VERSION ""

NS_ :

BS_:

BU_:

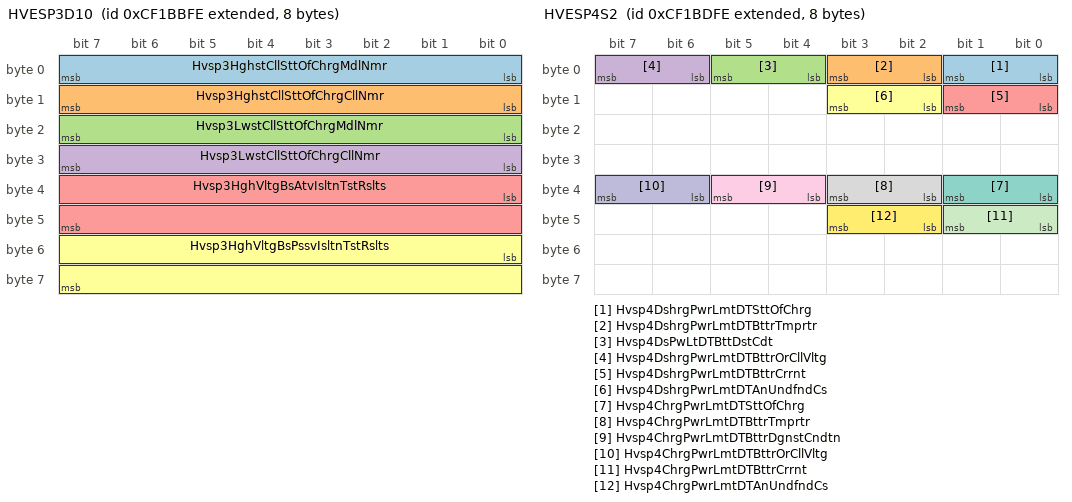
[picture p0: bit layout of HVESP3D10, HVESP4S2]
BO_ 2364652542 HVESP3D10: 8 Vector__XXX
 SG_ Hvsp3HghstCllSttOfChrgMdlNmr : 0|8@1+ (1,0) [0|250] "count" Vector__XXX
 SG_ Hvsp3HghstCllSttOfChrgCllNmr : 8|8@1+ (1,0) [0|250] "count" Vector__XXX
 SG_ Hvsp3LwstCllSttOfChrgMdlNmr : 16|8@1+ (1,0) [0|250] "count" Vector__XXX
 SG_ Hvsp3LwstCllSttOfChrgCllNmr : 24|8@1+ (1,0) [0|250] "count" Vector__XXX
 SG_ Hvsp3HghVltgBsAtvIsltnTstRslts : 32|16@1+ (0.1,0) [0|6425.5] "OhmPerV" Vector__XXX
 SG_ Hvsp3HghVltgBsPssvIsltnTstRslts : 48|16@1+ (0.1,0) [0|6425.5] "OhmPerV" Vector__XXX

BO_ 2364652798 HVESP3D11: 8 Vector__XXX
 SG_ Hvesp3ActualChargeRate : 32|16@1+ (0.05,0) [0|3212.75] "kW" Vector__XXX
 SG_ Hvsp3BsVltgNgtvTChsssGrndVltg : 0|16@1+ (0.05,0) [0|3212.75] "V" Vector__XXX
 SG_ Hvsp3VltgLvlNgtvTChsssGrndVltg : 16|16@1+ (0.05,0) [0|3212.75] "V" Vector__XXX

BO_ 2364653054 HVESP4S2: 8 Vector__XXX
 SG_ Hvsp4DshrgPwrLmtDTSttOfChrg : 0|2@1+ (1,0) [0|3] "" Vector__XXX
 SG_ Hvsp4DshrgPwrLmtDTBttrTmprtr : 2|2@1+ (1,0) [0|3] "" Vector__XXX
 SG_ Hvsp4DsPwLtDTBttDstCdt : 4|2@1+ (1,0) [0|3] "" Vector__XXX
 SG_ Hvsp4DshrgPwrLmtDTBttrOrCllVltg : 6|2@1+ (1,0) [0|3] "" Vector__XXX
 SG_ Hvsp4DshrgPwrLmtDTBttrCrrnt : 8|2@1+ (1,0) [0|3] "" Vector__XXX
 SG_ Hvsp4DshrgPwrLmtDTAnUndfndCs : 10|2@1+ (1,0) [0|3] "" Vector__XXX
 SG_ Hvsp4ChrgPwrLmtDTSttOfChrg : 32|2@1+ (1,0) [0|3] "" Vector__XXX
 SG_ Hvsp4ChrgPwrLmtDTBttrTmprtr : 34|2@1+ (1,0) [0|3] "" Vector__XXX
 SG_ Hvsp4ChrgPwrLmtDTBttrDgnstCndtn : 36|2@1+ (1,0) [0|3] "" Vector__XXX
 SG_ Hvsp4ChrgPwrLmtDTBttrOrCllVltg : 38|2@1+ (1,0) [0|3] "" Vector__XXX
 SG_ Hvsp4ChrgPwrLmtDTBttrCrrnt : 40|2@1+ (1,0) [0|3] "" Vector__XXX
 SG_ Hvsp4ChrgPwrLmtDTAnUndfndCs : 42|2@1+ (1,0) [0|3] "" Vector__XXX

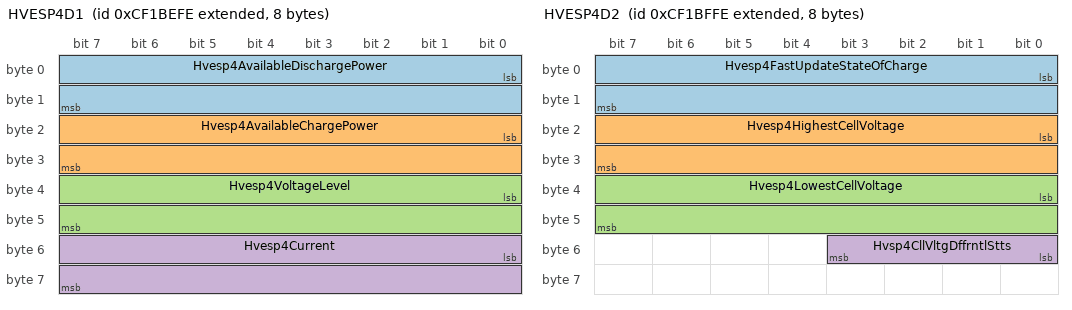
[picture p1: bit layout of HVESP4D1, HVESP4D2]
BO_ 2364653310 HVESP4D1: 8 Vector__XXX
 SG_ Hvesp4AvailableDischargePower : 0|16@1+ (0.05,0) [0|3212.75] "kW" Vector__XXX
 SG_ Hvesp4AvailableChargePower : 16|16@1+ (0.05,0) [0|3212.75] "kW" Vector__XXX
 SG_ Hvesp4VoltageLevel : 32|16@1+ (0.05,0) [0|3212.75] "V" Vector__XXX
 SG_ Hvesp4Current : 48|16@1+ (0.05,-1600) [-1600|1612.75] "A" Vector__XXX

BO_ 2364653566 HVESP4D2: 8 Vector__XXX
 SG_ Hvesp4FastUpdateStateOfCharge : 0|16@1+ (0.0015625,0) [0|100.3984375] "%" Vector__XXX
 SG_ Hvesp4HighestCellVoltage : 16|16@1+ (0.001,0) [0|64.255] "V" Vector__XXX
 SG_ Hvesp4LowestCellVoltage : 32|16@1+ (0.001,0) [0|64.255] "V" Vector__XXX
 SG_ Hvsp4CllVltgDffrntlStts : 48|4@1+ (1,0) [0|15] "" Vector__XXX

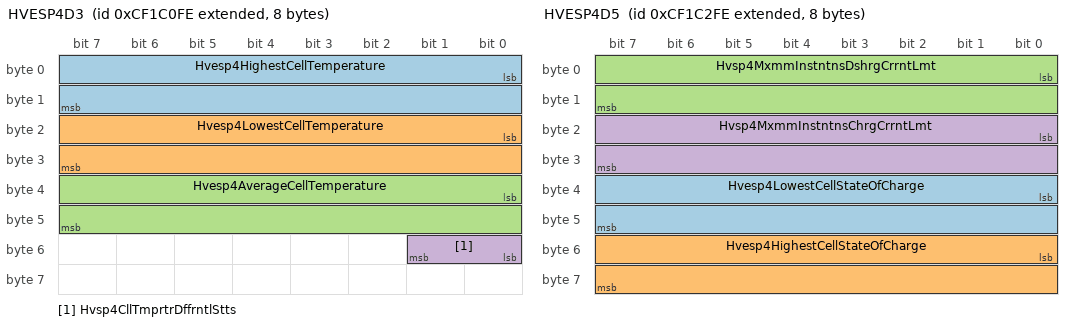
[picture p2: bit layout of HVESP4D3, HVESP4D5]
BO_ 2364653822 HVESP4D3: 8 Vector__XXX
 SG_ Hvesp4HighestCellTemperature : 0|16@1+ (0.03125,-273) [-273|1734.96875] "degC" Vector__XXX
 SG_ Hvesp4LowestCellTemperature : 16|16@1+ (0.03125,-273) [-273|1734.96875] "degC" Vector__XXX
 SG_ Hvesp4AverageCellTemperature : 32|16@1+ (0.03125,-273) [-273|1734.96875] "degC" Vector__XXX
 SG_ Hvsp4CllTmprtrDffrntlStts : 48|2@1+ (1,0) [0|3] "" Vector__XXX

BO_ 2364654078 HVESP4D4: 8 Vector__XXX
 SG_ Hvesp4DischargeCapacity : 0|16@1+ (0.01,0) [0|642.55] "Ah" Vector__XXX
 SG_ Hvesp4ChargeCapacity : 16|16@1+ (0.01,0) [0|642.55] "Ah" Vector__XXX
 SG_ Hvesp4CellBalancingCount : 32|16@1+ (1,0) [0|64255] "count" Vector__XXX

BO_ 2364654334 HVESP4D5: 8 Vector__XXX
 SG_ Hvesp4LowestCellStateOfCharge : 32|16@1+ (0.0015625,0) [0|100.3984375] "%" Vector__XXX
 SG_ Hvesp4HighestCellStateOfCharge : 48|16@1+ (0.0015625,0) [0|100.3984375] "%" Vector__XXX
 SG_ Hvsp4MxmmInstntnsDshrgCrrntLmt : 0|16@1+ (0.05,-1600) [-1600|0] "A" Vector__XXX
 SG_ Hvsp4MxmmInstntnsChrgCrrntLmt : 16|16@1+ (0.05,-1600) [0|1612.75] "A" Vector__XXX

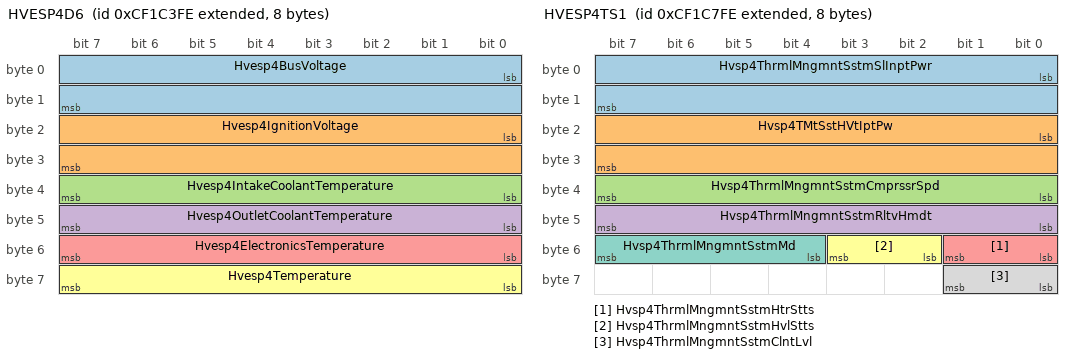
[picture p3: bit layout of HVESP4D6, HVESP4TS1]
BO_ 2364654590 HVESP4D6: 8 Vector__XXX
 SG_ Hvesp4BusVoltage : 0|16@1+ (0.05,0) [0|3212.75] "V" Vector__XXX
 SG_ Hvesp4IgnitionVoltage : 16|16@1+ (0.01,0) [0|642.55] "V" Vector__XXX
 SG_ Hvesp4IntakeCoolantTemperature : 32|8@1+ (1,-40) [-40|210] "degC" Vector__XXX
 SG_ Hvesp4OutletCoolantTemperature : 40|8@1+ (1,-40) [-40|210] "degC" Vector__XXX
 SG_ Hvesp4ElectronicsTemperature : 48|8@1+ (1,-40) [-40|210] "degC" Vector__XXX
 SG_ Hvesp4Temperature : 56|8@1+ (1,-40) [-40|210] "degC" Vector__XXX

BO_ 2364654846 HVESP4S1: 8 Vector__XXX
 SG_ Hvesp4HvilStatus : 20|2@1+ (1,0) [0|3] "" Vector__XXX
 SG_ Hvesp4InertiaSwitchStatus : 22|2@1+ (1,0) [0|3] "" Vector__XXX
 SG_ Hvesp4StateOfChargeStatus : 24|4@1+ (1,0) [0|15] "" Vector__XXX
 SG_ Hvesp4CellBalanceStatus : 28|2@1+ (1,0) [0|3] "" Vector__XXX
 SG_ Hvesp4CellBalancingActive : 30|2@1+ (1,0) [0|3] "" Vector__XXX
 SG_ Hvesp4InternalChargerStatus : 32|2@1+ (1,0) [0|3] "" Vector__XXX
 SG_ Hvesp4OperationalStatus : 44|4@1+ (1,0) [0|15] "" Vector__XXX
 SG_ Hvesp4Status1Counter : 52|4@1+ (1,0) [0|15] "" Vector__XXX
 SG_ Hvesp4Status1Crc : 56|8@1+ (1,0) [0|250] "count" Vector__XXX
 SG_ Hvsp4HghVltgBsPstvCnttrStt : 0|2@1+ (1,0) [0|3] "" Vector__XXX
 SG_ Hvsp4HghVltgBsNgtvCnttrStt : 2|2@1+ (1,0) [0|3] "" Vector__XXX
 SG_ Hvsp4HghVltgBsDsnntFrwrnng : 4|4@1+ (1,0) [0|15] "" Vector__XXX
 SG_ Hvsp4HghVltgBsPrChrgRlStt : 8|2@1+ (1,0) [0|3] "" Vector__XXX
 SG_ Hvsp4CntrOfPkCnttrStt : 10|2@1+ (1,0) [0|3] "" Vector__XXX
 SG_ Hvsp4HghVltgBsAtvIsltnTstStts : 12|4@1+ (1,0) [0|15] "" Vector__XXX
 SG_ Hvsp4HghVltgBsPssvIsltnTstStts : 16|4@1+ (1,0) [0|15] "" Vector__XXX
 SG_ Hvsp4HghVltgBsCnntnStts : 40|4@1+ (1,0) [0|15] "" Vector__XXX

BO_ 2364655102 HVESP4D7: 8 Vector__XXX
 SG_ Hvesp4DischargeEnergyCapacity : 0|24@1+ (0.001,0) [0|16449.535] "kWh" Vector__XXX
 SG_ Hvesp4ChargeEnergyCapacity : 24|24@1+ (0.001,0) [0|16449.535] "kWh" Vector__XXX
 SG_ Hvesp4MaximumChargeVoltageLimit : 48|16@1+ (0.05,0) [0|3212.75] "V" Vector__XXX

BO_ 2364655358 HVESP4MS1: 8 Vector__XXX
 SG_ Hvesp4Module1OperationalStatus : 0|2@1+ (1,0) [0|3] "" Vector__XXX
 SG_ Hvesp4Module2OperationalStatus : 2|2@1+ (1,0) [0|3] "" Vector__XXX
 SG_ Hvesp4Module3OperationalStatus : 4|2@1+ (1,0) [0|3] "" Vector__XXX
 SG_ Hvesp4Module4OperationalStatus : 6|2@1+ (1,0) [0|3] "" Vector__XXX
 SG_ Hvesp4Module5OperationalStatus : 8|2@1+ (1,0) [0|3] "" Vector__XXX
 SG_ Hvesp4Module6OperationalStatus : 10|2@1+ (1,0) [0|3] "" Vector__XXX
 SG_ Hvesp4Module7OperationalStatus : 12|2@1+ (1,0) [0|3] "" Vector__XXX
 SG_ Hvesp4Module8OperationalStatus : 14|2@1+ (1,0) [0|3] "" Vector__XXX
 SG_ Hvesp4Module9OperationalStatus : 16|2@1+ (1,0) [0|3] "" Vector__XXX
 SG_ Hvesp4Module10OperationalStatus : 18|2@1+ (1,0) [0|3] "" Vector__XXX
 SG_ Hvesp4Module11OperationalStatus : 20|2@1+ (1,0) [0|3] "" Vector__XXX
 SG_ Hvesp4Module12OperationalStatus : 22|2@1+ (1,0) [0|3] "" Vector__XXX
 SG_ Hvesp4Module13OperationalStatus : 24|2@1+ (1,0) [0|3] "" Vector__XXX
 SG_ Hvesp4Module14OperationalStatus : 26|2@1+ (1,0) [0|3] "" Vector__XXX
 SG_ Hvesp4Module15OperationalStatus : 28|2@1+ (1,0) [0|3] "" Vector__XXX
 SG_ Hvesp4Module16OperationalStatus : 30|2@1+ (1,0) [0|3] "" Vector__XXX
 SG_ Hvesp4Module17OperationalStatus : 32|2@1+ (1,0) [0|3] "" Vector__XXX
 SG_ Hvesp4Module18OperationalStatus : 34|2@1+ (1,0) [0|3] "" Vector__XXX
 SG_ Hvesp4Module19OperationalStatus : 36|2@1+ (1,0) [0|3] "" Vector__XXX
 SG_ Hvesp4Module20OperationalStatus : 38|2@1+ (1,0) [0|3] "" Vector__XXX
 SG_ Hvesp4Module21OperationalStatus : 40|2@1+ (1,0) [0|3] "" Vector__XXX
 SG_ Hvesp4Module22OperationalStatus : 42|2@1+ (1,0) [0|3] "" Vector__XXX
 SG_ Hvesp4Module23OperationalStatus : 44|2@1+ (1,0) [0|3] "" Vector__XXX
 SG_ Hvesp4Module24OperationalStatus : 46|2@1+ (1,0) [0|3] "" Vector__XXX
 SG_ Hvesp4Module25OperationalStatus : 48|2@1+ (1,0) [0|3] "" Vector__XXX
 SG_ Hvesp4Module26OperationalStatus : 50|2@1+ (1,0) [0|3] "" Vector__XXX
 SG_ Hvesp4Module27OperationalStatus : 52|2@1+ (1,0) [0|3] "" Vector__XXX
 SG_ Hvesp4Module28OperationalStatus : 54|2@1+ (1,0) [0|3] "" Vector__XXX
 SG_ Hvesp4Module29OperationalStatus : 56|2@1+ (1,0) [0|3] "" Vector__XXX
 SG_ Hvesp4Module30OperationalStatus : 58|2@1+ (1,0) [0|3] "" Vector__XXX
 SG_ Hvesp4Module31OperationalStatus : 60|2@1+ (1,0) [0|3] "" Vector__XXX
 SG_ Hvesp4Module32OperationalStatus : 62|2@1+ (1,0) [0|3] "" Vector__XXX

BO_ 2364655614 HVESP4TS1: 8 Vector__XXX
 SG_ Hvsp4ThrmlMngmntSstmSlInptPwr : 0|16@1+ (0.5,0) [0|32127.5] "W" Vector__XXX
 SG_ Hvsp4TMtSstHVtIptPw : 16|16@1+ (0.5,0) [0|32127.5] "W" Vector__XXX
 SG_ Hvsp4ThrmlMngmntSstmCmprssrSpd : 32|8@1+ (32,0) [0|8000] "rpm" Vector__XXX
 SG_ Hvsp4ThrmlMngmntSstmRltvHmdt : 40|8@1+ (0.4,0) [0|100] "%" Vector__XXX
 SG_ Hvsp4ThrmlMngmntSstmHtrStts : 48|2@1+ (1,0) [0|3] "" Vector__XXX
 SG_ Hvsp4ThrmlMngmntSstmHvlStts : 50|2@1+ (1,0) [0|3] "" Vector__XXX
 SG_ Hvsp4ThrmlMngmntSstmMd : 52|4@1+ (1,0) [0|15] "" Vector__XXX
 SG_ Hvsp4ThrmlMngmntSstmClntLvl : 56|2@1+ (1,0) [0|3] "" Vector__XXX

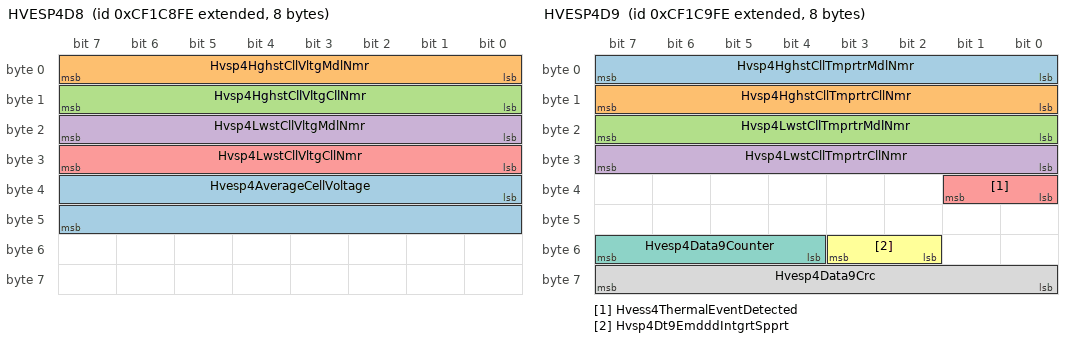
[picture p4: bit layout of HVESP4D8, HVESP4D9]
BO_ 2364655870 HVESP4D8: 8 Vector__XXX
 SG_ Hvesp4AverageCellVoltage : 32|16@1+ (0.001,0) [0|64.255] "V" Vector__XXX
 SG_ Hvsp4HghstCllVltgMdlNmr : 0|8@1+ (1,0) [0|250] "count" Vector__XXX
 SG_ Hvsp4HghstCllVltgCllNmr : 8|8@1+ (1,0) [0|250] "count" Vector__XXX
 SG_ Hvsp4LwstCllVltgMdlNmr : 16|8@1+ (1,0) [0|250] "count" Vector__XXX
 SG_ Hvsp4LwstCllVltgCllNmr : 24|8@1+ (1,0) [0|250] "count" Vector__XXX

BO_ 2364656126 HVESP4D9: 8 Vector__XXX
 SG_ Hvsp4HghstCllTmprtrMdlNmr : 0|8@1+ (1,0) [0|250] "count" Vector__XXX
 SG_ Hvsp4HghstCllTmprtrCllNmr : 8|8@1+ (1,0) [0|250] "count" Vector__XXX
 SG_ Hvsp4LwstCllTmprtrMdlNmr : 16|8@1+ (1,0) [0|250] "count" Vector__XXX
 SG_ Hvsp4LwstCllTmprtrCllNmr : 24|8@1+ (1,0) [0|250] "count" Vector__XXX
 SG_ Hvess4ThermalEventDetected : 32|2@1+ (1,0) [0|3] "" Vector__XXX
 SG_ Hvsp4Dt9EmdddIntgrtSpprt : 50|2@1+ (1,0) [0|3] "" Vector__XXX
 SG_ Hvesp4Data9Counter : 52|4@1+ (1,0) [0|15] "" Vector__XXX
 SG_ Hvesp4Data9Crc : 56|8@1+ (1,0) [0|250] "count" Vector__XXX

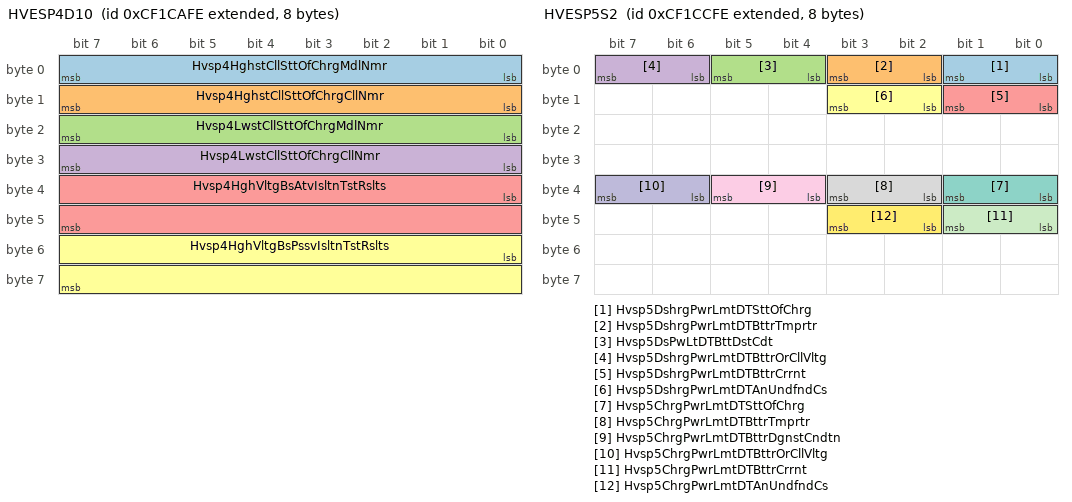
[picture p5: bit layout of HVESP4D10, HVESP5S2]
BO_ 2364656382 HVESP4D10: 8 Vector__XXX
 SG_ Hvsp4HghstCllSttOfChrgMdlNmr : 0|8@1+ (1,0) [0|250] "count" Vector__XXX
 SG_ Hvsp4HghstCllSttOfChrgCllNmr : 8|8@1+ (1,0) [0|250] "count" Vector__XXX
 SG_ Hvsp4LwstCllSttOfChrgMdlNmr : 16|8@1+ (1,0) [0|250] "count" Vector__XXX
 SG_ Hvsp4LwstCllSttOfChrgCllNmr : 24|8@1+ (1,0) [0|250] "count" Vector__XXX
 SG_ Hvsp4HghVltgBsAtvIsltnTstRslts : 32|16@1+ (0.1,0) [0|6425.5] "OhmPerV" Vector__XXX
 SG_ Hvsp4HghVltgBsPssvIsltnTstRslts : 48|16@1+ (0.1,0) [0|6425.5] "OhmPerV" Vector__XXX

BO_ 2364656638 HVESP4D11: 8 Vector__XXX
 SG_ Hvesp4ActualChargeRate : 32|16@1+ (0.05,0) [0|3212.75] "kW" Vector__XXX
 SG_ Hvsp4BsVltgNgtvTChsssGrndVltg : 0|16@1+ (0.05,0) [0|3212.75] "V" Vector__XXX
 SG_ Hvsp4VltgLvlNgtvTChsssGrndVltg : 16|16@1+ (0.05,0) [0|3212.75] "V" Vector__XXX

BO_ 2364656894 HVESP5S2: 8 Vector__XXX
 SG_ Hvsp5DshrgPwrLmtDTSttOfChrg : 0|2@1+ (1,0) [0|3] "" Vector__XXX
 SG_ Hvsp5DshrgPwrLmtDTBttrTmprtr : 2|2@1+ (1,0) [0|3] "" Vector__XXX
 SG_ Hvsp5DsPwLtDTBttDstCdt : 4|2@1+ (1,0) [0|3] "" Vector__XXX
 SG_ Hvsp5DshrgPwrLmtDTBttrOrCllVltg : 6|2@1+ (1,0) [0|3] "" Vector__XXX
 SG_ Hvsp5DshrgPwrLmtDTBttrCrrnt : 8|2@1+ (1,0) [0|3] "" Vector__XXX
 SG_ Hvsp5DshrgPwrLmtDTAnUndfndCs : 10|2@1+ (1,0) [0|3] "" Vector__XXX
 SG_ Hvsp5ChrgPwrLmtDTSttOfChrg : 32|2@1+ (1,0) [0|3] "" Vector__XXX
 SG_ Hvsp5ChrgPwrLmtDTBttrTmprtr : 34|2@1+ (1,0) [0|3] "" Vector__XXX
 SG_ Hvsp5ChrgPwrLmtDTBttrDgnstCndtn : 36|2@1+ (1,0) [0|3] "" Vector__XXX
 SG_ Hvsp5ChrgPwrLmtDTBttrOrCllVltg : 38|2@1+ (1,0) [0|3] "" Vector__XXX
 SG_ Hvsp5ChrgPwrLmtDTBttrCrrnt : 40|2@1+ (1,0) [0|3] "" Vector__XXX
 SG_ Hvsp5ChrgPwrLmtDTAnUndfndCs : 42|2@1+ (1,0) [0|3] "" Vector__XXX

BO_ 2364657150 HVESP5D1: 8 Vector__XXX
 SG_ Hvesp5AvailableDischargePower : 0|16@1+ (0.05,0) [0|3212.75] "kW" Vector__XXX
 SG_ Hvesp5AvailableChargePower : 16|16@1+ (0.05,0) [0|3212.75] "kW" Vector__XXX
 SG_ Hvesp5VoltageLevel : 32|16@1+ (0.05,0) [0|3212.75] "V" Vector__XXX
 SG_ Hvesp5Current : 48|16@1+ (0.05,-1600) [-1600|1612.75] "A" Vector__XXX

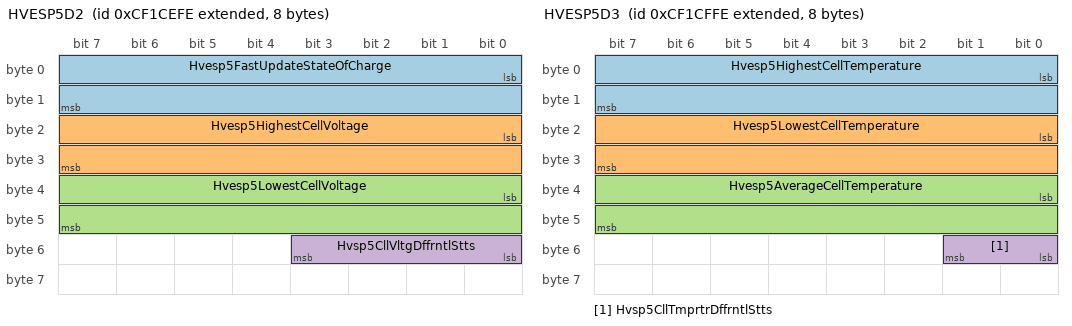
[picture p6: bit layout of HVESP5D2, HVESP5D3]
BO_ 2364657406 HVESP5D2: 8 Vector__XXX
 SG_ Hvesp5FastUpdateStateOfCharge : 0|16@1+ (0.0015625,0) [0|100.3984375] "%" Vector__XXX
 SG_ Hvesp5HighestCellVoltage : 16|16@1+ (0.001,0) [0|64.255] "V" Vector__XXX
 SG_ Hvesp5LowestCellVoltage : 32|16@1+ (0.001,0) [0|64.255] "V" Vector__XXX
 SG_ Hvsp5CllVltgDffrntlStts : 48|4@1+ (1,0) [0|15] "" Vector__XXX

BO_ 2364657662 HVESP5D3: 8 Vector__XXX
 SG_ Hvesp5HighestCellTemperature : 0|16@1+ (0.03125,-273) [-273|1734.96875] "degC" Vector__XXX
 SG_ Hvesp5LowestCellTemperature : 16|16@1+ (0.03125,-273) [-273|1734.96875] "degC" Vector__XXX
 SG_ Hvesp5AverageCellTemperature : 32|16@1+ (0.03125,-273) [-273|1734.96875] "degC" Vector__XXX
 SG_ Hvsp5CllTmprtrDffrntlStts : 48|2@1+ (1,0) [0|3] "" Vector__XXX

BO_ 2364657918 HVESP5D4: 8 Vector__XXX
 SG_ Hvesp5DischargeCapacity : 0|16@1+ (0.01,0) [0|642.55] "Ah" Vector__XXX
 SG_ Hvesp5ChargeCapacity : 16|16@1+ (0.01,0) [0|642.55] "Ah" Vector__XXX
 SG_ Hvesp5CellBalancingCount : 32|16@1+ (1,0) [0|64255] "count" Vector__XXX

BO_ 2364658174 HVESP5D5: 8 Vector__XXX
 SG_ Hvesp5LowestCellStateOfCharge : 32|16@1+ (0.0015625,0) [0|100.3984375] "%" Vector__XXX
 SG_ Hvesp5HighestCellStateOfCharge : 48|16@1+ (0.0015625,0) [0|100.3984375] "%" Vector__XXX
 SG_ Hvsp5MxmmInstntnsDshrgCrrntLmt : 0|16@1+ (0.05,-1600) [-1600|0] "A" Vector__XXX
 SG_ Hvsp5MxmmInstntnsChrgCrrntLmt : 16|16@1+ (0.05,-1600) [0|1612.75] "A" Vector__XXX

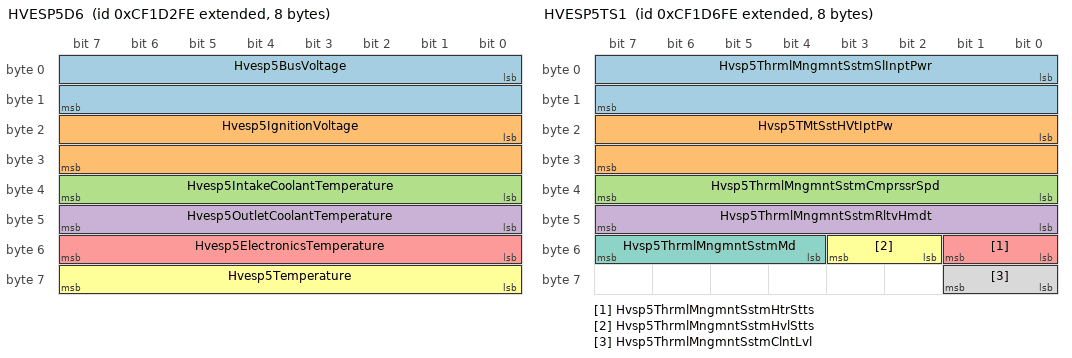
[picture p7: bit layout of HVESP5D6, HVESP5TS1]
BO_ 2364658430 HVESP5D6: 8 Vector__XXX
 SG_ Hvesp5BusVoltage : 0|16@1+ (0.05,0) [0|3212.75] "V" Vector__XXX
 SG_ Hvesp5IgnitionVoltage : 16|16@1+ (0.01,0) [0|642.55] "V" Vector__XXX
 SG_ Hvesp5IntakeCoolantTemperature : 32|8@1+ (1,-40) [-40|210] "degC" Vector__XXX
 SG_ Hvesp5OutletCoolantTemperature : 40|8@1+ (1,-40) [-40|210] "degC" Vector__XXX
 SG_ Hvesp5ElectronicsTemperature : 48|8@1+ (1,-40) [-40|210] "degC" Vector__XXX
 SG_ Hvesp5Temperature : 56|8@1+ (1,-40) [-40|210] "degC" Vector__XXX

BO_ 2364658686 HVESP5S1: 8 Vector__XXX
 SG_ Hvesp5HvilStatus : 20|2@1+ (1,0) [0|3] "" Vector__XXX
 SG_ Hvesp5InertiaSwitchStatus : 22|2@1+ (1,0) [0|3] "" Vector__XXX
 SG_ Hvesp5StateOfChargeStatus : 24|4@1+ (1,0) [0|15] "" Vector__XXX
 SG_ Hvesp5CellBalanceStatus : 28|2@1+ (1,0) [0|3] "" Vector__XXX
 SG_ Hvesp5CellBalancingActive : 30|2@1+ (1,0) [0|3] "" Vector__XXX
 SG_ Hvesp5InternalChargerStatus : 32|2@1+ (1,0) [0|3] "" Vector__XXX
 SG_ Hvesp5OperationalStatus : 44|4@1+ (1,0) [0|15] "" Vector__XXX
 SG_ Hvesp5Status1Counter : 52|4@1+ (1,0) [0|15] "" Vector__XXX
 SG_ Hvesp5Status1Crc : 56|8@1+ (1,0) [0|250] "count" Vector__XXX
 SG_ Hvsp5HghVltgBsPstvCnttrStt : 0|2@1+ (1,0) [0|3] "" Vector__XXX
 SG_ Hvsp5HghVltgBsNgtvCnttrStt : 2|2@1+ (1,0) [0|3] "" Vector__XXX
 SG_ Hvsp5HghVltgBsDsnntFrwrnng : 4|4@1+ (1,0) [0|15] "" Vector__XXX
 SG_ Hvsp5HghVltgBsPrChrgRlStt : 8|2@1+ (1,0) [0|3] "" Vector__XXX
 SG_ Hvsp5CntrOfPkCnttrStt : 10|2@1+ (1,0) [0|3] "" Vector__XXX
 SG_ Hvsp5HghVltgBsAtvIsltnTstStts : 12|4@1+ (1,0) [0|15] "" Vector__XXX
 SG_ Hvsp5HghVltgBsPssvIsltnTstStts : 16|4@1+ (1,0) [0|15] "" Vector__XXX
 SG_ Hvsp5HghVltgBsCnntnStts : 40|4@1+ (1,0) [0|15] "" Vector__XXX

BO_ 2364658942 HVESP5D7: 8 Vector__XXX
 SG_ Hvesp5DischargeEnergyCapacity : 0|24@1+ (0.001,0) [0|16449.535] "kWh" Vector__XXX
 SG_ Hvesp5ChargeEnergyCapacity : 24|24@1+ (0.001,0) [0|16449.535] "kWh" Vector__XXX
 SG_ Hvesp5MaximumChargeVoltageLimit : 48|16@1+ (0.05,0) [0|3212.75] "V" Vector__XXX

BO_ 2364659198 HVESP5MS1: 8 Vector__XXX
 SG_ Hvesp5Module1OperationalStatus : 0|2@1+ (1,0) [0|3] "" Vector__XXX
 SG_ Hvesp5Module2OperationalStatus : 2|2@1+ (1,0) [0|3] "" Vector__XXX
 SG_ Hvesp5Module3OperationalStatus : 4|2@1+ (1,0) [0|3] "" Vector__XXX
 SG_ Hvesp5Module4OperationalStatus : 6|2@1+ (1,0) [0|3] "" Vector__XXX
 SG_ Hvesp5Module5OperationalStatus : 8|2@1+ (1,0) [0|3] "" Vector__XXX
 SG_ Hvesp5Module6OperationalStatus : 10|2@1+ (1,0) [0|3] "" Vector__XXX
 SG_ Hvesp5Module7OperationalStatus : 12|2@1+ (1,0) [0|3] "" Vector__XXX
 SG_ Hvesp5Module8OperationalStatus : 14|2@1+ (1,0) [0|3] "" Vector__XXX
 SG_ Hvesp5Module9OperationalStatus : 16|2@1+ (1,0) [0|3] "" Vector__XXX
 SG_ Hvesp5Module10OperationalStatus : 18|2@1+ (1,0) [0|3] "" Vector__XXX
 SG_ Hvesp5Module11OperationalStatus : 20|2@1+ (1,0) [0|3] "" Vector__XXX
 SG_ Hvesp5Module12OperationalStatus : 22|2@1+ (1,0) [0|3] "" Vector__XXX
 SG_ Hvesp5Module13OperationalStatus : 24|2@1+ (1,0) [0|3] "" Vector__XXX
 SG_ Hvesp5Module14OperationalStatus : 26|2@1+ (1,0) [0|3] "" Vector__XXX
 SG_ Hvesp5Module15OperationalStatus : 28|2@1+ (1,0) [0|3] "" Vector__XXX
 SG_ Hvesp5Module16OperationalStatus : 30|2@1+ (1,0) [0|3] "" Vector__XXX
 SG_ Hvesp5Module17OperationalStatus : 32|2@1+ (1,0) [0|3] "" Vector__XXX
 SG_ Hvesp5Module18OperationalStatus : 34|2@1+ (1,0) [0|3] "" Vector__XXX
 SG_ Hvesp5Module19OperationalStatus : 36|2@1+ (1,0) [0|3] "" Vector__XXX
 SG_ Hvesp5Module20OperationalStatus : 38|2@1+ (1,0) [0|3] "" Vector__XXX
 SG_ Hvesp5Module21OperationalStatus : 40|2@1+ (1,0) [0|3] "" Vector__XXX
 SG_ Hvesp5Module22OperationalStatus : 42|2@1+ (1,0) [0|3] "" Vector__XXX
 SG_ Hvesp5Module23OperationalStatus : 44|2@1+ (1,0) [0|3] "" Vector__XXX
 SG_ Hvesp5Module24OperationalStatus : 46|2@1+ (1,0) [0|3] "" Vector__XXX
 SG_ Hvesp5Module25OperationalStatus : 48|2@1+ (1,0) [0|3] "" Vector__XXX
 SG_ Hvesp5Module26OperationalStatus : 50|2@1+ (1,0) [0|3] "" Vector__XXX
 SG_ Hvesp5Module27OperationalStatus : 52|2@1+ (1,0) [0|3] "" Vector__XXX
 SG_ Hvesp5Module28OperationalStatus : 54|2@1+ (1,0) [0|3] "" Vector__XXX
 SG_ Hvesp5Module29OperationalStatus : 56|2@1+ (1,0) [0|3] "" Vector__XXX
 SG_ Hvesp5Module30OperationalStatus : 58|2@1+ (1,0) [0|3] "" Vector__XXX
 SG_ Hvesp5Module31OperationalStatus : 60|2@1+ (1,0) [0|3] "" Vector__XXX
 SG_ Hvesp5Module32OperationalStatus : 62|2@1+ (1,0) [0|3] "" Vector__XXX

BO_ 2364659454 HVESP5TS1: 8 Vector__XXX
 SG_ Hvsp5ThrmlMngmntSstmSlInptPwr : 0|16@1+ (0.5,0) [0|32127.5] "W" Vector__XXX
 SG_ Hvsp5TMtSstHVtIptPw : 16|16@1+ (0.5,0) [0|32127.5] "W" Vector__XXX
 SG_ Hvsp5ThrmlMngmntSstmCmprssrSpd : 32|8@1+ (32,0) [0|8000] "rpm" Vector__XXX
 SG_ Hvsp5ThrmlMngmntSstmRltvHmdt : 40|8@1+ (0.4,0) [0|100] "%" Vector__XXX
 SG_ Hvsp5ThrmlMngmntSstmHtrStts : 48|2@1+ (1,0) [0|3] "" Vector__XXX
 SG_ Hvsp5ThrmlMngmntSstmHvlStts : 50|2@1+ (1,0) [0|3] "" Vector__XXX
 SG_ Hvsp5ThrmlMngmntSstmMd : 52|4@1+ (1,0) [0|15] "" Vector__XXX
 SG_ Hvsp5ThrmlMngmntSstmClntLvl : 56|2@1+ (1,0) [0|3] "" Vector__XXX

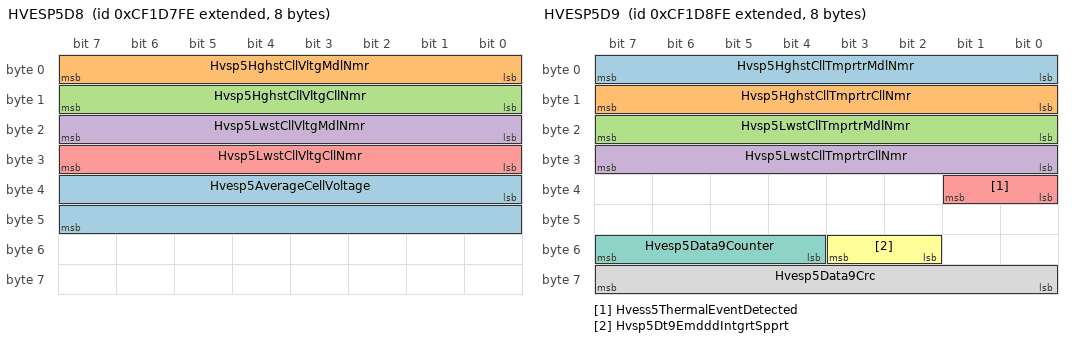
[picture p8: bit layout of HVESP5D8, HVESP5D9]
BO_ 2364659710 HVESP5D8: 8 Vector__XXX
 SG_ Hvesp5AverageCellVoltage : 32|16@1+ (0.001,0) [0|64.255] "V" Vector__XXX
 SG_ Hvsp5HghstCllVltgMdlNmr : 0|8@1+ (1,0) [0|250] "count" Vector__XXX
 SG_ Hvsp5HghstCllVltgCllNmr : 8|8@1+ (1,0) [0|250] "count" Vector__XXX
 SG_ Hvsp5LwstCllVltgMdlNmr : 16|8@1+ (1,0) [0|250] "count" Vector__XXX
 SG_ Hvsp5LwstCllVltgCllNmr : 24|8@1+ (1,0) [0|250] "count" Vector__XXX

BO_ 2364659966 HVESP5D9: 8 Vector__XXX
 SG_ Hvsp5HghstCllTmprtrMdlNmr : 0|8@1+ (1,0) [0|250] "count" Vector__XXX
 SG_ Hvsp5HghstCllTmprtrCllNmr : 8|8@1+ (1,0) [0|250] "count" Vector__XXX
 SG_ Hvsp5LwstCllTmprtrMdlNmr : 16|8@1+ (1,0) [0|250] "count" Vector__XXX
 SG_ Hvsp5LwstCllTmprtrCllNmr : 24|8@1+ (1,0) [0|250] "count" Vector__XXX
 SG_ Hvess5ThermalEventDetected : 32|2@1+ (1,0) [0|3] "" Vector__XXX
 SG_ Hvsp5Dt9EmdddIntgrtSpprt : 50|2@1+ (1,0) [0|3] "" Vector__XXX
 SG_ Hvesp5Data9Counter : 52|4@1+ (1,0) [0|15] "" Vector__XXX
 SG_ Hvesp5Data9Crc : 56|8@1+ (1,0) [0|250] "count" Vector__XXX

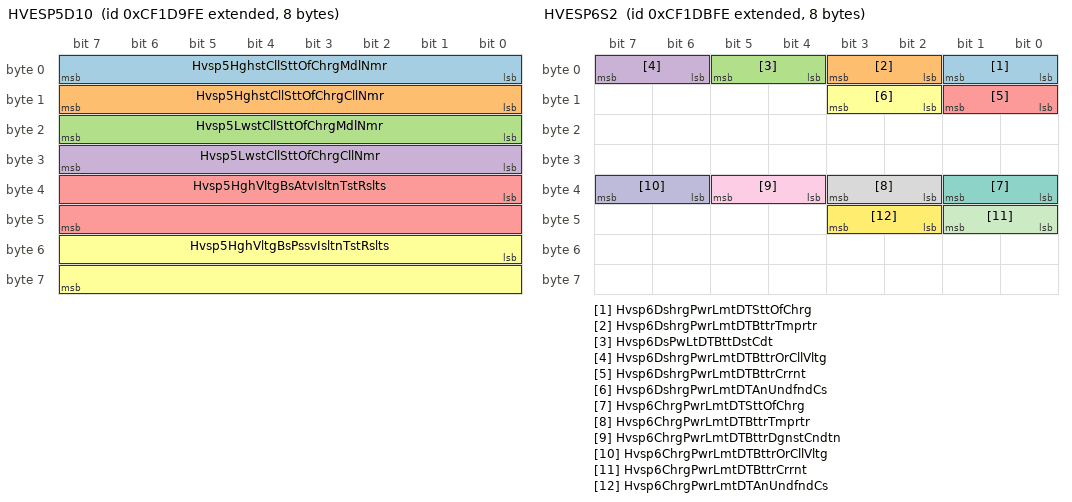
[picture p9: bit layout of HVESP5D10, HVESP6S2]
BO_ 2364660222 HVESP5D10: 8 Vector__XXX
 SG_ Hvsp5HghstCllSttOfChrgMdlNmr : 0|8@1+ (1,0) [0|250] "count" Vector__XXX
 SG_ Hvsp5HghstCllSttOfChrgCllNmr : 8|8@1+ (1,0) [0|250] "count" Vector__XXX
 SG_ Hvsp5LwstCllSttOfChrgMdlNmr : 16|8@1+ (1,0) [0|250] "count" Vector__XXX
 SG_ Hvsp5LwstCllSttOfChrgCllNmr : 24|8@1+ (1,0) [0|250] "count" Vector__XXX
 SG_ Hvsp5HghVltgBsAtvIsltnTstRslts : 32|16@1+ (0.1,0) [0|6425.5] "OhmPerV" Vector__XXX
 SG_ Hvsp5HghVltgBsPssvIsltnTstRslts : 48|16@1+ (0.1,0) [0|6425.5] "OhmPerV" Vector__XXX

BO_ 2364660478 HVESP5D11: 8 Vector__XXX
 SG_ Hvesp5ActualChargeRate : 32|16@1+ (0.05,0) [0|3212.75] "kW" Vector__XXX
 SG_ Hvsp5BsVltgNgtvTChsssGrndVltg : 0|16@1+ (0.05,0) [0|3212.75] "V" Vector__XXX
 SG_ Hvsp5VltgLvlNgtvTChsssGrndVltg : 16|16@1+ (0.05,0) [0|3212.75] "V" Vector__XXX

BO_ 2364660734 HVESP6S2: 8 Vector__XXX
 SG_ Hvsp6DshrgPwrLmtDTSttOfChrg : 0|2@1+ (1,0) [0|3] "" Vector__XXX
 SG_ Hvsp6DshrgPwrLmtDTBttrTmprtr : 2|2@1+ (1,0) [0|3] "" Vector__XXX
 SG_ Hvsp6DsPwLtDTBttDstCdt : 4|2@1+ (1,0) [0|3] "" Vector__XXX
 SG_ Hvsp6DshrgPwrLmtDTBttrOrCllVltg : 6|2@1+ (1,0) [0|3] "" Vector__XXX
 SG_ Hvsp6DshrgPwrLmtDTBttrCrrnt : 8|2@1+ (1,0) [0|3] "" Vector__XXX
 SG_ Hvsp6DshrgPwrLmtDTAnUndfndCs : 10|2@1+ (1,0) [0|3] "" Vector__XXX
 SG_ Hvsp6ChrgPwrLmtDTSttOfChrg : 32|2@1+ (1,0) [0|3] "" Vector__XXX
 SG_ Hvsp6ChrgPwrLmtDTBttrTmprtr : 34|2@1+ (1,0) [0|3] "" Vector__XXX
 SG_ Hvsp6ChrgPwrLmtDTBttrDgnstCndtn : 36|2@1+ (1,0) [0|3] "" Vector__XXX
 SG_ Hvsp6ChrgPwrLmtDTBttrOrCllVltg : 38|2@1+ (1,0) [0|3] "" Vector__XXX
 SG_ Hvsp6ChrgPwrLmtDTBttrCrrnt : 40|2@1+ (1,0) [0|3] "" Vector__XXX
 SG_ Hvsp6ChrgPwrLmtDTAnUndfndCs : 42|2@1+ (1,0) [0|3] "" Vector__XXX

BO_ 2364660990 HVESP6D1: 8 Vector__XXX
 SG_ Hvesp6AvailableDischargePower : 0|16@1+ (0.05,0) [0|3212.75] "kW" Vector__XXX
 SG_ Hvesp6AvailableChargePower : 16|16@1+ (0.05,0) [0|3212.75] "kW" Vector__XXX
 SG_ Hvesp6VoltageLevel : 32|16@1+ (0.05,0) [0|3212.75] "V" Vector__XXX
 SG_ Hvesp6Current : 48|16@1+ (0.05,-1600) [-1600|1612.75] "A" Vector__XXX

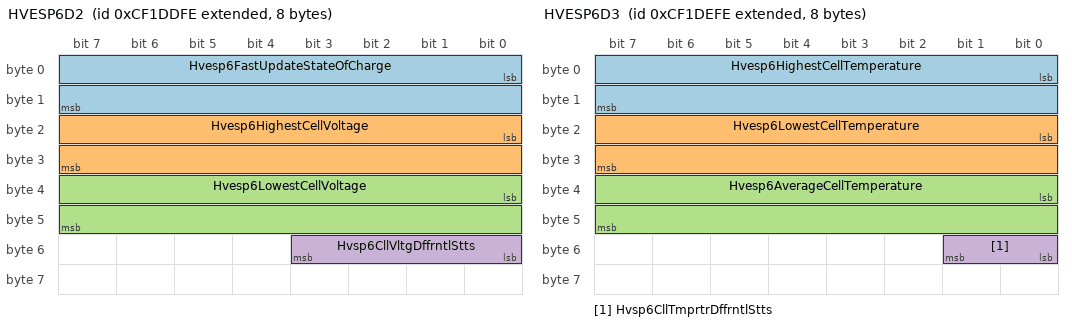
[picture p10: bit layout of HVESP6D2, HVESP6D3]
BO_ 2364661246 HVESP6D2: 8 Vector__XXX
 SG_ Hvesp6FastUpdateStateOfCharge : 0|16@1+ (0.0015625,0) [0|100.3984375] "%" Vector__XXX
 SG_ Hvesp6HighestCellVoltage : 16|16@1+ (0.001,0) [0|64.255] "V" Vector__XXX
 SG_ Hvesp6LowestCellVoltage : 32|16@1+ (0.001,0) [0|64.255] "V" Vector__XXX
 SG_ Hvsp6CllVltgDffrntlStts : 48|4@1+ (1,0) [0|15] "" Vector__XXX

BO_ 2364661502 HVESP6D3: 8 Vector__XXX
 SG_ Hvesp6HighestCellTemperature : 0|16@1+ (0.03125,-273) [-273|1734.96875] "degC" Vector__XXX
 SG_ Hvesp6LowestCellTemperature : 16|16@1+ (0.03125,-273) [-273|1734.96875] "degC" Vector__XXX
 SG_ Hvesp6AverageCellTemperature : 32|16@1+ (0.03125,-273) [-273|1734.96875] "degC" Vector__XXX
 SG_ Hvsp6CllTmprtrDffrntlStts : 48|2@1+ (1,0) [0|3] "" Vector__XXX

BO_ 2364661758 HVESP6D4: 8 Vector__XXX
 SG_ Hvesp6DischargeCapacity : 0|16@1+ (0.01,0) [0|642.55] "Ah" Vector__XXX
 SG_ Hvesp6ChargeCapacity : 16|16@1+ (0.01,0) [0|642.55] "Ah" Vector__XXX
 SG_ Hvesp6CellBalancingCount : 32|16@1+ (1,0) [0|64255] "count" Vector__XXX

BO_ 2364662014 HVESP6D5: 8 Vector__XXX
 SG_ Hvesp6LowestCellStateOfCharge : 32|16@1+ (0.0015625,0) [0|100.3984375] "%" Vector__XXX
 SG_ Hvesp6HighestCellStateOfCharge : 48|16@1+ (0.0015625,0) [0|100.3984375] "%" Vector__XXX
 SG_ Hvsp6MxmmInstntnsDshrgCrrntLmt : 0|16@1+ (0.05,-1600) [-1600|0] "A" Vector__XXX
 SG_ Hvsp6MxmmInstntnsChrgCrrntLmt : 16|16@1+ (0.05,-1600) [0|1612.75] "A" Vector__XXX

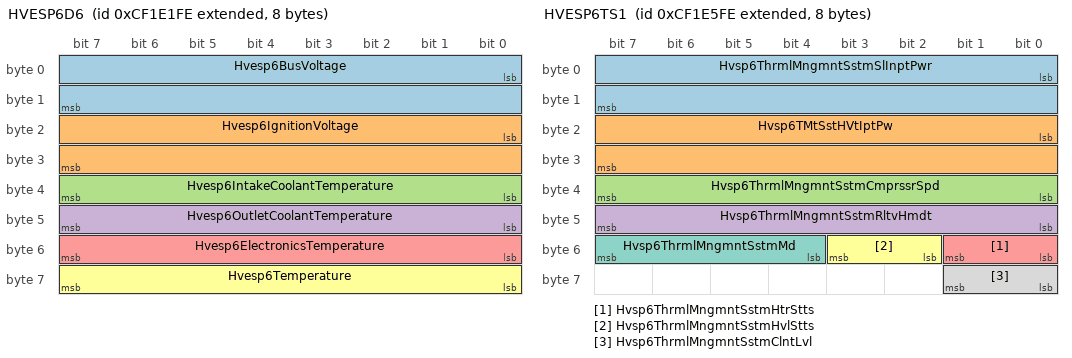
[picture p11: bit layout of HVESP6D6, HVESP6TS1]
BO_ 2364662270 HVESP6D6: 8 Vector__XXX
 SG_ Hvesp6BusVoltage : 0|16@1+ (0.05,0) [0|3212.75] "V" Vector__XXX
 SG_ Hvesp6IgnitionVoltage : 16|16@1+ (0.01,0) [0|642.55] "V" Vector__XXX
 SG_ Hvesp6IntakeCoolantTemperature : 32|8@1+ (1,-40) [-40|210] "degC" Vector__XXX
 SG_ Hvesp6OutletCoolantTemperature : 40|8@1+ (1,-40) [-40|210] "degC" Vector__XXX
 SG_ Hvesp6ElectronicsTemperature : 48|8@1+ (1,-40) [-40|210] "degC" Vector__XXX
 SG_ Hvesp6Temperature : 56|8@1+ (1,-40) [-40|210] "degC" Vector__XXX

BO_ 2364662526 HVESP6S1: 8 Vector__XXX
 SG_ Hvesp6HvilStatus : 20|2@1+ (1,0) [0|3] "" Vector__XXX
 SG_ Hvesp6InertiaSwitchStatus : 22|2@1+ (1,0) [0|3] "" Vector__XXX
 SG_ Hvesp6StateOfChargeStatus : 24|4@1+ (1,0) [0|15] "" Vector__XXX
 SG_ Hvesp6CellBalanceStatus : 28|2@1+ (1,0) [0|3] "" Vector__XXX
 SG_ Hvesp6CellBalancingActive : 30|2@1+ (1,0) [0|3] "" Vector__XXX
 SG_ Hvesp6InternalChargerStatus : 32|2@1+ (1,0) [0|3] "" Vector__XXX
 SG_ Hvesp6OperationalStatus : 44|4@1+ (1,0) [0|15] "" Vector__XXX
 SG_ Hvesp6Status1Counter : 52|4@1+ (1,0) [0|15] "" Vector__XXX
 SG_ Hvesp6Status1Crc : 56|8@1+ (1,0) [0|250] "count" Vector__XXX
 SG_ Hvsp6HghVltgBsPstvCnttrStt : 0|2@1+ (1,0) [0|3] "" Vector__XXX
 SG_ Hvsp6HghVltgBsNgtvCnttrStt : 2|2@1+ (1,0) [0|3] "" Vector__XXX
 SG_ Hvsp6HghVltgBsDsnntFrwrnng : 4|4@1+ (1,0) [0|15] "" Vector__XXX
 SG_ Hvsp6HghVltgBsPrChrgRlStt : 8|2@1+ (1,0) [0|3] "" Vector__XXX
 SG_ Hvsp6CntrOfPkCnttrStt : 10|2@1+ (1,0) [0|3] "" Vector__XXX
 SG_ Hvsp6HghVltgBsAtvIsltnTstStts : 12|4@1+ (1,0) [0|15] "" Vector__XXX
 SG_ Hvsp6HghVltgBsPssvIsltnTstStts : 16|4@1+ (1,0) [0|15] "" Vector__XXX
 SG_ Hvsp6HghVltgBsCnntnStts : 40|4@1+ (1,0) [0|15] "" Vector__XXX

BO_ 2364662782 HVESP6D7: 8 Vector__XXX
 SG_ Hvesp6DischargeEnergyCapacity : 0|24@1+ (0.001,0) [0|16449.535] "kWh" Vector__XXX
 SG_ Hvesp6ChargeEnergyCapacity : 24|24@1+ (0.001,0) [0|16449.535] "kWh" Vector__XXX
 SG_ Hvesp6MaximumChargeVoltageLimit : 48|16@1+ (0.05,0) [0|3212.75] "V" Vector__XXX

BO_ 2364663038 HVESP6MS1: 8 Vector__XXX
 SG_ Hvesp6Module1OperationalStatus : 0|2@1+ (1,0) [0|3] "" Vector__XXX
 SG_ Hvesp6Module2OperationalStatus : 2|2@1+ (1,0) [0|3] "" Vector__XXX
 SG_ Hvesp6Module3OperationalStatus : 4|2@1+ (1,0) [0|3] "" Vector__XXX
 SG_ Hvesp6Module4OperationalStatus : 6|2@1+ (1,0) [0|3] "" Vector__XXX
 SG_ Hvesp6Module5OperationalStatus : 8|2@1+ (1,0) [0|3] "" Vector__XXX
 SG_ Hvesp6Module6OperationalStatus : 10|2@1+ (1,0) [0|3] "" Vector__XXX
 SG_ Hvesp6Module7OperationalStatus : 12|2@1+ (1,0) [0|3] "" Vector__XXX
 SG_ Hvesp6Module8OperationalStatus : 14|2@1+ (1,0) [0|3] "" Vector__XXX
 SG_ Hvesp6Module9OperationalStatus : 16|2@1+ (1,0) [0|3] "" Vector__XXX
 SG_ Hvesp6Module10OperationalStatus : 18|2@1+ (1,0) [0|3] "" Vector__XXX
 SG_ Hvesp6Module11OperationalStatus : 20|2@1+ (1,0) [0|3] "" Vector__XXX
 SG_ Hvesp6Module12OperationalStatus : 22|2@1+ (1,0) [0|3] "" Vector__XXX
 SG_ Hvesp6Module13OperationalStatus : 24|2@1+ (1,0) [0|3] "" Vector__XXX
 SG_ Hvesp6Module14OperationalStatus : 26|2@1+ (1,0) [0|3] "" Vector__XXX
 SG_ Hvesp6Module15OperationalStatus : 28|2@1+ (1,0) [0|3] "" Vector__XXX
 SG_ Hvesp6Module16OperationalStatus : 30|2@1+ (1,0) [0|3] "" Vector__XXX
 SG_ Hvesp6Module17OperationalStatus : 32|2@1+ (1,0) [0|3] "" Vector__XXX
 SG_ Hvesp6Module18OperationalStatus : 34|2@1+ (1,0) [0|3] "" Vector__XXX
 SG_ Hvesp6Module19OperationalStatus : 36|2@1+ (1,0) [0|3] "" Vector__XXX
 SG_ Hvesp6Module20OperationalStatus : 38|2@1+ (1,0) [0|3] "" Vector__XXX
 SG_ Hvesp6Module21OperationalStatus : 40|2@1+ (1,0) [0|3] "" Vector__XXX
 SG_ Hvesp6Module22OperationalStatus : 42|2@1+ (1,0) [0|3] "" Vector__XXX
 SG_ Hvesp6Module23OperationalStatus : 44|2@1+ (1,0) [0|3] "" Vector__XXX
 SG_ Hvesp6Module24OperationalStatus : 46|2@1+ (1,0) [0|3] "" Vector__XXX
 SG_ Hvesp6Module25OperationalStatus : 48|2@1+ (1,0) [0|3] "" Vector__XXX
 SG_ Hvesp6Module26OperationalStatus : 50|2@1+ (1,0) [0|3] "" Vector__XXX
 SG_ Hvesp6Module27OperationalStatus : 52|2@1+ (1,0) [0|3] "" Vector__XXX
 SG_ Hvesp6Module28OperationalStatus : 54|2@1+ (1,0) [0|3] "" Vector__XXX
 SG_ Hvesp6Module29OperationalStatus : 56|2@1+ (1,0) [0|3] "" Vector__XXX
 SG_ Hvesp6Module30OperationalStatus : 58|2@1+ (1,0) [0|3] "" Vector__XXX
 SG_ Hvesp6Module31OperationalStatus : 60|2@1+ (1,0) [0|3] "" Vector__XXX
 SG_ Hvesp6Module32OperationalStatus : 62|2@1+ (1,0) [0|3] "" Vector__XXX

BO_ 2364663294 HVESP6TS1: 8 Vector__XXX
 SG_ Hvsp6ThrmlMngmntSstmSlInptPwr : 0|16@1+ (0.5,0) [0|32127.5] "W" Vector__XXX
 SG_ Hvsp6TMtSstHVtIptPw : 16|16@1+ (0.5,0) [0|32127.5] "W" Vector__XXX
 SG_ Hvsp6ThrmlMngmntSstmCmprssrSpd : 32|8@1+ (32,0) [0|8000] "rpm" Vector__XXX
 SG_ Hvsp6ThrmlMngmntSstmRltvHmdt : 40|8@1+ (0.4,0) [0|100] "%" Vector__XXX
 SG_ Hvsp6ThrmlMngmntSstmHtrStts : 48|2@1+ (1,0) [0|3] "" Vector__XXX
 SG_ Hvsp6ThrmlMngmntSstmHvlStts : 50|2@1+ (1,0) [0|3] "" Vector__XXX
 SG_ Hvsp6ThrmlMngmntSstmMd : 52|4@1+ (1,0) [0|15] "" Vector__XXX
 SG_ Hvsp6ThrmlMngmntSstmClntLvl : 56|2@1+ (1,0) [0|3] "" Vector__XXX

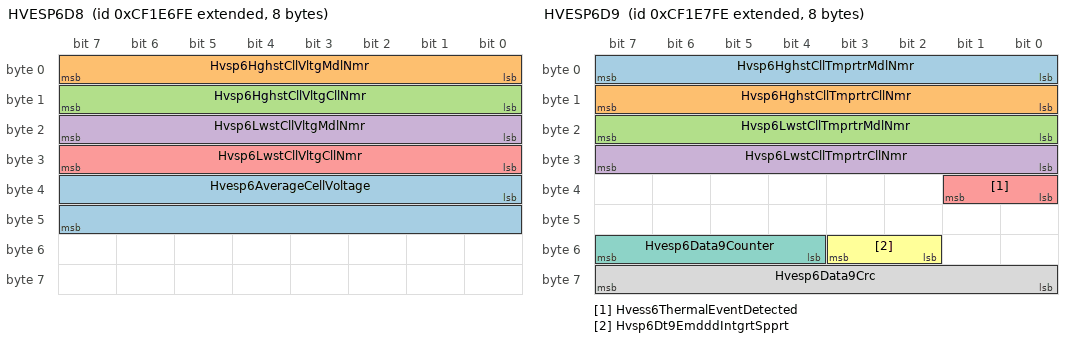
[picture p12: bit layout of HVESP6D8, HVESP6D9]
BO_ 2364663550 HVESP6D8: 8 Vector__XXX
 SG_ Hvesp6AverageCellVoltage : 32|16@1+ (0.001,0) [0|64.255] "V" Vector__XXX
 SG_ Hvsp6HghstCllVltgMdlNmr : 0|8@1+ (1,0) [0|250] "count" Vector__XXX
 SG_ Hvsp6HghstCllVltgCllNmr : 8|8@1+ (1,0) [0|250] "count" Vector__XXX
 SG_ Hvsp6LwstCllVltgMdlNmr : 16|8@1+ (1,0) [0|250] "count" Vector__XXX
 SG_ Hvsp6LwstCllVltgCllNmr : 24|8@1+ (1,0) [0|250] "count" Vector__XXX

BO_ 2364663806 HVESP6D9: 8 Vector__XXX
 SG_ Hvsp6HghstCllTmprtrMdlNmr : 0|8@1+ (1,0) [0|250] "count" Vector__XXX
 SG_ Hvsp6HghstCllTmprtrCllNmr : 8|8@1+ (1,0) [0|250] "count" Vector__XXX
 SG_ Hvsp6LwstCllTmprtrMdlNmr : 16|8@1+ (1,0) [0|250] "count" Vector__XXX
 SG_ Hvsp6LwstCllTmprtrCllNmr : 24|8@1+ (1,0) [0|250] "count" Vector__XXX
 SG_ Hvess6ThermalEventDetected : 32|2@1+ (1,0) [0|3] "" Vector__XXX
 SG_ Hvsp6Dt9EmdddIntgrtSpprt : 50|2@1+ (1,0) [0|3] "" Vector__XXX
 SG_ Hvesp6Data9Counter : 52|4@1+ (1,0) [0|15] "" Vector__XXX
 SG_ Hvesp6Data9Crc : 56|8@1+ (1,0) [0|250] "count" Vector__XXX

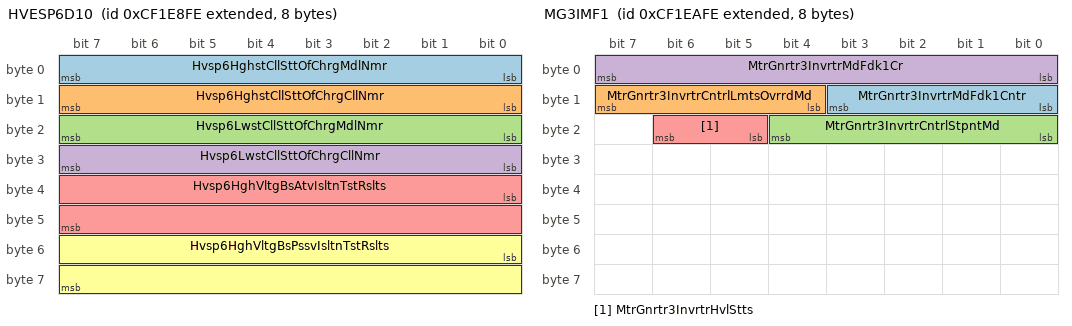
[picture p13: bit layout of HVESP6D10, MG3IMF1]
BO_ 2364664062 HVESP6D10: 8 Vector__XXX
 SG_ Hvsp6HghstCllSttOfChrgMdlNmr : 0|8@1+ (1,0) [0|250] "count" Vector__XXX
 SG_ Hvsp6HghstCllSttOfChrgCllNmr : 8|8@1+ (1,0) [0|250] "count" Vector__XXX
 SG_ Hvsp6LwstCllSttOfChrgMdlNmr : 16|8@1+ (1,0) [0|250] "count" Vector__XXX
 SG_ Hvsp6LwstCllSttOfChrgCllNmr : 24|8@1+ (1,0) [0|250] "count" Vector__XXX
 SG_ Hvsp6HghVltgBsAtvIsltnTstRslts : 32|16@1+ (0.1,0) [0|6425.5] "OhmPerV" Vector__XXX
 SG_ Hvsp6HghVltgBsPssvIsltnTstRslts : 48|16@1+ (0.1,0) [0|6425.5] "OhmPerV" Vector__XXX

BO_ 2364664318 HVESP6D11: 8 Vector__XXX
 SG_ Hvesp6ActualChargeRate : 32|16@1+ (0.05,0) [0|3212.75] "kW" Vector__XXX
 SG_ Hvsp6BsVltgNgtvTChsssGrndVltg : 0|16@1+ (0.05,0) [0|3212.75] "V" Vector__XXX
 SG_ Hvsp6VltgLvlNgtvTChsssGrndVltg : 16|16@1+ (0.05,0) [0|3212.75] "V" Vector__XXX

BO_ 2364664574 MG3IMF1: 8 Vector__XXX
 SG_ MtrGnrtr3InvrtrMdFdk1Cntr : 8|4@1+ (1,0) [0|15] "" Vector__XXX
 SG_ MtrGnrtr3InvrtrCntrlLmtsOvrrdMd : 12|4@1+ (1,0) [0|15] "" Vector__XXX
 SG_ MtrGnrtr3InvrtrCntrlStpntMd : 16|5@1+ (1,0) [0|31] "" Vector__XXX
 SG_ MtrGnrtr3InvrtrMdFdk1Cr : 0|8@1+ (1,0) [0|250] "count" Vector__XXX
 SG_ MtrGnrtr3InvrtrHvlStts : 21|2@1+ (1,0) [0|3] "" Vector__XXX

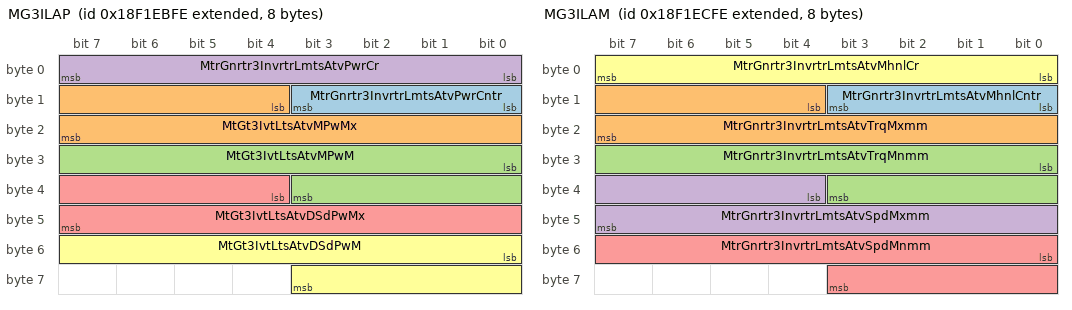
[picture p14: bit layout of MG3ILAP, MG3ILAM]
BO_ 2565991422 MG3ILAP: 8 Vector__XXX
 SG_ MtrGnrtr3InvrtrLmtsAtvPwrCntr : 8|4@1+ (1,0) [0|15] "" Vector__XXX
 SG_ MtGt3IvtLtsAtvMPwMx : 12|12@1+ (0.0625,-125) [-125|125.9375] "%" Vector__XXX
 SG_ MtGt3IvtLtsAtvMPwM : 24|12@1+ (0.0625,-125) [-125|125.9375] "%" Vector__XXX
 SG_ MtrGnrtr3InvrtrLmtsAtvPwrCr : 0|8@1+ (1,0) [0|250] "count" Vector__XXX
 SG_ MtGt3IvtLtsAtvDSdPwMx : 36|12@1+ (0.0625,-125) [-125|125.9375] "%" Vector__XXX
 SG_ MtGt3IvtLtsAtvDSdPwM : 48|12@1+ (0.0625,-125) [-125|125.9375] "%" Vector__XXX

BO_ 2565991678 MG3ILAM: 8 Vector__XXX
 SG_ MtrGnrtr3InvrtrLmtsAtvMhnlCntr : 8|4@1+ (1,0) [0|15] "" Vector__XXX
 SG_ MtrGnrtr3InvrtrLmtsAtvTrqMxmm : 12|12@1+ (0.0625,-125) [-125|125.9375] "%" Vector__XXX
 SG_ MtrGnrtr3InvrtrLmtsAtvTrqMnmm : 24|12@1+ (0.0625,-125) [-125|125.9375] "%" Vector__XXX
 SG_ MtrGnrtr3InvrtrLmtsAtvSpdMxmm : 36|12@1+ (0.0625,-125) [-125|125.9375] "%" Vector__XXX
 SG_ MtrGnrtr3InvrtrLmtsAtvSpdMnmm : 48|12@1+ (0.0625,-125) [-125|125.9375] "%" Vector__XXX
 SG_ MtrGnrtr3InvrtrLmtsAtvMhnlCr : 0|8@1+ (1,0) [0|250] "count" Vector__XXX

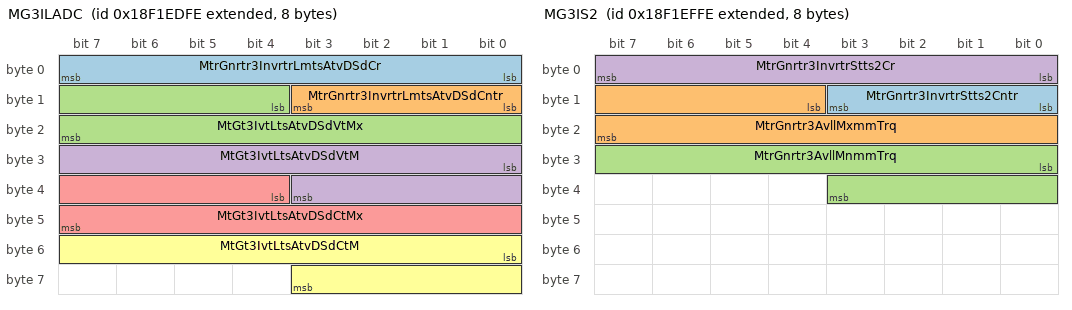
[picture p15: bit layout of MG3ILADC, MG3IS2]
BO_ 2565991934 MG3ILADC: 8 Vector__XXX
 SG_ MtrGnrtr3InvrtrLmtsAtvDSdCr : 0|8@1+ (1,0) [0|250] "count" Vector__XXX
 SG_ MtrGnrtr3InvrtrLmtsAtvDSdCntr : 8|4@1+ (1,0) [0|15] "" Vector__XXX
 SG_ MtGt3IvtLtsAtvDSdVtMx : 12|12@1+ (0.0625,-125) [-125|125.9375] "%" Vector__XXX
 SG_ MtGt3IvtLtsAtvDSdVtM : 24|12@1+ (0.0625,-125) [-125|125.9375] "%" Vector__XXX
 SG_ MtGt3IvtLtsAtvDSdCtMx : 36|12@1+ (0.0625,-125) [-125|125.9375] "%" Vector__XXX
 SG_ MtGt3IvtLtsAtvDSdCtM : 48|12@1+ (0.0625,-125) [-125|125.9375] "%" Vector__XXX

BO_ 2565992190 MG3ILV: 8 Vector__XXX
 SG_ MtrGnrtr3InvrtrSwthdIgntnVltg : 0|16@1+ (0.05,0) [0|3212.75] "V" Vector__XXX
 SG_ MtrGnrtr3InvrtrUnswthdSlVltg : 16|16@1+ (0.05,0) [0|3212.75] "V" Vector__XXX

BO_ 2565992446 MG3IS2: 8 Vector__XXX
 SG_ MtrGnrtr3InvrtrStts2Cntr : 8|4@1+ (1,0) [0|15] "" Vector__XXX
 SG_ MtrGnrtr3AvllMxmmTrq : 12|12@1+ (0.0625,-125) [-125|125.9375] "%" Vector__XXX
 SG_ MtrGnrtr3AvllMnmmTrq : 24|12@1+ (0.0625,-125) [-125|125.9375] "%" Vector__XXX
 SG_ MtrGnrtr3InvrtrStts2Cr : 0|8@1+ (1,0) [0|250] "count" Vector__XXX

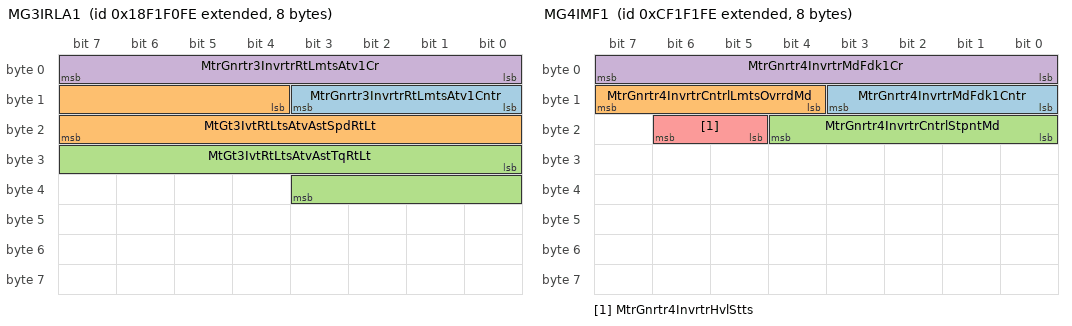
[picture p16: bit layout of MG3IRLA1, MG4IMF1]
BO_ 2565992702 MG3IRLA1: 8 Vector__XXX
 SG_ MtrGnrtr3InvrtrRtLmtsAtv1Cntr : 8|4@1+ (1,0) [0|15] "" Vector__XXX
 SG_ MtGt3IvtRtLtsAtvAstSpdRtLt : 12|12@1+ (0.25,0) [0|1003.75] "%/s" Vector__XXX
 SG_ MtGt3IvtRtLtsAtvAstTqRtLt : 24|12@1+ (2,0) [0|8030] "%/s" Vector__XXX
 SG_ MtrGnrtr3InvrtrRtLmtsAtv1Cr : 0|8@1+ (1,0) [0|250] "count" Vector__XXX

BO_ 2364666366 MG4IMF1: 8 Vector__XXX
 SG_ MtrGnrtr4InvrtrMdFdk1Cntr : 8|4@1+ (1,0) [0|15] "" Vector__XXX
 SG_ MtrGnrtr4InvrtrCntrlLmtsOvrrdMd : 12|4@1+ (1,0) [0|15] "" Vector__XXX
 SG_ MtrGnrtr4InvrtrCntrlStpntMd : 16|5@1+ (1,0) [0|31] "" Vector__XXX
 SG_ MtrGnrtr4InvrtrMdFdk1Cr : 0|8@1+ (1,0) [0|250] "count" Vector__XXX
 SG_ MtrGnrtr4InvrtrHvlStts : 21|2@1+ (1,0) [0|3] "" Vector__XXX

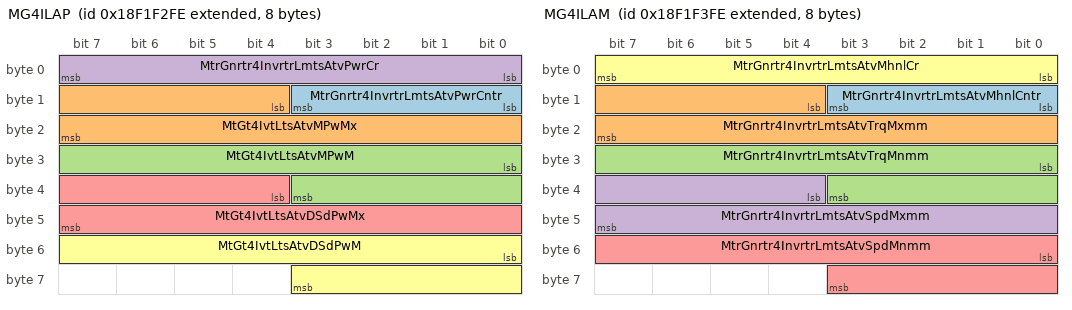
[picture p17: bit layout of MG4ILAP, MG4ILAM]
BO_ 2565993214 MG4ILAP: 8 Vector__XXX
 SG_ MtrGnrtr4InvrtrLmtsAtvPwrCntr : 8|4@1+ (1,0) [0|15] "" Vector__XXX
 SG_ MtGt4IvtLtsAtvMPwMx : 12|12@1+ (0.0625,-125) [-125|125.9375] "%" Vector__XXX
 SG_ MtGt4IvtLtsAtvMPwM : 24|12@1+ (0.0625,-125) [-125|125.9375] "%" Vector__XXX
 SG_ MtrGnrtr4InvrtrLmtsAtvPwrCr : 0|8@1+ (1,0) [0|250] "count" Vector__XXX
 SG_ MtGt4IvtLtsAtvDSdPwMx : 36|12@1+ (0.0625,-125) [-125|125.9375] "%" Vector__XXX
 SG_ MtGt4IvtLtsAtvDSdPwM : 48|12@1+ (0.0625,-125) [-125|125.9375] "%" Vector__XXX

BO_ 2565993470 MG4ILAM: 8 Vector__XXX
 SG_ MtrGnrtr4InvrtrLmtsAtvMhnlCntr : 8|4@1+ (1,0) [0|15] "" Vector__XXX
 SG_ MtrGnrtr4InvrtrLmtsAtvTrqMxmm : 12|12@1+ (0.0625,-125) [-125|125.9375] "%" Vector__XXX
 SG_ MtrGnrtr4InvrtrLmtsAtvTrqMnmm : 24|12@1+ (0.0625,-125) [-125|125.9375] "%" Vector__XXX
 SG_ MtrGnrtr4InvrtrLmtsAtvSpdMxmm : 36|12@1+ (0.0625,-125) [-125|125.9375] "%" Vector__XXX
 SG_ MtrGnrtr4InvrtrLmtsAtvSpdMnmm : 48|12@1+ (0.0625,-125) [-125|125.9375] "%" Vector__XXX
 SG_ MtrGnrtr4InvrtrLmtsAtvMhnlCr : 0|8@1+ (1,0) [0|250] "count" Vector__XXX

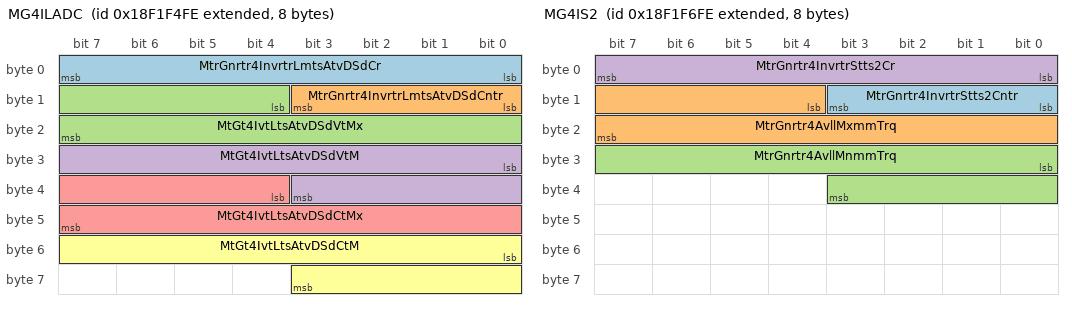
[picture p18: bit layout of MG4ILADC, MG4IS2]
BO_ 2565993726 MG4ILADC: 8 Vector__XXX
 SG_ MtrGnrtr4InvrtrLmtsAtvDSdCr : 0|8@1+ (1,0) [0|250] "count" Vector__XXX
 SG_ MtrGnrtr4InvrtrLmtsAtvDSdCntr : 8|4@1+ (1,0) [0|15] "" Vector__XXX
 SG_ MtGt4IvtLtsAtvDSdVtMx : 12|12@1+ (0.0625,-125) [-125|125.9375] "%" Vector__XXX
 SG_ MtGt4IvtLtsAtvDSdVtM : 24|12@1+ (0.0625,-125) [-125|125.9375] "%" Vector__XXX
 SG_ MtGt4IvtLtsAtvDSdCtMx : 36|12@1+ (0.0625,-125) [-125|125.9375] "%" Vector__XXX
 SG_ MtGt4IvtLtsAtvDSdCtM : 48|12@1+ (0.0625,-125) [-125|125.9375] "%" Vector__XXX

BO_ 2565993982 MG4ILV: 8 Vector__XXX
 SG_ MtrGnrtr4InvrtrSwthdIgntnVltg : 0|16@1+ (0.05,0) [0|3212.75] "V" Vector__XXX
 SG_ MtrGnrtr4InvrtrUnswthdSlVltg : 16|16@1+ (0.05,0) [0|3212.75] "V" Vector__XXX

BO_ 2565994238 MG4IS2: 8 Vector__XXX
 SG_ MtrGnrtr4InvrtrStts2Cntr : 8|4@1+ (1,0) [0|15] "" Vector__XXX
 SG_ MtrGnrtr4AvllMxmmTrq : 12|12@1+ (0.0625,-125) [-125|125.9375] "%" Vector__XXX
 SG_ MtrGnrtr4AvllMnmmTrq : 24|12@1+ (0.0625,-125) [-125|125.9375] "%" Vector__XXX
 SG_ MtrGnrtr4InvrtrStts2Cr : 0|8@1+ (1,0) [0|250] "count" Vector__XXX

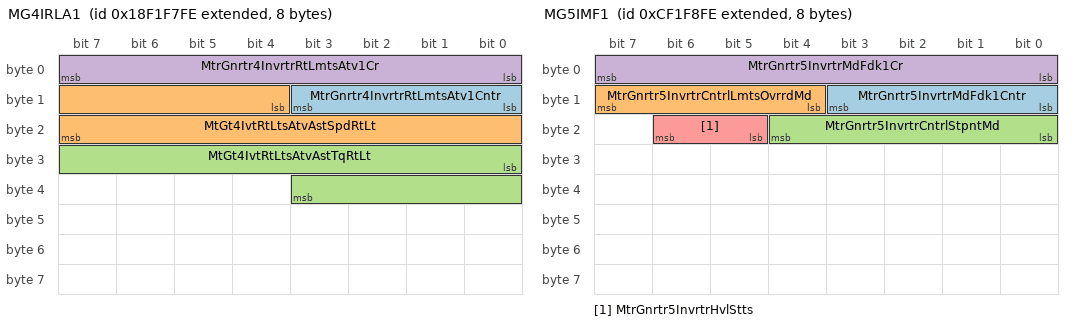
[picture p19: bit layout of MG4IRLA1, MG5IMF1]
BO_ 2565994494 MG4IRLA1: 8 Vector__XXX
 SG_ MtrGnrtr4InvrtrRtLmtsAtv1Cntr : 8|4@1+ (1,0) [0|15] "" Vector__XXX
 SG_ MtGt4IvtRtLtsAtvAstSpdRtLt : 12|12@1+ (0.25,0) [0|1003.75] "%/s" Vector__XXX
 SG_ MtGt4IvtRtLtsAtvAstTqRtLt : 24|12@1+ (2,0) [0|8030] "%/s" Vector__XXX
 SG_ MtrGnrtr4InvrtrRtLmtsAtv1Cr : 0|8@1+ (1,0) [0|250] "count" Vector__XXX

BO_ 2364668158 MG5IMF1: 8 Vector__XXX
 SG_ MtrGnrtr5InvrtrMdFdk1Cntr : 8|4@1+ (1,0) [0|15] "" Vector__XXX
 SG_ MtrGnrtr5InvrtrCntrlLmtsOvrrdMd : 12|4@1+ (1,0) [0|15] "" Vector__XXX
 SG_ MtrGnrtr5InvrtrCntrlStpntMd : 16|5@1+ (1,0) [0|31] "" Vector__XXX
 SG_ MtrGnrtr5InvrtrMdFdk1Cr : 0|8@1+ (1,0) [0|250] "count" Vector__XXX
 SG_ MtrGnrtr5InvrtrHvlStts : 21|2@1+ (1,0) [0|3] "" Vector__XXX

CM_ BO_ 2364652542 "High Voltage Energy Storage Pack 3 Data 10";
CM_ SG_ 2364652542 Hvsp3HghstCllSttOfChrgMdlNmr "HVESP3 Highest Cell State of Charge Module Number: Identifies the location of the module containing SPN 11300 (HVESP3 Highest Cell State of Charge).This parameter is for one of multiple packs in an HVESS.  If there is only one pack in the system, the...";
CM_ SG_ 2364652542 Hvsp3HghstCllSttOfChrgCllNmr "HVESP3 Highest Cell State of Charge Cell Number: Identifies the location of SPN 11300 (HVESP3 Highest Cell State of Charge) within SPN 11356 (HVESP3 Highest Cell State of Charge Module Number).This parameter is for one of multiple packs in an HVESS. ...";
CM_ SG_ 2364652542 Hvsp3LwstCllSttOfChrgMdlNmr "HVESP3 Lowest Cell State of Charge Module Number: Identifies the location of the module containing SPN 11299 (HVESP3 Lowest Cell State of Charge).This parameter is for one of multiple packs in an HVESS.  If there is only one pack in the system, the H...";
CM_ SG_ 2364652542 Hvsp3LwstCllSttOfChrgCllNmr "HVESP3 Lowest Cell State of Charge Cell Number: Identifies the location of SPN 11299 (HVESP3 Lowest Cell State of Charge) within SPN 11358 (HVESP3 Lowest Cell State of Charge Module Number).This parameter is for one of multiple packs in an HVESS.  If...";
CM_ SG_ 2364652542 Hvsp3HghVltgBsAtvIsltnTstRslts "HVESP3 High-Voltage Bus Active Isolation Test Results: The isolation resistance expressed in Ohms per Volt that resulted from the High-Voltage Bus Active Isolation Test.See SPN 11312 (HVESP3 High-Voltage Bus Active Isolation Test Status) for test sta...";
CM_ SG_ 2364652542 Hvsp3HghVltgBsPssvIsltnTstRslts "HVESP3 High-Voltage Bus Passive Isolation Test Results: The isolation resistance expressed in Ohms per Volt that resulted from the High-Voltage Bus Passive Isolation Test.See SPN 11313 (HVESP3 High-Voltage Bus Passive Isolation Test Status) for test ...";
CM_ BO_ 2364652798 "High Voltage Energy Storage Pack 3 Data 11";
CM_ SG_ 2364652798 Hvesp3ActualChargeRate "HVESP3 Actual Charge Rate: This signal represents the actual present charge rate of this High Voltage Energy Storage Pack instance.This parameter is for one of multiple packs in an HVESS. If there is only one pack in the system, the HVESS parameters ...";
CM_ SG_ 2364652798 Hvsp3BsVltgNgtvTChsssGrndVltg "HVESP3 Bus Voltage Negative to Chassis Ground Voltage: Voltage difference between the most negative terminal of the HVES battery and chassis measured on the hybrid or EV system bus side (not the battery side) of any HVES contained output contactor.  ...";
CM_ SG_ 2364652798 Hvsp3VltgLvlNgtvTChsssGrndVltg "HVESP3 Voltage Level Negative to Chassis Ground Voltage: Voltage difference between the most negative terminal of the HVES battery and chassis measured at the battery side of any HVES contained output contactor.  This voltage may be used for system l...";
CM_ BO_ 2364653054 "High Voltage Energy Storage Pack 4 Status 2";
CM_ SG_ 2364653054 Hvsp4DshrgPwrLmtDTSttOfChrg "HVESP4 Discharge Power Limit Due to State of Charge: Indicates whether or not discharge power of this HVES instance is being limited due to state of charge.This parameter is for one of multiple packs in an HVESS.  If there is only one pack in the sys...";
CM_ SG_ 2364653054 Hvsp4DshrgPwrLmtDTBttrTmprtr "HVESP4 Discharge Power Limit Due to Battery Temperature: Indicates whether or not discharge power of this HVES instance is being limited due to battery temperature.This parameter is for one of multiple packs in an HVESS.  If there is only one pack in...";
CM_ SG_ 2364653054 Hvsp4DsPwLtDTBttDstCdt "HVESP4 Discharge Power Limit Due to Battery Diagnostic Condition: Indicates whether or not discharge power of this HVES instance is being limited due to a battery diagnostic condition.This parameter is for one of multiple packs in an HVESS.  If there...";
CM_ SG_ 2364653054 Hvsp4DshrgPwrLmtDTBttrOrCllVltg "HVESP4 Discharge Power Limit Due to Battery or Cell Voltage: Indicates whether or not discharge power of this HVES instance is being limited due to a battery or cell voltage level.This parameter is for one of multiple packs in an HVESS.  If there is ...";
CM_ SG_ 2364653054 Hvsp4DshrgPwrLmtDTBttrCrrnt "HVESP4 Discharge Power Limit Due to Battery Current: Indicates whether or not discharge power of this HVES instance is being limited due to battery current.This parameter is for one of multiple packs in an HVESS.  If there is only one pack in the sys...";
CM_ SG_ 2364653054 Hvsp4DshrgPwrLmtDTAnUndfndCs "HVESP4 Discharge Power Limit Due to an Undefined Cause: Indicates whether or not discharge power of this HVES instance is being limited due to an undefined cause.This parameter is for one of multiple packs in an HVESS.  If there is only one pack in t...";
CM_ SG_ 2364653054 Hvsp4ChrgPwrLmtDTSttOfChrg "HVESP4 Charge Power Limit Due to State of Charge: Indicates whether or not charge power of this HVES instance is being limited due to state of charge.This parameter is for one of multiple packs in an HVESS.  If there is only one pack in the system, t...";
CM_ SG_ 2364653054 Hvsp4ChrgPwrLmtDTBttrTmprtr "HVESP4 Charge Power Limit Due to Battery Temperature: Indicates whether or not charge power of this HVES instance is being limited due to battery temperature.This parameter is for one of multiple packs in an HVESS.  If there is only one pack in the s...";
CM_ SG_ 2364653054 Hvsp4ChrgPwrLmtDTBttrDgnstCndtn "HVESP4 Charge Power Limit Due to Battery Diagnostic Condition: Indicates whether or not charge power of this HVES instance is being limited due to a battery diagnostic condition.This parameter is for one of multiple packs in an HVESS.  If there is on...";
CM_ SG_ 2364653054 Hvsp4ChrgPwrLmtDTBttrOrCllVltg "HVESP4 Charge Power Limit Due to Battery or Cell Voltage: Indicates whether or not charge power of this HVES instance is being limited due to a battery or cell voltage level.This parameter is for one of multiple packs in an HVESS.  If there is only o...";
CM_ SG_ 2364653054 Hvsp4ChrgPwrLmtDTBttrCrrnt "HVESP4 Charge Power Limit Due to Battery Current: Indicates whether or not charge power of this HVES instance is being limited due to battery current.This parameter is for one of multiple packs in an HVESS.  If there is only one pack in the system, t...";
CM_ SG_ 2364653054 Hvsp4ChrgPwrLmtDTAnUndfndCs "HVESP4 Charge Power Limit Due to an Undefined Cause: Indicates whether or not charge power of this HVES instance is being limited due to an undefined cause.This parameter is for one of multiple packs in an HVESS.  If there is only one pack in the sys...";
CM_ BO_ 2364653310 "High Voltage Energy Storage Pack 4 Data 1";
CM_ SG_ 2364653310 Hvesp4AvailableDischargePower "HVESP4 Available Discharge Power: The rate at which this High Voltage Energy Storage Pack instance can currently provide energy for propulsion or other uses.This parameter is for one of multiple packs in an HVESS.  If there is only one pack in the sy...";
CM_ SG_ 2364653310 Hvesp4AvailableChargePower "HVESP4 Available Charge Power: The rate at which this High Voltage Energy Storage Pack instance can currently receive energy from a regenerative or recharging system.This parameter is for one of multiple packs in an HVESS.  If there is only one pack ...";
CM_ SG_ 2364653310 Hvesp4VoltageLevel "HVESP4 Voltage Level: The voltage level of this High Voltage Energy Storage Pack instance. This parameter should be synchronized with SPN 11401 (HVESP4 Current) such that a realized power value can be calculated.  If the HVES component physically con...";
CM_ SG_ 2364653310 Hvesp4Current "HVESP4 Current: The current in or out of this High Voltage Energy Storage Pack instance. This parameter should be synchronized with SPN 11400 (HVESP4 Voltage Level) such that a realized power value can be calculated.  This parameter is defined from t...";
CM_ BO_ 2364653566 "High Voltage Energy Storage Pack 4 Data 2";
CM_ SG_ 2364653566 Hvesp4FastUpdateStateOfCharge "HVESP4 Fast Update State of Charge: Indicates this High Voltage Energy Storage Pack instance state of charge.  0% means no charge remaining, 100% means the system is fully charged in terms of physical limits of this energy storage pack instance.  Acc...";
CM_ SG_ 2364653566 Hvesp4HighestCellVoltage "HVESP4 Highest Cell Voltage: The highest voltage level reported by any cell in this High Voltage Energy Storage Pack instance. If a single voltage sensor covers more than one cell, the value in this parameter is for the smallest group of cells measur...";
CM_ SG_ 2364653566 Hvesp4LowestCellVoltage "HVESP4 Lowest Cell Voltage: The lowest voltage level reported by any cell in this High Voltage Energy Storage Pack instance. If a single voltage sensor covers more than one cell, the value in this parameter is for the smallest group of cells measured...";
CM_ SG_ 2364653566 Hvsp4CllVltgDffrntlStts "HVESP4 Cell Voltage Differential Status: Indicates whether or not the differential between the highest and lowest cell voltages are within acceptable limits, according to this High Voltage Energy Storage Pack instance. The actual voltage differential...";
CM_ BO_ 2364653822 "High Voltage Energy Storage Pack 4 Data 3";
CM_ SG_ 2364653822 Hvesp4HighestCellTemperature "HVESP4 Highest Cell Temperature: The highest temperature level reported by any cell in this High Voltage Energy Storage Pack instance.  If a single temperature sensor covers more than one cell, the value in this parameter is for the smallest group of...";
CM_ SG_ 2364653822 Hvesp4LowestCellTemperature "HVESP4 Lowest Cell Temperature: The lowest temperature level reported by any cell in this High Voltage Energy Storage Pack instance.  If a single temperature sensor covers more than one cell, the value in this parameter is for the smallest group of c...";
CM_ SG_ 2364653822 Hvesp4AverageCellTemperature "HVESP4 Average Cell Temperature: The average temperature level of all cells in this High Voltage Energy Storage Pack instance.This parameter is for one of multiple packs in an HVESS.  If there is only one pack in the system, the HVESS parameters shou...";
CM_ SG_ 2364653822 Hvsp4CllTmprtrDffrntlStts "HVESP4 Cell Temperature Differential Status: Indicates whether or not the differential between the highest and lowest cell temperatures are within acceptable limits per this High Voltage Energy Storage Pack instance.  The actual temperature different...";
CM_ BO_ 2364654078 "High Voltage Energy Storage Pack 4 Data 4";
CM_ SG_ 2364654078 Hvesp4DischargeCapacity "HVESP4 Discharge Capacity: The amount of stored electrical charge in this High Voltage Energy Storage Pack instance that is available for use by the hybrid or EV system, i.e. 'how full is the tank'.  See SPN 11438 (HVESP4 Discharge Energy Capacity) f...";
CM_ SG_ 2364654078 Hvesp4ChargeCapacity "HVESP4 Charge Capacity: The amount of unused electrical charge storage in this High Voltage Energy Storage Pack instance that is available to be filled by charging, i.e. 'how much empty space is remaining in the tank'.  See SPN 11439 (HVESP4 Charge E...";
CM_ SG_ 2364654078 Hvesp4CellBalancingCount "HVESP4 Cell Balancing Count: The number of cells that are currently being balanced in this High Voltage Energy Storage Pack instance.This parameter is for one of multiple packs in an HVESS.  If there is only one pack in the system, the HVESS paramete...";
CM_ BO_ 2364654334 "High Voltage Energy Storage Pack 4 Data 5";
CM_ SG_ 2364654334 Hvesp4LowestCellStateOfCharge "HVESP4 Lowest Cell State of Charge: Indicates the state of charge of the lowest-charged cell in this High Voltage Energy Storage Pack instance.  0% means no charge remaining, 100% means the cell is fully charged.   If a single state of charge value c...";
CM_ SG_ 2364654334 Hvesp4HighestCellStateOfCharge "HVESP4 Highest Cell State of Charge: Indicates the state of charge of the highest-charged cell in this High Voltage Energy Storage Pack instance.  0% means no charge remaining, 100% means the cell is fully charged.  If a single state of charge value ...";
CM_ SG_ 2364654334 Hvsp4MxmmInstntnsDshrgCrrntLmt "HVESP4 Maximum Instantaneous Discharge Current Limit: The maximum instantaneous current flow limit out of this High Voltage Energy Storage Pack instance. This parameter is defined from the high voltage energy storage pack's point of view and should r...";
CM_ SG_ 2364654334 Hvsp4MxmmInstntnsChrgCrrntLmt "HVESP4 Maximum Instantaneous Charge Current Limit: The maximum instantaneous current flow limit into this High Voltage Energy Storage Pack instance. This parameter is defined from the high voltage energy storage pack's point of view and should reflec...";
CM_ BO_ 2364654590 "High Voltage Energy Storage Pack 4 Data 6";
CM_ SG_ 2364654590 Hvesp4BusVoltage "HVESP4 Bus Voltage: The voltage level of the high voltage bus, as measured by this High Voltage Energy Storage Pack instance on the bus side (not the battery side) of its contactors.This parameter is for one of multiple packs in an HVESS.  If there i...";
CM_ SG_ 2364654590 Hvesp4IgnitionVoltage "HVESP4 Ignition Voltage: The voltage level at the ignition input of this High Voltage Energy Storage Pack controller.This parameter is for one of multiple packs in an HVESS.  If there is only one pack in the system, the HVESS parameters should be use...";
CM_ SG_ 2364654590 Hvesp4IntakeCoolantTemperature "HVESP4 Intake Coolant Temperature: The temperature of liquid coolant as it enters this High Voltage Energy Storage Pack instance.This parameter is for one of multiple packs in an HVESS.  If there is only one pack in the system, the HVESS parameters s...";
CM_ SG_ 2364654590 Hvesp4OutletCoolantTemperature "HVESP4 Outlet Coolant Temperature: The temperature of liquid coolant as it exits this High Voltage Energy Storage Pack instance.This parameter is for one of multiple packs in an HVESS.  If there is only one pack in the system, the HVESS parameters sh...";
CM_ SG_ 2364654590 Hvesp4ElectronicsTemperature "HVESP4 Electronics Temperature: The temperature of the electronics or control modules in this High Voltage Energy Storage Pack instance.  If there are multiple temperature sensors then this parameter would be set to the maximum sensor reading.This pa...";
CM_ SG_ 2364654590 Hvesp4Temperature "HVESP4 Temperature: The temperature of this High Voltage Energy Storage Pack instance. The value may be determined from a unique sensor specifically for this purpose, or by aggregating various temperature sensor readings within the pack.This paramete...";
CM_ BO_ 2364654846 "High Voltage Energy Storage Pack 4 Status 1";
CM_ SG_ 2364654846 Hvesp4HvilStatus "HVESP4 HVIL Status: Status of the High Voltage Interlock Loop from the viewpoint of this High Voltage Energy Storage Pack instance.This parameter is for one of multiple packs in an HVESS. If there is only one pack in the system, the HVESS parameters ...";
CM_ SG_ 2364654846 Hvesp4InertiaSwitchStatus "HVESP4 Inertia Switch Status: Switch indicating that an impact has been sensed by this High Voltage Energy Storage Pack instance. The impact indication may require action by another controller, or by this HVES instance itself.  For example, a control...";
CM_ SG_ 2364654846 Hvesp4StateOfChargeStatus "HVESP4 State of Charge Status: Status of this High Voltage Energy Storage Pack instance State of Charge (SOC).  Note:  A given HVES controller may not support all of the states.This parameter is for one of multiple packs in an HVESS.  If there is onl...";
CM_ SG_ 2364654846 Hvesp4CellBalanceStatus "HVESP4 Cell Balance Status: Indicates whether or not the cells in this High Voltage Energy Storage Pack instance are balanced.This parameter is for one of multiple packs in an HVESS.  If there is only one pack in the system, the HVESS parameters shou...";
CM_ SG_ 2364654846 Hvesp4CellBalancingActive "HVESP4 Cell Balancing Active: Indicates whether or not the cells in this High Voltage Energy Storage Pack instance are currently being balanced.This parameter is for one of multiple packs in an HVESS.  If there is only one pack in the system, the HVE...";
CM_ SG_ 2364654846 Hvesp4InternalChargerStatus "HVESP4 Internal Charger Status: Indicates that the charger in this HVES instance is on.  External chargers may use the External Energy Source Connection Status (SPN 7898) and related SPs.This parameter is for one of multiple packs in an HVESS. If the...";
CM_ SG_ 2364654846 Hvesp4OperationalStatus "HVESP4 Operational Status: Provides feedback on where this High Voltage Energy Storage Pack instance is in its operating spectrum, and includes feedback in response to the Operation Consent [i.e. SPN 11383 (HVESP4 Operation Consent)] and Power Down C...";
CM_ SG_ 2364654846 Hvesp4Status1Counter "HVESP4 Status 1 Counter: The message counter is used to detect situations where the transmitting ECU malfunction repeats the same frame all the time. The receiver of the information may use the counter parameter to detect this situation. The transmit...";
CM_ SG_ 2364654846 Hvesp4Status1Crc "HVESP4 Status 1 CRC: The CRC is defined as follows: - Length: 8 bits- Polynomial: x^8+x^5+x^3+x^2+x+1- Initial Value: FFh- Input Data Reflection: Not reflected- Result Data Reflection: Not reflected- XOR value: FFh SAE makes no claim of the functiona...";
CM_ SG_ 2364654846 Hvsp4HghVltgBsPstvCnttrStt "HVESP4 High-Voltage Bus (Positive) Contactor State: Position of this High Voltage Energy Storage Pack instance positive side bus contactor.  When this contactor is closed, the positive side of this HVES instance is connected to the positive side of t...";
CM_ SG_ 2364654846 Hvsp4HghVltgBsNgtvCnttrStt "HVESP4 High-Voltage Bus (Negative) Contactor State: Position of this High Voltage Energy Storage Pack instance negative side bus contactor.  When this contactor is closed, the negative side of this HVES instance is connected to the negative side of t...";
CM_ SG_ 2364654846 Hvsp4HghVltgBsDsnntFrwrnng "HVESP4 High-Voltage Bus Disconnect Forewarning: Indicates that this High Voltage Energy Storage Pack instance is about to disconnect from the high voltage bus due to unacceptable conditions.This parameter is for one of multiple packs in an HVESS. If ...";
CM_ SG_ 2364654846 Hvsp4HghVltgBsPrChrgRlStt "HVESP4 High-Voltage Bus Pre-Charge Relay State: Position of the high-voltage bus contactor pre-charge relay.  When this relay is closed, this High Voltage Energy Storage Pack instance is bringing the high-voltage bus up to its operating level.This pa...";
CM_ SG_ 2364654846 Hvsp4CntrOfPkCnttrStt "HVESP4 Center of Pack Contactor State: Position of the center high-voltage contactor.  When this contactor is closed, the positive half of this High Voltage Energy Storage Pack instance is connected to the negative half.  If a system controls the pos...";
CM_ SG_ 2364654846 Hvsp4HghVltgBsAtvIsltnTstStts "HVESP4 High-Voltage Bus Active Isolation Test Status: Status of the high-voltage bus electrical active isolation test as performed by this High Voltage Energy Storage Pack instance.This parameter is for one of multiple packs in an HVESS. If there is ...";
CM_ SG_ 2364654846 Hvsp4HghVltgBsPssvIsltnTstStts "HVESP4 High-Voltage Bus Passive Isolation Test Status: Status of the high-voltage bus electrical passive isolation test as performed by this High Voltage Energy Storage Pack instance.This parameter is for one of multiple packs in an HVESS. If there i...";
CM_ SG_ 2364654846 Hvsp4HghVltgBsCnntnStts "HVESP4 High-Voltage Bus Connection Status: This parameter provides high level feedback on this High Voltage Energy Storage Pack instance high voltage bus connection.  For specific contactor information, see SPN 11423 (HVESP4 High-Voltage Bus (Positiv...";
CM_ BO_ 2364655102 "High Voltage Energy Storage Pack 4 Data 7";
CM_ SG_ 2364655102 Hvesp4DischargeEnergyCapacity "HVESP4 Discharge Energy Capacity: The amount of stored electrical energy in this High Voltage Energy Storage Pack instance that is available for use by the hybrid or EV system, i.e. 'how full is the tank'.  See SPN 11410 (HVESP4 Discharge Capacity) f...";
CM_ SG_ 2364655102 Hvesp4ChargeEnergyCapacity "HVESP4 Charge Energy Capacity: The amount of unused electrical energy storage available to be filled by charging this High Voltage Energy Storage Pack instance, i.e. 'how much empty space is remaining in the tank'.  See SPN 11411 (HVESP4 Charge Capac...";
CM_ SG_ 2364655102 Hvesp4MaximumChargeVoltageLimit "HVESP4 Maximum Charge Voltage Limit: The maximum voltage level not to be exceeded while charging this High Voltage Energy Storage Pack instance.  If this parameter is not supported, the maximum charge voltage should be limited to SPN 11482 (HVESP4 Re...";
CM_ BO_ 2364655358 "High Voltage Energy Storage Pack 4 Module Status 1";
CM_ SG_ 2364655358 Hvesp4Module1OperationalStatus "HVESP4 Module 1 Operational Status: Operational Status of Module 1 in this High Voltage Energy Storage Pack Instance.  Not Operational is used when the module is initializing or not able to function (e.g. internal module level monitors have failed). ...";
CM_ SG_ 2364655358 Hvesp4Module2OperationalStatus "HVESP4 Module 2 Operational Status: Operational Status of Module 2 in this High Voltage Energy Storage Pack Instance.  Not Operational is used when the module is initializing or not able to function (e.g. internal module level monitors have failed). ...";
CM_ SG_ 2364655358 Hvesp4Module3OperationalStatus "HVESP4 Module 3 Operational Status: Operational Status of Module 3 in this High Voltage Energy Storage Pack Instance.  Not Operational is used when the module is initializing or not able to function (e.g. internal module level monitors have failed). ...";
CM_ SG_ 2364655358 Hvesp4Module4OperationalStatus "HVESP4 Module 4 Operational Status: Operational Status of Module 4 in this High Voltage Energy Storage Pack Instance.  Not Operational is used when the module is initializing or not able to function (e.g. internal module level monitors have failed). ...";
CM_ SG_ 2364655358 Hvesp4Module5OperationalStatus "HVESP4 Module 5 Operational Status: Operational Status of Module 5 in this High Voltage Energy Storage Pack Instance.  Not Operational is used when the module is initializing or not able to function (e.g. internal module level monitors have failed). ...";
CM_ SG_ 2364655358 Hvesp4Module6OperationalStatus "HVESP4 Module 6 Operational Status: Operational Status of Module 6 in this High Voltage Energy Storage Pack Instance.  Not Operational is used when the module is initializing or not able to function (e.g. internal module level monitors have failed). ...";
CM_ SG_ 2364655358 Hvesp4Module7OperationalStatus "HVESP4 Module 7 Operational Status: Operational Status of Module 7 in this High Voltage Energy Storage Pack Instance.  Not Operational is used when the module is initializing or not able to function (e.g. internal module level monitors have failed). ...";
CM_ SG_ 2364655358 Hvesp4Module8OperationalStatus "HVESP4 Module 8 Operational Status: Operational Status of Module 8 in this High Voltage Energy Storage Pack Instance.  Not Operational is used when the module is initializing or not able to function (e.g. internal module level monitors have failed). ...";
CM_ SG_ 2364655358 Hvesp4Module9OperationalStatus "HVESP4 Module 9 Operational Status: Operational Status of Module 9 in this High Voltage Energy Storage Pack Instance.  Not Operational is used when the module is initializing or not able to function (e.g. internal module level monitors have failed). ...";
CM_ SG_ 2364655358 Hvesp4Module10OperationalStatus "HVESP4 Module 10 Operational Status: Operational Status of Module 10 in this High Voltage Energy Storage Pack Instance.  Not Operational is used when the module is initializing or not able to function (e.g. internal module level monitors have failed)...";
CM_ SG_ 2364655358 Hvesp4Module11OperationalStatus "HVESP4 Module 11 Operational Status: Operational Status of Module 11 in this High Voltage Energy Storage Pack Instance.  Not Operational is used when the module is initializing or not able to function (e.g. internal module level monitors have failed)...";
CM_ SG_ 2364655358 Hvesp4Module12OperationalStatus "HVESP4 Module 12 Operational Status: Operational Status of Module 12 in this High Voltage Energy Storage Pack Instance.  Not Operational is used when the module is initializing or not able to function (e.g. internal module level monitors have failed)...";
CM_ SG_ 2364655358 Hvesp4Module13OperationalStatus "HVESP4 Module 13 Operational Status: Operational Status of Module 13 in this High Voltage Energy Storage Pack Instance.  Not Operational is used when the module is initializing or not able to function (e.g. internal module level monitors have failed)...";
CM_ SG_ 2364655358 Hvesp4Module14OperationalStatus "HVESP4 Module 14 Operational Status: Operational Status of Module 14 in this High Voltage Energy Storage Pack Instance.  Not Operational is used when the module is initializing or not able to function (e.g. internal module level monitors have failed)...";
CM_ SG_ 2364655358 Hvesp4Module15OperationalStatus "HVESP4 Module 15 Operational Status: Operational Status of Module 15 in this High Voltage Energy Storage Pack Instance.  Not Operational is used when the module is initializing or not able to function (e.g. internal module level monitors have failed)...";
CM_ SG_ 2364655358 Hvesp4Module16OperationalStatus "HVESP4 Module 16 Operational Status: Operational Status of Module 16 in this High Voltage Energy Storage Pack Instance.  Not Operational is used when the module is initializing or not able to function (e.g. internal module level monitors have failed)...";
CM_ SG_ 2364655358 Hvesp4Module17OperationalStatus "HVESP4 Module 17 Operational Status: Operational Status of Module 17 in this High Voltage Energy Storage System (or Pack 1 in systems with only one pack).  Not Operational is used when the module is initializing or not able to function (e.g. internal...";
CM_ SG_ 2364655358 Hvesp4Module18OperationalStatus "HVESP4 Module 18 Operational Status: Operational Status of Module 18 in this High Voltage Energy Storage System (or Pack 1 in systems with only one pack).  Not Operational is used when the module is initializing or not able to function (e.g. internal...";
CM_ SG_ 2364655358 Hvesp4Module19OperationalStatus "HVESP4 Module 19 Operational Status: Operational Status of Module 19 in this High Voltage Energy Storage System (or Pack 1 in systems with only one pack).  Not Operational is used when the module is initializing or not able to function (e.g. internal...";
CM_ SG_ 2364655358 Hvesp4Module20OperationalStatus "HVESP4 Module 20 Operational Status: Operational Status of Module 20 in this High Voltage Energy Storage System (or Pack 1 in systems with only one pack).  Not Operational is used when the module is initializing or not able to function (e.g. internal...";
CM_ SG_ 2364655358 Hvesp4Module21OperationalStatus "HVESP4 Module 21 Operational Status: Operational Status of Module 21 in this High Voltage Energy Storage System (or Pack 1 in systems with only one pack).  Not Operational is used when the module is initializing or not able to function (e.g. internal...";
CM_ SG_ 2364655358 Hvesp4Module22OperationalStatus "HVESP4 Module 22 Operational Status: Operational Status of Module 22 in this High Voltage Energy Storage System (or Pack 1 in systems with only one pack).  Not Operational is used when the module is initializing or not able to function (e.g. internal...";
CM_ SG_ 2364655358 Hvesp4Module23OperationalStatus "HVESP4 Module 23 Operational Status: Operational Status of Module 23 in this High Voltage Energy Storage System (or Pack 1 in systems with only one pack).  Not Operational is used when the module is initializing or not able to function (e.g. internal...";
CM_ SG_ 2364655358 Hvesp4Module24OperationalStatus "HVESP4 Module 24 Operational Status: Operational Status of Module 24 in this High Voltage Energy Storage System (or Pack 1 in systems with only one pack).  Not Operational is used when the module is initializing or not able to function (e.g. internal...";
CM_ SG_ 2364655358 Hvesp4Module25OperationalStatus "HVESP4 Module 25 Operational Status: Operational Status of Module 25 in this High Voltage Energy Storage System (or Pack 1 in systems with only one pack).  Not Operational is used when the module is initializing or not able to function (e.g. internal...";
CM_ SG_ 2364655358 Hvesp4Module26OperationalStatus "HVESP4 Module 26 Operational Status: Operational Status of Module 26 in this High Voltage Energy Storage System (or Pack 1 in systems with only one pack).  Not Operational is used when the module is initializing or not able to function (e.g. internal...";
CM_ SG_ 2364655358 Hvesp4Module27OperationalStatus "HVESP4 Module 27 Operational Status: Operational Status of Module 27 in this High Voltage Energy Storage System (or Pack 1 in systems with only one pack).  Not Operational is used when the module is initializing or not able to function (e.g. internal...";
CM_ SG_ 2364655358 Hvesp4Module28OperationalStatus "HVESP4 Module 28 Operational Status: Operational Status of Module 28 in this High Voltage Energy Storage System (or Pack 1 in systems with only one pack).  Not Operational is used when the module is initializing or not able to function (e.g. internal...";
CM_ SG_ 2364655358 Hvesp4Module29OperationalStatus "HVESP4 Module 29 Operational Status: Operational Status of Module 29 in this High Voltage Energy Storage System (or Pack 1 in systems with only one pack).  Not Operational is used when the module is initializing or not able to function (e.g. internal...";
CM_ SG_ 2364655358 Hvesp4Module30OperationalStatus "HVESP4 Module 30 Operational Status: Operational Status of Module 30 in this High Voltage Energy Storage System (or Pack 1 in systems with only one pack).  Not Operational is used when the module is initializing or not able to function (e.g. internal...";
CM_ SG_ 2364655358 Hvesp4Module31OperationalStatus "HVESP4 Module 31 Operational Status: Operational Status of Module 31 in this High Voltage Energy Storage System (or Pack 1 in systems with only one pack).  Not Operational is used when the module is initializing or not able to function (e.g. internal...";
CM_ SG_ 2364655358 Hvesp4Module32OperationalStatus "HVESP4 Module 32 Operational Status: Operational Status of Module 32 in this High Voltage Energy Storage System (or Pack 1 in systems with only one pack).  Not Operational is used when the module is initializing or not able to function (e.g. internal...";
CM_ BO_ 2364655614 "High Voltage Energy Storage Pack 4 Thermal Management System Status 1";
CM_ SG_ 2364655614 Hvsp4ThrmlMngmntSstmSlInptPwr "HVESP4 Thermal Management System SLI Input Power: This is the low-voltage power consumed by this HVES Thermal Management System (TMS).This parameter is for one of multiple packs in an HVESS.  If there is only one pack in the system, the HVESS paramet...";
CM_ SG_ 2364655614 Hvsp4TMtSstHVtIptPw "HVESP4 Thermal Management System High-Voltage Input Power: This is the high-voltage power consumed by this HVES Thermal Management System (TMS).This parameter is for one of multiple packs in an HVESS.  If there is only one pack in the system, the HVE...";
CM_ SG_ 2364655614 Hvsp4ThrmlMngmntSstmCmprssrSpd "HVESP4 Thermal Management System Compressor Speed: When this High Voltage Energy Storage Pack Thermal Management System is equipped with an active cooling system (e.g. air conditioner), this is the Compressor Speed.This parameter is for one of multip...";
CM_ SG_ 2364655614 Hvsp4ThrmlMngmntSstmRltvHmdt "HVESP4 Thermal Management System Relative Humidty: When this High Voltage Energy Storage Pack Thermal Management System is equipped with a relative humidity sensor, this is the  measured Relative Humidity.This parameter is for one of multiple packs i...";
CM_ SG_ 2364655614 Hvsp4ThrmlMngmntSstmHtrStts "HVESP4 Thermal Management System Heater Status: The state of this High Voltage Energy Storage Pack heaterThis parameter is for one of multiple packs in an HVESS.  If there is only one pack in the system, the HVESS parameters should be used. If there ...";
CM_ SG_ 2364655614 Hvsp4ThrmlMngmntSstmHvlStts "HVESP4 Thermal Management System HVIL Status: In multiple HVES configurations, this is the status of the High Voltage Interlock Loop from the viewpoint of this Thermal Management System.00b = HVIL Closed01b = HVIL Open10b = Error11b = Not AvailableTh...";
CM_ SG_ 2364655614 Hvsp4ThrmlMngmntSstmMd "HVESP4 Thermal Management System Mode: Indicates the operating mode of the Thermal Management System.  The heat transfer medium may be (e.g. liquid or air).  The cooling system may be fans, liquid coolant, or a combination of mediums.  The system may...";
CM_ SG_ 2364655614 Hvsp4ThrmlMngmntSstmClntLvl "HVESP4 Thermal Management System Coolant Level: Indicates the coolant level in this HVES Thermal Management System (TMS).This parameter is for one of multiple packs in an HVESS.  If there is only one pack in the system, the HVESS parameters should be...";
CM_ BO_ 2364655870 "High Voltage Energy Storage Pack 4 Data 8";
CM_ SG_ 2364655870 Hvesp4AverageCellVoltage "HVESP4 Average Cell Voltage: The average cell voltage in this High Voltage Energy Storage Pack instance.This parameter is for one of multiple packs in an HVESS.  If there is only one pack in the system, the HVESS parameters should be used. If there a...";
CM_ SG_ 2364655870 Hvsp4HghstCllVltgMdlNmr "HVESP4 Highest Cell Voltage Module Number: Identifies the location of the module containing SPN 11403 (HVESP4 Highest Cell Voltage).This parameter is for one of multiple packs in an HVESS.  If there is only one pack in the system, the HVESS parameter...";
CM_ SG_ 2364655870 Hvsp4HghstCllVltgCllNmr "HVESP4 Highest Cell Voltage Cell Number: Identifies the location of SPN 11403 (HVESP4 Highest Cell Voltage) within SPN 11463 (HVESP4 Highest Cell Voltage Module Number).This parameter is for one of multiple packs in an HVESS.  If there is only one pa...";
CM_ SG_ 2364655870 Hvsp4LwstCllVltgMdlNmr "HVESP4 Lowest Cell Voltage Module Number: Identifies the location of the module containing SPN 11404 (HVESP4 Lowest Cell Voltage).This parameter is for one of multiple packs in an HVESS.  If there is only one pack in the system, the HVESS parameters ...";
CM_ SG_ 2364655870 Hvsp4LwstCllVltgCllNmr "HVESP4 Lowest Cell Voltage Cell Number: Identifies the location of SPN 11404 (HVESP4 Lowest Cell Voltage) within SPN 11465 (HVESP4 Lowest Cell Voltage Module Number).This parameter is for one of multiple packs in an HVESS.  If there is only one pack ...";
CM_ BO_ 2364656126 "High Voltage Energy Storage Pack 4 Data 9";
CM_ SG_ 2364656126 Hvsp4HghstCllTmprtrMdlNmr "HVESP4 Highest Cell Temperature Module Number: Identifies the location of the module containing SPN 11406 (HVESP4 Highest Cell Temperature).This parameter is for one of multiple packs in an HVESS.  If there is only one pack in the system, the HVESS p...";
CM_ SG_ 2364656126 Hvsp4HghstCllTmprtrCllNmr "HVESP4 Highest Cell Temperature Cell Number: Identifies the location of SPN 11406 (HVESP4 Highest Cell Temperature) within SPN 11468 (HVESP4 Highest Cell Temperature Module Number).This parameter is for one of multiple packs in an HVESS.  If there is...";
CM_ SG_ 2364656126 Hvsp4LwstCllTmprtrMdlNmr "HVESP4 Lowest Cell Temperature Module Number: Identifies the location of the module containing SPN 11407 (HVESP4 Lowest Cell Temperature).This parameter is for one of multiple packs in an HVESS.  If there is only one pack in the system, the HVESS par...";
CM_ SG_ 2364656126 Hvsp4LwstCllTmprtrCllNmr "HVESP4 Lowest Cell Temperature Cell Number: Identifies the location of SPN 11407 (HVESP4 Lowest Cell Temperature) within SPN 11470 (HVESP4 Lowest Cell Temperature Module Number).This parameter is for one of multiple packs in an HVESS.  If there is on...";
CM_ SG_ 2364656126 Hvess4ThermalEventDetected "HVESS4 Thermal Event Detected: A sensor has detected the presence of a thermal event at or near High Voltage Energy Storage Pack instance.00b = No Thermal Event Detected01b = Thermal Event Detected10b = Error11b = Not availableThis parameter is for o...";
CM_ SG_ 2364656126 Hvsp4Dt9EmdddIntgrtSpprt "HVESP4 Data 9 Embedded Integrity Support: Indicates SPN 22985 (HVESP4 Data 9 CRC) and SPN 22984 (HVESP4 Data 9 Counter) are supported by the sender.00b = Embedded CRC and Counter are supported by the sender01b = Protection is provided using an extern...";
CM_ SG_ 2364656126 Hvesp4Data9Counter "HVESP4 Data 9 Counter: The message counter is used to detect situations where the transmitting ECU malfunction repeats the same frame all the time. The receiver of the information may use the counter parameter to detect this situation. The transmitti...";
CM_ SG_ 2364656126 Hvesp4Data9Crc "HVESP4 Data 9 CRC: The CRC is defined as follows: - Length: 8 bits- Polynomial: x^8+x^5+x^3+x^2+x+1- Initial Value: FFh- Input Data Reflection: Not reflected- Result Data Reflection: Not reflected- XOR value: FFh SAE makes no claim of the functional ...";
CM_ BO_ 2364656382 "High Voltage Energy Storage Pack 4 Data 10";
CM_ SG_ 2364656382 Hvsp4HghstCllSttOfChrgMdlNmr "HVESP4 Highest Cell State of Charge Module Number: Identifies the location of the module containing SPN 11416 (HVESP4 Highest Cell State of Charge).This parameter is for one of multiple packs in an HVESS.  If there is only one pack in the system, the...";
CM_ SG_ 2364656382 Hvsp4HghstCllSttOfChrgCllNmr "HVESP4 Highest Cell State of Charge Cell Number: Identifies the location of SPN 11416 (HVESP4 Highest Cell State of Charge) within SPN 11472 (HVESP4 Highest Cell State of Charge Module Number).This parameter is for one of multiple packs in an HVESS. ...";
CM_ SG_ 2364656382 Hvsp4LwstCllSttOfChrgMdlNmr "HVESP4 Lowest Cell State of Charge Module Number: Identifies the location of the module containing SPN 11415 (HVESP4 Lowest Cell State of Charge).This parameter is for one of multiple packs in an HVESS.  If there is only one pack in the system, the H...";
CM_ SG_ 2364656382 Hvsp4LwstCllSttOfChrgCllNmr "HVESP4 Lowest Cell State of Charge Cell Number: Identifies the location of SPN 11415 (HVESP4 Lowest Cell State of Charge) within SPN 11474 (HVESP4 Lowest Cell State of Charge Module Number).This parameter is for one of multiple packs in an HVESS.  If...";
CM_ SG_ 2364656382 Hvsp4HghVltgBsAtvIsltnTstRslts "HVESP4 High-Voltage Bus Active Isolation Test Results: The isolation resistance expressed in Ohms per Volt that resulted from the High-Voltage Bus Active Isolation Test.See SPN 11428 (HVESP4 High-Voltage Bus Active Isolation Test Status) for test sta...";
CM_ SG_ 2364656382 Hvsp4HghVltgBsPssvIsltnTstRslts "HVESP4 High-Voltage Bus Passive Isolation Test Results: The isolation resistance expressed in Ohms per Volt that resulted from the High-Voltage Bus Passive Isolation Test.See SPN 11429 (HVESP4 High-Voltage Bus Passive Isolation Test Status) for test ...";
CM_ BO_ 2364656638 "High Voltage Energy Storage Pack 4 Data 11";
CM_ SG_ 2364656638 Hvesp4ActualChargeRate "HVESP4 Actual Charge Rate: This signal represents the actual present charge rate of this High Voltage Energy Storage Pack instance.This parameter is for one of multiple packs in an HVESS. If there is only one pack in the system, the HVESS parameters ...";
CM_ SG_ 2364656638 Hvsp4BsVltgNgtvTChsssGrndVltg "HVESP4 Bus Voltage Negative to Chassis Ground Voltage: Voltage difference between the most negative terminal of the HVES battery and chassis measured on the hybrid or EV system bus side (not the battery side) of any HVES contained output contactor.  ...";
CM_ SG_ 2364656638 Hvsp4VltgLvlNgtvTChsssGrndVltg "HVESP4 Voltage Level Negative to Chassis Ground Voltage: Voltage difference between the most negative terminal of the HVES battery and chassis measured at the battery side of any HVES contained output contactor.  This voltage may be used for system l...";
CM_ BO_ 2364656894 "High Voltage Energy Storage Pack 5 Status 2";
CM_ SG_ 2364656894 Hvsp5DshrgPwrLmtDTSttOfChrg "HVESP5 Discharge Power Limit Due to State of Charge: Indicates whether or not discharge power of this HVES instance is being limited due to state of charge.This parameter is for one of multiple packs in an HVESS.  If there is only one pack in the sys...";
CM_ SG_ 2364656894 Hvsp5DshrgPwrLmtDTBttrTmprtr "HVESP5 Discharge Power Limit Due to Battery Temperature: Indicates whether or not discharge power of this HVES instance is being limited due to battery temperature.This parameter is for one of multiple packs in an HVESS.  If there is only one pack in...";
CM_ SG_ 2364656894 Hvsp5DsPwLtDTBttDstCdt "HVESP5 Discharge Power Limit Due to Battery Diagnostic Condition: Indicates whether or not discharge power of this HVES instance is being limited due to a battery diagnostic condition.This parameter is for one of multiple packs in an HVESS.  If there...";
CM_ SG_ 2364656894 Hvsp5DshrgPwrLmtDTBttrOrCllVltg "HVESP5 Discharge Power Limit Due to Battery or Cell Voltage: Indicates whether or not discharge power of this HVES instance is being limited due to a battery or cell voltage level.This parameter is for one of multiple packs in an HVESS.  If there is ...";
CM_ SG_ 2364656894 Hvsp5DshrgPwrLmtDTBttrCrrnt "HVESP5 Discharge Power Limit Due to Battery Current: Indicates whether or not discharge power of this HVES instance is being limited due to battery current.This parameter is for one of multiple packs in an HVESS.  If there is only one pack in the sys...";
CM_ SG_ 2364656894 Hvsp5DshrgPwrLmtDTAnUndfndCs "HVESP5 Discharge Power Limit Due to an Undefined Cause: Indicates whether or not discharge power of this HVES instance is being limited due to an undefined cause.This parameter is for one of multiple packs in an HVESS.  If there is only one pack in t...";
CM_ SG_ 2364656894 Hvsp5ChrgPwrLmtDTSttOfChrg "HVESP5 Charge Power Limit Due to State of Charge: Indicates whether or not charge power of this HVES instance is being limited due to state of charge.This parameter is for one of multiple packs in an HVESS.  If there is only one pack in the system, t...";
CM_ SG_ 2364656894 Hvsp5ChrgPwrLmtDTBttrTmprtr "HVESP5 Charge Power Limit Due to Battery Temperature: Indicates whether or not charge power of this HVES instance is being limited due to battery temperature.This parameter is for one of multiple packs in an HVESS.  If there is only one pack in the s...";
CM_ SG_ 2364656894 Hvsp5ChrgPwrLmtDTBttrDgnstCndtn "HVESP5 Charge Power Limit Due to Battery Diagnostic Condition: Indicates whether or not charge power of this HVES instance is being limited due to a battery diagnostic condition.This parameter is for one of multiple packs in an HVESS.  If there is on...";
CM_ SG_ 2364656894 Hvsp5ChrgPwrLmtDTBttrOrCllVltg "HVESP5 Charge Power Limit Due to Battery or Cell Voltage: Indicates whether or not charge power of this HVES instance is being limited due to a battery or cell voltage level.This parameter is for one of multiple packs in an HVESS.  If there is only o...";
CM_ SG_ 2364656894 Hvsp5ChrgPwrLmtDTBttrCrrnt "HVESP5 Charge Power Limit Due to Battery Current: Indicates whether or not charge power of this HVES instance is being limited due to battery current.This parameter is for one of multiple packs in an HVESS.  If there is only one pack in the system, t...";
CM_ SG_ 2364656894 Hvsp5ChrgPwrLmtDTAnUndfndCs "HVESP5 Charge Power Limit Due to an Undefined Cause: Indicates whether or not charge power of this HVES instance is being limited due to an undefined cause.This parameter is for one of multiple packs in an HVESS.  If there is only one pack in the sys...";
CM_ BO_ 2364657150 "High Voltage Energy Storage Pack 5 Data 1";
CM_ SG_ 2364657150 Hvesp5AvailableDischargePower "HVESP5 Available Discharge Power: The rate at which this High Voltage Energy Storage Pack instance can currently provide energy for propulsion or other uses.This parameter is for one of multiple packs in an HVESS.  If there is only one pack in the sy...";
CM_ SG_ 2364657150 Hvesp5AvailableChargePower "HVESP5 Available Charge Power: The rate at which this High Voltage Energy Storage Pack instance can currently receive energy from a regenerative or recharging system.This parameter is for one of multiple packs in an HVESS.  If there is only one pack ...";
CM_ SG_ 2364657150 Hvesp5VoltageLevel "HVESP5 Voltage Level: The voltage level of this High Voltage Energy Storage Pack instance. This parameter should be synchronized with SPN 11517 (HVESP5 Current) such that a realized power value can be calculated.  If the HVES component physically con...";
CM_ SG_ 2364657150 Hvesp5Current "HVESP5 Current: The current in or out of this High Voltage Energy Storage Pack instance. This parameter should be synchronized with SPN 11516 (HVESP5 Voltage Level) such that a realized power value can be calculated.  This parameter is defined from t...";
CM_ BO_ 2364657406 "High Voltage Energy Storage Pack 5 Data 2";
CM_ SG_ 2364657406 Hvesp5FastUpdateStateOfCharge "HVESP5 Fast Update State of Charge: Indicates this High Voltage Energy Storage Pack instance state of charge.  0% means no charge remaining, 100% means the system is fully charged in terms of physical limits of this energy storage pack instance.  Acc...";
CM_ SG_ 2364657406 Hvesp5HighestCellVoltage "HVESP5 Highest Cell Voltage: The highest voltage level reported by any cell in this High Voltage Energy Storage Pack instance. If a single voltage sensor covers more than one cell, the value in this parameter is for the smallest group of cells measur...";
CM_ SG_ 2364657406 Hvesp5LowestCellVoltage "HVESP5 Lowest Cell Voltage: The lowest voltage level reported by any cell in this High Voltage Energy Storage Pack instance. If a single voltage sensor covers more than one cell, the value in this parameter is for the smallest group of cells measured...";
CM_ SG_ 2364657406 Hvsp5CllVltgDffrntlStts "HVESP5 Cell Voltage Differential Status: Indicates whether or not the differential between the highest and lowest cell voltages are within acceptable limits, according to this High Voltage Energy Storage Pack instance. The actual voltage differential...";
CM_ BO_ 2364657662 "High Voltage Energy Storage Pack 5 Data 3";
CM_ SG_ 2364657662 Hvesp5HighestCellTemperature "HVESP5 Highest Cell Temperature: The highest temperature level reported by any cell in this High Voltage Energy Storage Pack instance.  If a single temperature sensor covers more than one cell, the value in this parameter is for the smallest group of...";
CM_ SG_ 2364657662 Hvesp5LowestCellTemperature "HVESP5 Lowest Cell Temperature: The lowest temperature level reported by any cell in this High Voltage Energy Storage Pack instance.  If a single temperature sensor covers more than one cell, the value in this parameter is for the smallest group of c...";
CM_ SG_ 2364657662 Hvesp5AverageCellTemperature "HVESP5 Average Cell Temperature: The average temperature level of all cells in this High Voltage Energy Storage Pack instance.This parameter is for one of multiple packs in an HVESS.  If there is only one pack in the system, the HVESS parameters shou...";
CM_ SG_ 2364657662 Hvsp5CllTmprtrDffrntlStts "HVESP5 Cell Temperature Differential Status: Indicates whether or not the differential between the highest and lowest cell temperatures are within acceptable limits per this High Voltage Energy Storage Pack instance.  The actual temperature different...";
CM_ BO_ 2364657918 "High Voltage Energy Storage Pack 5 Data 4";
CM_ SG_ 2364657918 Hvesp5DischargeCapacity "HVESP5 Discharge Capacity: The amount of stored electrical charge in this High Voltage Energy Storage Pack instance that is available for use by the hybrid or EV system, i.e. 'how full is the tank'.  See SPN 11554 (HVESP5 Discharge Energy Capacity) f...";
CM_ SG_ 2364657918 Hvesp5ChargeCapacity "HVESP5 Charge Capacity: The amount of unused electrical charge storage in this High Voltage Energy Storage Pack instance that is available to be filled by charging, i.e. 'how much empty space is remaining in the tank'.  See SPN 11555 (HVESP5 Charge E...";
CM_ SG_ 2364657918 Hvesp5CellBalancingCount "HVESP5 Cell Balancing Count: The number of cells that are currently being balanced in this High Voltage Energy Storage Pack instance.This parameter is for one of multiple packs in an HVESS.  If there is only one pack in the system, the HVESS paramete...";
CM_ BO_ 2364658174 "High Voltage Energy Storage Pack 5 Data 5";
CM_ SG_ 2364658174 Hvesp5LowestCellStateOfCharge "HVESP5 Lowest Cell State of Charge: Indicates the state of charge of the lowest-charged cell in this High Voltage Energy Storage Pack instance.  0% means no charge remaining, 100% means the cell is fully charged.   If a single state of charge value c...";
CM_ SG_ 2364658174 Hvesp5HighestCellStateOfCharge "HVESP5 Highest Cell State of Charge: Indicates the state of charge of the highest-charged cell in this High Voltage Energy Storage Pack instance.  0% means no charge remaining, 100% means the cell is fully charged.  If a single state of charge value ...";
CM_ SG_ 2364658174 Hvsp5MxmmInstntnsDshrgCrrntLmt "HVESP5 Maximum Instantaneous Discharge Current Limit: The maximum instantaneous current flow limit out of this High Voltage Energy Storage Pack instance. This parameter is defined from the high voltage energy storage pack's point of view and should r...";
CM_ SG_ 2364658174 Hvsp5MxmmInstntnsChrgCrrntLmt "HVESP5 Maximum Instantaneous Charge Current Limit: The maximum instantaneous current flow limit into this High Voltage Energy Storage Pack instance. This parameter is defined from the high voltage energy storage pack's point of view and should reflec...";
CM_ BO_ 2364658430 "High Voltage Energy Storage Pack 5 Data 6";
CM_ SG_ 2364658430 Hvesp5BusVoltage "HVESP5 Bus Voltage: The voltage level of the high voltage bus, as measured by this High Voltage Energy Storage Pack instance on the bus side (not the battery side) of its contactors.This parameter is for one of multiple packs in an HVESS.  If there i...";
CM_ SG_ 2364658430 Hvesp5IgnitionVoltage "HVESP5 Ignition Voltage: The voltage level at the ignition input of this High Voltage Energy Storage Pack controller.This parameter is for one of multiple packs in an HVESS.  If there is only one pack in the system, the HVESS parameters should be use...";
CM_ SG_ 2364658430 Hvesp5IntakeCoolantTemperature "HVESP5 Intake Coolant Temperature: The temperature of liquid coolant as it enters this High Voltage Energy Storage Pack instance.This parameter is for one of multiple packs in an HVESS.  If there is only one pack in the system, the HVESS parameters s...";
CM_ SG_ 2364658430 Hvesp5OutletCoolantTemperature "HVESP5 Outlet Coolant Temperature: The temperature of liquid coolant as it exits this High Voltage Energy Storage Pack instance.This parameter is for one of multiple packs in an HVESS.  If there is only one pack in the system, the HVESS parameters sh...";
CM_ SG_ 2364658430 Hvesp5ElectronicsTemperature "HVESP5 Electronics Temperature: The temperature of the electronics or control modules in this High Voltage Energy Storage Pack instance.  If there are multiple temperature sensors then this parameter would be set to the maximum sensor reading.This pa...";
CM_ SG_ 2364658430 Hvesp5Temperature "HVESP5 Temperature: The temperature of this High Voltage Energy Storage Pack instance. The value may be determined from a unique sensor specifically for this purpose, or by aggregating various temperature sensor readings within the pack.This paramete...";
CM_ BO_ 2364658686 "High Voltage Energy Storage Pack 5 Status 1";
CM_ SG_ 2364658686 Hvesp5HvilStatus "HVESP5 HVIL Status: Status of the High Voltage Interlock Loop from the viewpoint of this High Voltage Energy Storage Pack instance.This parameter is for one of multiple packs in an HVESS. If there is only one pack in the system, the HVESS parameters ...";
CM_ SG_ 2364658686 Hvesp5InertiaSwitchStatus "HVESP5 Inertia Switch Status: Switch indicating that an impact has been sensed by this High Voltage Energy Storage Pack instance. The impact indication may require action by another controller, or by this HVES instance itself.  For example, a control...";
CM_ SG_ 2364658686 Hvesp5StateOfChargeStatus "HVESP5 State of Charge Status: Status of this High Voltage Energy Storage Pack instance State of Charge (SOC).  Note:  A given HVES controller may not support all of the states.This parameter is for one of multiple packs in an HVESS.  If there is onl...";
CM_ SG_ 2364658686 Hvesp5CellBalanceStatus "HVESP5 Cell Balance Status: Indicates whether or not the cells in this High Voltage Energy Storage Pack instance are balanced.This parameter is for one of multiple packs in an HVESS.  If there is only one pack in the system, the HVESS parameters shou...";
CM_ SG_ 2364658686 Hvesp5CellBalancingActive "HVESP5 Cell Balancing Active: Indicates whether or not the cells in this High Voltage Energy Storage Pack instance are currently being balanced.This parameter is for one of multiple packs in an HVESS.  If there is only one pack in the system, the HVE...";
CM_ SG_ 2364658686 Hvesp5InternalChargerStatus "HVESP5 Internal Charger Status: Indicates that the charger in this HVES instance is on.  External chargers may use the External Energy Source Connection Status (SPN 7898) and related SPs.This parameter is for one of multiple packs in an HVESS. If the...";
CM_ SG_ 2364658686 Hvesp5OperationalStatus "HVESP5 Operational Status: Provides feedback on where this High Voltage Energy Storage Pack instance is in its operating spectrum, and includes feedback in response to the Operation Consent [i.e. SPN 11499 (HVESP5 Operation Consent)] and Power Down C...";
CM_ SG_ 2364658686 Hvesp5Status1Counter "HVESP5 Status 1 Counter: The message counter is used to detect situations where the transmitting ECU malfunction repeats the same frame all the time. The receiver of the information may use the counter parameter to detect this situation. The transmit...";
CM_ SG_ 2364658686 Hvesp5Status1Crc "HVESP5 Status 1 CRC: The CRC is defined as follows: - Length: 8 bits- Polynomial: x^8+x^5+x^3+x^2+x+1- Initial Value: FFh- Input Data Reflection: Not reflected- Result Data Reflection: Not reflected- XOR value: FFh SAE makes no claim of the functiona...";
CM_ SG_ 2364658686 Hvsp5HghVltgBsPstvCnttrStt "HVESP5 High-Voltage Bus (Positive) Contactor State: Position of this High Voltage Energy Storage Pack instance positive side bus contactor.  When this contactor is closed, the positive side of this HVES instance is connected to the positive side of t...";
CM_ SG_ 2364658686 Hvsp5HghVltgBsNgtvCnttrStt "HVESP5 High-Voltage Bus (Negative) Contactor State: Position of this High Voltage Energy Storage Pack instance negative side bus contactor.  When this contactor is closed, the negative side of this HVES instance is connected to the negative side of t...";
CM_ SG_ 2364658686 Hvsp5HghVltgBsDsnntFrwrnng "HVESP5 High-Voltage Bus Disconnect Forewarning: Indicates that this High Voltage Energy Storage Pack instance is about to disconnect from the high voltage bus due to unacceptable conditions.This parameter is for one of multiple packs in an HVESS. If ...";
CM_ SG_ 2364658686 Hvsp5HghVltgBsPrChrgRlStt "HVESP5 High-Voltage Bus Pre-Charge Relay State: Position of the high-voltage bus contactor pre-charge relay.  When this relay is closed, this High Voltage Energy Storage Pack instance is bringing the high-voltage bus up to its operating level.This pa...";
CM_ SG_ 2364658686 Hvsp5CntrOfPkCnttrStt "HVESP5 Center of Pack Contactor State: Position of the center high-voltage contactor.  When this contactor is closed, the positive half of this High Voltage Energy Storage Pack instance is connected to the negative half.  If a system controls the pos...";
CM_ SG_ 2364658686 Hvsp5HghVltgBsAtvIsltnTstStts "HVESP5 High-Voltage Bus Active Isolation Test Status: Status of the high-voltage bus electrical active isolation test as performed by this High Voltage Energy Storage Pack instance.This parameter is for one of multiple packs in an HVESS. If there is ...";
CM_ SG_ 2364658686 Hvsp5HghVltgBsPssvIsltnTstStts "HVESP5 High-Voltage Bus Passive Isolation Test Status: Status of the high-voltage bus electrical passive isolation test as performed by this High Voltage Energy Storage Pack instance.This parameter is for one of multiple packs in an HVESS. If there i...";
CM_ SG_ 2364658686 Hvsp5HghVltgBsCnntnStts "HVESP5 High-Voltage Bus Connection Status: This parameter provides high level feedback on this High Voltage Energy Storage Pack instance high voltage bus connection.  For specific contactor information, see SPN 11539 (HVESP5 High-Voltage Bus (Positiv...";
CM_ BO_ 2364658942 "High Voltage Energy Storage Pack 5 Data 7";
CM_ SG_ 2364658942 Hvesp5DischargeEnergyCapacity "HVESP5 Discharge Energy Capacity: The amount of stored electrical energy in this High Voltage Energy Storage Pack instance that is available for use by the hybrid or EV system, i.e. 'how full is the tank'.  See SPN 11526 (HVESP5 Discharge Capacity) f...";
CM_ SG_ 2364658942 Hvesp5ChargeEnergyCapacity "HVESP5 Charge Energy Capacity: The amount of unused electrical energy storage available to be filled by charging this High Voltage Energy Storage Pack instance, i.e. 'how much empty space is remaining in the tank'.  See SPN 11527 (HVESP5 Charge Capac...";
CM_ SG_ 2364658942 Hvesp5MaximumChargeVoltageLimit "HVESP5 Maximum Charge Voltage Limit: The maximum voltage level not to be exceeded while charging this High Voltage Energy Storage Pack instance.  If this parameter is not supported, the maximum charge voltage should be limited to SPN 11598 (HVESP5 Re...";
CM_ BO_ 2364659198 "High Voltage Energy Storage Pack 5 Module Status 1";
CM_ SG_ 2364659198 Hvesp5Module1OperationalStatus "HVESP5 Module 1 Operational Status: Operational Status of Module 1 in this High Voltage Energy Storage Pack Instance.  Not Operational is used when the module is initializing or not able to function (e.g. internal module level monitors have failed). ...";
CM_ SG_ 2364659198 Hvesp5Module2OperationalStatus "HVESP5 Module 2 Operational Status: Operational Status of Module 2 in this High Voltage Energy Storage Pack Instance.  Not Operational is used when the module is initializing or not able to function (e.g. internal module level monitors have failed). ...";
CM_ SG_ 2364659198 Hvesp5Module3OperationalStatus "HVESP5 Module 3 Operational Status: Operational Status of Module 3 in this High Voltage Energy Storage Pack Instance.  Not Operational is used when the module is initializing or not able to function (e.g. internal module level monitors have failed). ...";
CM_ SG_ 2364659198 Hvesp5Module4OperationalStatus "HVESP5 Module 4 Operational Status: Operational Status of Module 4 in this High Voltage Energy Storage Pack Instance.  Not Operational is used when the module is initializing or not able to function (e.g. internal module level monitors have failed). ...";
CM_ SG_ 2364659198 Hvesp5Module5OperationalStatus "HVESP5 Module 5 Operational Status: Operational Status of Module 5 in this High Voltage Energy Storage Pack Instance.  Not Operational is used when the module is initializing or not able to function (e.g. internal module level monitors have failed). ...";
CM_ SG_ 2364659198 Hvesp5Module6OperationalStatus "HVESP5 Module 6 Operational Status: Operational Status of Module 6 in this High Voltage Energy Storage Pack Instance.  Not Operational is used when the module is initializing or not able to function (e.g. internal module level monitors have failed). ...";
CM_ SG_ 2364659198 Hvesp5Module7OperationalStatus "HVESP5 Module 7 Operational Status: Operational Status of Module 7 in this High Voltage Energy Storage Pack Instance.  Not Operational is used when the module is initializing or not able to function (e.g. internal module level monitors have failed). ...";
CM_ SG_ 2364659198 Hvesp5Module8OperationalStatus "HVESP5 Module 8 Operational Status: Operational Status of Module 8 in this High Voltage Energy Storage Pack Instance.  Not Operational is used when the module is initializing or not able to function (e.g. internal module level monitors have failed). ...";
CM_ SG_ 2364659198 Hvesp5Module9OperationalStatus "HVESP5 Module 9 Operational Status: Operational Status of Module 9 in this High Voltage Energy Storage Pack Instance.  Not Operational is used when the module is initializing or not able to function (e.g. internal module level monitors have failed). ...";
CM_ SG_ 2364659198 Hvesp5Module10OperationalStatus "HVESP5 Module 10 Operational Status: Operational Status of Module 10 in this High Voltage Energy Storage Pack Instance.  Not Operational is used when the module is initializing or not able to function (e.g. internal module level monitors have failed)...";
CM_ SG_ 2364659198 Hvesp5Module11OperationalStatus "HVESP5 Module 11 Operational Status: Operational Status of Module 11 in this High Voltage Energy Storage Pack Instance.  Not Operational is used when the module is initializing or not able to function (e.g. internal module level monitors have failed)...";
CM_ SG_ 2364659198 Hvesp5Module12OperationalStatus "HVESP5 Module 12 Operational Status: Operational Status of Module 12 in this High Voltage Energy Storage Pack Instance.  Not Operational is used when the module is initializing or not able to function (e.g. internal module level monitors have failed)...";
CM_ SG_ 2364659198 Hvesp5Module13OperationalStatus "HVESP5 Module 13 Operational Status: Operational Status of Module 13 in this High Voltage Energy Storage Pack Instance.  Not Operational is used when the module is initializing or not able to function (e.g. internal module level monitors have failed)...";
CM_ SG_ 2364659198 Hvesp5Module14OperationalStatus "HVESP5 Module 14 Operational Status: Operational Status of Module 14 in this High Voltage Energy Storage Pack Instance.  Not Operational is used when the module is initializing or not able to function (e.g. internal module level monitors have failed)...";
CM_ SG_ 2364659198 Hvesp5Module15OperationalStatus "HVESP5 Module 15 Operational Status: Operational Status of Module 15 in this High Voltage Energy Storage Pack Instance.  Not Operational is used when the module is initializing or not able to function (e.g. internal module level monitors have failed)...";
CM_ SG_ 2364659198 Hvesp5Module16OperationalStatus "HVESP5 Module 16 Operational Status: Operational Status of Module 16 in this High Voltage Energy Storage Pack Instance.  Not Operational is used when the module is initializing or not able to function (e.g. internal module level monitors have failed)...";
CM_ SG_ 2364659198 Hvesp5Module17OperationalStatus "HVESP5 Module 17 Operational Status: Operational Status of Module 17 in this High Voltage Energy Storage System (or Pack 1 in systems with only one pack).  Not Operational is used when the module is initializing or not able to function (e.g. internal...";
CM_ SG_ 2364659198 Hvesp5Module18OperationalStatus "HVESP5 Module 18 Operational Status: Operational Status of Module 18 in this High Voltage Energy Storage System (or Pack 1 in systems with only one pack).  Not Operational is used when the module is initializing or not able to function (e.g. internal...";
CM_ SG_ 2364659198 Hvesp5Module19OperationalStatus "HVESP5 Module 19 Operational Status: Operational Status of Module 19 in this High Voltage Energy Storage System (or Pack 1 in systems with only one pack).  Not Operational is used when the module is initializing or not able to function (e.g. internal...";
CM_ SG_ 2364659198 Hvesp5Module20OperationalStatus "HVESP5 Module 20 Operational Status: Operational Status of Module 20 in this High Voltage Energy Storage System (or Pack 1 in systems with only one pack).  Not Operational is used when the module is initializing or not able to function (e.g. internal...";
CM_ SG_ 2364659198 Hvesp5Module21OperationalStatus "HVESP5 Module 21 Operational Status: Operational Status of Module 21 in this High Voltage Energy Storage System (or Pack 1 in systems with only one pack).  Not Operational is used when the module is initializing or not able to function (e.g. internal...";
CM_ SG_ 2364659198 Hvesp5Module22OperationalStatus "HVESP5 Module 22 Operational Status: Operational Status of Module 22 in this High Voltage Energy Storage System (or Pack 1 in systems with only one pack).  Not Operational is used when the module is initializing or not able to function (e.g. internal...";
CM_ SG_ 2364659198 Hvesp5Module23OperationalStatus "HVESP5 Module 23 Operational Status: Operational Status of Module 23 in this High Voltage Energy Storage System (or Pack 1 in systems with only one pack).  Not Operational is used when the module is initializing or not able to function (e.g. internal...";
CM_ SG_ 2364659198 Hvesp5Module24OperationalStatus "HVESP5 Module 24 Operational Status: Operational Status of Module 24 in this High Voltage Energy Storage System (or Pack 1 in systems with only one pack).  Not Operational is used when the module is initializing or not able to function (e.g. internal...";
CM_ SG_ 2364659198 Hvesp5Module25OperationalStatus "HVESP5 Module 25 Operational Status: Operational Status of Module 25 in this High Voltage Energy Storage System (or Pack 1 in systems with only one pack).  Not Operational is used when the module is initializing or not able to function (e.g. internal...";
CM_ SG_ 2364659198 Hvesp5Module26OperationalStatus "HVESP5 Module 26 Operational Status: Operational Status of Module 26 in this High Voltage Energy Storage System (or Pack 1 in systems with only one pack).  Not Operational is used when the module is initializing or not able to function (e.g. internal...";
CM_ SG_ 2364659198 Hvesp5Module27OperationalStatus "HVESP5 Module 27 Operational Status: Operational Status of Module 27 in this High Voltage Energy Storage System (or Pack 1 in systems with only one pack).  Not Operational is used when the module is initializing or not able to function (e.g. internal...";
CM_ SG_ 2364659198 Hvesp5Module28OperationalStatus "HVESP5 Module 28 Operational Status: Operational Status of Module 28 in this High Voltage Energy Storage System (or Pack 1 in systems with only one pack).  Not Operational is used when the module is initializing or not able to function (e.g. internal...";
CM_ SG_ 2364659198 Hvesp5Module29OperationalStatus "HVESP5 Module 29 Operational Status: Operational Status of Module 29 in this High Voltage Energy Storage System (or Pack 1 in systems with only one pack).  Not Operational is used when the module is initializing or not able to function (e.g. internal...";
CM_ SG_ 2364659198 Hvesp5Module30OperationalStatus "HVESP5 Module 30 Operational Status: Operational Status of Module 30 in this High Voltage Energy Storage System (or Pack 1 in systems with only one pack).  Not Operational is used when the module is initializing or not able to function (e.g. internal...";
CM_ SG_ 2364659198 Hvesp5Module31OperationalStatus "HVESP5 Module 31 Operational Status: Operational Status of Module 31 in this High Voltage Energy Storage System (or Pack 1 in systems with only one pack).  Not Operational is used when the module is initializing or not able to function (e.g. internal...";
CM_ SG_ 2364659198 Hvesp5Module32OperationalStatus "HVESP5 Module 32 Operational Status: Operational Status of Module 32 in this High Voltage Energy Storage System (or Pack 1 in systems with only one pack).  Not Operational is used when the module is initializing or not able to function (e.g. internal...";
CM_ BO_ 2364659454 "High Voltage Energy Storage Pack 5 Thermal Management System Status 1";
CM_ SG_ 2364659454 Hvsp5ThrmlMngmntSstmSlInptPwr "HVESP5 Thermal Management System SLI Input Power: This is the low-voltage power consumed by this HVES Thermal Management System (TMS).This parameter is for one of multiple packs in an HVESS.  If there is only one pack in the system, the HVESS paramet...";
CM_ SG_ 2364659454 Hvsp5TMtSstHVtIptPw "HVESP5 Thermal Management System High-Voltage Input Power: This is the high-voltage power consumed by this HVES Thermal Management System (TMS).This parameter is for one of multiple packs in an HVESS.  If there is only one pack in the system, the HVE...";
CM_ SG_ 2364659454 Hvsp5ThrmlMngmntSstmCmprssrSpd "HVESP5 Thermal Management System Compressor Speed: When this High Voltage Energy Storage Pack Thermal Management System is equipped with an active cooling system (e.g. air conditioner), this is the Compressor Speed.This parameter is for one of multip...";
CM_ SG_ 2364659454 Hvsp5ThrmlMngmntSstmRltvHmdt "HVESP5 Thermal Management System Relative Humidty: When this High Voltage Energy Storage Pack Thermal Management System is equipped with a relative humidity sensor, this is the  measured Relative Humidity.This parameter is for one of multiple packs i...";
CM_ SG_ 2364659454 Hvsp5ThrmlMngmntSstmHtrStts "HVESP5 Thermal Management System Heater Status: The state of this High Voltage Energy Storage Pack heaterThis parameter is for one of multiple packs in an HVESS.  If there is only one pack in the system, the HVESS parameters should be used. If there ...";
CM_ SG_ 2364659454 Hvsp5ThrmlMngmntSstmHvlStts "HVESP5 Thermal Management System HVIL Status: In multiple HVES configurations, this is the status of the High Voltage Interlock Loop from the viewpoint of this Thermal Management System.00b = HVIL Closed01b = HVIL Open10b = Error11b = Not AvailableTh...";
CM_ SG_ 2364659454 Hvsp5ThrmlMngmntSstmMd "HVESP5 Thermal Management System Mode: Indicates the operating mode of the Thermal Management System.  The heat transfer medium may be (e.g. liquid or air).  The cooling system may be fans, liquid coolant, or a combination of mediums.  The system may...";
CM_ SG_ 2364659454 Hvsp5ThrmlMngmntSstmClntLvl "HVESP5 Thermal Management System Coolant Level: Indicates the coolant level in this HVES Thermal Management System (TMS).This parameter is for one of multiple packs in an HVESS.  If there is only one pack in the system, the HVESS parameters should be...";
CM_ BO_ 2364659710 "High Voltage Energy Storage Pack 5 Data 8";
CM_ SG_ 2364659710 Hvesp5AverageCellVoltage "HVESP5 Average Cell Voltage: The average cell voltage in this High Voltage Energy Storage Pack instance.This parameter is for one of multiple packs in an HVESS.  If there is only one pack in the system, the HVESS parameters should be used. If there a...";
CM_ SG_ 2364659710 Hvsp5HghstCllVltgMdlNmr "HVESP5 Highest Cell Voltage Module Number: Identifies the location of the module containing SPN 11519 (HVESP5 Highest Cell Voltage).This parameter is for one of multiple packs in an HVESS.  If there is only one pack in the system, the HVESS parameter...";
CM_ SG_ 2364659710 Hvsp5HghstCllVltgCllNmr "HVESP5 Highest Cell Voltage Cell Number: Identifies the location of SPN 11519 (HVESP5 Highest Cell Voltage) within SPN 11579 (HVESP5 Highest Cell Voltage Module Number).This parameter is for one of multiple packs in an HVESS.  If there is only one pa...";
CM_ SG_ 2364659710 Hvsp5LwstCllVltgMdlNmr "HVESP5 Lowest Cell Voltage Module Number: Identifies the location of the module containing SPN 11520 (HVESP5 Lowest Cell Voltage).This parameter is for one of multiple packs in an HVESS.  If there is only one pack in the system, the HVESS parameters ...";
CM_ SG_ 2364659710 Hvsp5LwstCllVltgCllNmr "HVESP5 Lowest Cell Voltage Cell Number: Identifies the location of SPN 11520 (HVESP5 Lowest Cell Voltage) within SPN 11581 (HVESP5 Lowest Cell Voltage Module Number).This parameter is for one of multiple packs in an HVESS.  If there is only one pack ...";
CM_ BO_ 2364659966 "High Voltage Energy Storage Pack 5 Data 9";
CM_ SG_ 2364659966 Hvsp5HghstCllTmprtrMdlNmr "HVESP5 Highest Cell Temperature Module Number: Identifies the location of the module containing SPN 11522 (HVESP5 Highest Cell Temperature).This parameter is for one of multiple packs in an HVESS.  If there is only one pack in the system, the HVESS p...";
CM_ SG_ 2364659966 Hvsp5HghstCllTmprtrCllNmr "HVESP5 Highest Cell Temperature Cell Number: Identifies the location of SPN 11522 (HVESP5 Highest Cell Temperature) within SPN 11584 (HVESP5 Highest Cell Temperature Module Number).This parameter is for one of multiple packs in an HVESS.  If there is...";
CM_ SG_ 2364659966 Hvsp5LwstCllTmprtrMdlNmr "HVESP5 Lowest Cell Temperature Module Number: Identifies the location of the module containing SPN 11523 (HVESP5 Lowest Cell Temperature).This parameter is for one of multiple packs in an HVESS.  If there is only one pack in the system, the HVESS par...";
CM_ SG_ 2364659966 Hvsp5LwstCllTmprtrCllNmr "HVESP5 Lowest Cell Temperature Cell Number: Identifies the location of SPN 11523 (HVESP5 Lowest Cell Temperature) within SPN 11586 (HVESP5 Lowest Cell Temperature Module Number).This parameter is for one of multiple packs in an HVESS.  If there is on...";
CM_ SG_ 2364659966 Hvess5ThermalEventDetected "HVESS5 Thermal Event Detected: A sensor has detected the presence of a thermal event at or near High Voltage Energy Storage Pack instance.00b = No Thermal Event Detected01b = Thermal Event Detected10b = Error11b = Not availableThis parameter is for o...";
CM_ SG_ 2364659966 Hvsp5Dt9EmdddIntgrtSpprt "HVESP5 Data 9 Embedded Integrity Support: Indicates SPN 22988 (HVESP5 Data 9 CRC) and SPN 22987 (HVESP5 Data 9 Counter) are supported by the sender.00b = Embedded CRC and Counter are supported by the sender01b = Protection is provided using an extern...";
CM_ SG_ 2364659966 Hvesp5Data9Counter "HVESP5 Data 9 Counter: The message counter is used to detect situations where the transmitting ECU malfunction repeats the same frame all the time. The receiver of the information may use the counter parameter to detect this situation. The transmitti...";
CM_ SG_ 2364659966 Hvesp5Data9Crc "HVESP5 Data 9 CRC: The CRC is defined as follows: - Length: 8 bits- Polynomial: x^8+x^5+x^3+x^2+x+1- Initial Value: FFh- Input Data Reflection: Not reflected- Result Data Reflection: Not reflected- XOR value: FFh SAE makes no claim of the functional ...";
CM_ BO_ 2364660222 "High Voltage Energy Storage Pack 5 Data 10";
CM_ SG_ 2364660222 Hvsp5HghstCllSttOfChrgMdlNmr "HVESP5 Highest Cell State of Charge Module Number: Identifies the location of the module containing SPN 11532 (HVESP5 Highest Cell State of Charge).This parameter is for one of multiple packs in an HVESS.  If there is only one pack in the system, the...";
CM_ SG_ 2364660222 Hvsp5HghstCllSttOfChrgCllNmr "HVESP5 Highest Cell State of Charge Cell Number: Identifies the location of SPN 11532 (HVESP5 Highest Cell State of Charge) within SPN 11588 (HVESP5 Highest Cell State of Charge Module Number).This parameter is for one of multiple packs in an HVESS. ...";
CM_ SG_ 2364660222 Hvsp5LwstCllSttOfChrgMdlNmr "HVESP5 Lowest Cell State of Charge Module Number: Identifies the location of the module containing SPN 11531 (HVESP5 Lowest Cell State of Charge).This parameter is for one of multiple packs in an HVESS.  If there is only one pack in the system, the H...";
CM_ SG_ 2364660222 Hvsp5LwstCllSttOfChrgCllNmr "HVESP5 Lowest Cell State of Charge Cell Number: Identifies the location of SPN 11531 (HVESP5 Lowest Cell State of Charge) within SPN 11590 (HVESP5 Lowest Cell State of Charge Module Number).This parameter is for one of multiple packs in an HVESS.  If...";
CM_ SG_ 2364660222 Hvsp5HghVltgBsAtvIsltnTstRslts "HVESP5 High-Voltage Bus Active Isolation Test Results: The isolation resistance expressed in Ohms per Volt that resulted from the High-Voltage Bus Active Isolation Test.See SPN 11544 (HVESP5 High-Voltage Bus Active Isolation Test Status) for test sta...";
CM_ SG_ 2364660222 Hvsp5HghVltgBsPssvIsltnTstRslts "HVESP5 High-Voltage Bus Passive Isolation Test Results: The isolation resistance expressed in Ohms per Volt that resulted from the High-Voltage Bus Passive Isolation Test.See SPN 11545 (HVESP5 High-Voltage Bus Passive Isolation Test Status) for test ...";
CM_ BO_ 2364660478 "High Voltage Energy Storage Pack 5 Data 11";
CM_ SG_ 2364660478 Hvesp5ActualChargeRate "HVESP5 Actual Charge Rate: This signal represents the actual present charge rate of this High Voltage Energy Storage Pack instance.This parameter is for one of multiple packs in an HVESS. If there is only one pack in the system, the HVESS parameters ...";
CM_ SG_ 2364660478 Hvsp5BsVltgNgtvTChsssGrndVltg "HVESP5 Bus Voltage Negative to Chassis Ground Voltage: Voltage difference between the most negative terminal of the HVES battery and chassis measured on the hybrid or EV system bus side (not the battery side) of any HVES contained output contactor.  ...";
CM_ SG_ 2364660478 Hvsp5VltgLvlNgtvTChsssGrndVltg "HVESP5 Voltage Level Negative to Chassis Ground Voltage: Voltage difference between the most negative terminal of the HVES battery and chassis measured at the battery side of any HVES contained output contactor.  This voltage may be used for system l...";
CM_ BO_ 2364660734 "High Voltage Energy Storage Pack 6 Status 2";
CM_ SG_ 2364660734 Hvsp6DshrgPwrLmtDTSttOfChrg "HVESP6 Discharge Power Limit Due to State of Charge: Indicates whether or not discharge power of this HVES instance is being limited due to state of charge.This parameter is for one of multiple packs in an HVESS.  If there is only one pack in the sys...";
CM_ SG_ 2364660734 Hvsp6DshrgPwrLmtDTBttrTmprtr "HVESP6 Discharge Power Limit Due to Battery Temperature: Indicates whether or not discharge power of this HVES instance is being limited due to battery temperature.This parameter is for one of multiple packs in an HVESS.  If there is only one pack in...";
CM_ SG_ 2364660734 Hvsp6DsPwLtDTBttDstCdt "HVESP6 Discharge Power Limit Due to Battery Diagnostic Condition: Indicates whether or not discharge power of this HVES instance is being limited due to a battery diagnostic condition.This parameter is for one of multiple packs in an HVESS.  If there...";
CM_ SG_ 2364660734 Hvsp6DshrgPwrLmtDTBttrOrCllVltg "HVESP6 Discharge Power Limit Due to Battery or Cell Voltage: Indicates whether or not discharge power of this HVES instance is being limited due to a battery or cell voltage level.This parameter is for one of multiple packs in an HVESS.  If there is ...";
CM_ SG_ 2364660734 Hvsp6DshrgPwrLmtDTBttrCrrnt "HVESP6 Discharge Power Limit Due to Battery Current: Indicates whether or not discharge power of this HVES instance is being limited due to battery current.This parameter is for one of multiple packs in an HVESS.  If there is only one pack in the sys...";
CM_ SG_ 2364660734 Hvsp6DshrgPwrLmtDTAnUndfndCs "HVESP6 Discharge Power Limit Due to an Undefined Cause: Indicates whether or not discharge power of this HVES instance is being limited due to an undefined cause.This parameter is for one of multiple packs in an HVESS.  If there is only one pack in t...";
CM_ SG_ 2364660734 Hvsp6ChrgPwrLmtDTSttOfChrg "HVESP6 Charge Power Limit Due to State of Charge: Indicates whether or not charge power of this HVES instance is being limited due to state of charge.This parameter is for one of multiple packs in an HVESS.  If there is only one pack in the system, t...";
CM_ SG_ 2364660734 Hvsp6ChrgPwrLmtDTBttrTmprtr "HVESP6 Charge Power Limit Due to Battery Temperature: Indicates whether or not charge power of this HVES instance is being limited due to battery temperature.This parameter is for one of multiple packs in an HVESS.  If there is only one pack in the s...";
CM_ SG_ 2364660734 Hvsp6ChrgPwrLmtDTBttrDgnstCndtn "HVESP6 Charge Power Limit Due to Battery Diagnostic Condition: Indicates whether or not charge power of this HVES instance is being limited due to a battery diagnostic condition.This parameter is for one of multiple packs in an HVESS.  If there is on...";
CM_ SG_ 2364660734 Hvsp6ChrgPwrLmtDTBttrOrCllVltg "HVESP6 Charge Power Limit Due to Battery or Cell Voltage: Indicates whether or not charge power of this HVES instance is being limited due to a battery or cell voltage level.This parameter is for one of multiple packs in an HVESS.  If there is only o...";
CM_ SG_ 2364660734 Hvsp6ChrgPwrLmtDTBttrCrrnt "HVESP6 Charge Power Limit Due to Battery Current: Indicates whether or not charge power of this HVES instance is being limited due to battery current.This parameter is for one of multiple packs in an HVESS.  If there is only one pack in the system, t...";
CM_ SG_ 2364660734 Hvsp6ChrgPwrLmtDTAnUndfndCs "HVESP6 Charge Power Limit Due to an Undefined Cause: Indicates whether or not charge power of this HVES instance is being limited due to an undefined cause.This parameter is for one of multiple packs in an HVESS.  If there is only one pack in the sys...";
CM_ BO_ 2364660990 "High Voltage Energy Storage Pack 6 Data 1";
CM_ SG_ 2364660990 Hvesp6AvailableDischargePower "HVESP6 Available Discharge Power: The rate at which this High Voltage Energy Storage Pack instance can currently provide energy for propulsion or other uses.This parameter is for one of multiple packs in an HVESS.  If there is only one pack in the sy...";
CM_ SG_ 2364660990 Hvesp6AvailableChargePower "HVESP6 Available Charge Power: The rate at which this High Voltage Energy Storage Pack instance can currently receive energy from a regenerative or recharging system.This parameter is for one of multiple packs in an HVESS.  If there is only one pack ...";
CM_ SG_ 2364660990 Hvesp6VoltageLevel "HVESP6 Voltage Level: The voltage level of this High Voltage Energy Storage Pack instance. This parameter should be synchronized with SPN 11633 (HVESP6 Current) such that a realized power value can be calculated.  If the HVES component physically con...";
CM_ SG_ 2364660990 Hvesp6Current "HVESP6 Current: The current in or out of this High Voltage Energy Storage Pack instance. This parameter should be synchronized with SPN 11632 (HVESP6 Voltage Level) such that a realized power value can be calculated.  This parameter is defined from t...";
CM_ BO_ 2364661246 "High Voltage Energy Storage Pack 6 Data 2";
CM_ SG_ 2364661246 Hvesp6FastUpdateStateOfCharge "HVESP6 Fast Update State of Charge: Indicates this High Voltage Energy Storage Pack instance state of charge.  0% means no charge remaining, 100% means the system is fully charged in terms of physical limits of this energy storage pack instance.  Acc...";
CM_ SG_ 2364661246 Hvesp6HighestCellVoltage "HVESP6 Highest Cell Voltage: The highest voltage level reported by any cell in this High Voltage Energy Storage Pack instance. If a single voltage sensor covers more than one cell, the value in this parameter is for the smallest group of cells measur...";
CM_ SG_ 2364661246 Hvesp6LowestCellVoltage "HVESP6 Lowest Cell Voltage: The lowest voltage level reported by any cell in this High Voltage Energy Storage Pack instance. If a single voltage sensor covers more than one cell, the value in this parameter is for the smallest group of cells measured...";
CM_ SG_ 2364661246 Hvsp6CllVltgDffrntlStts "HVESP6 Cell Voltage Differential Status: Indicates whether or not the differential between the highest and lowest cell voltages are within acceptable limits, according to this High Voltage Energy Storage Pack instance. The actual voltage differential...";
CM_ BO_ 2364661502 "High Voltage Energy Storage Pack 6 Data 3";
CM_ SG_ 2364661502 Hvesp6HighestCellTemperature "HVESP6 Highest Cell Temperature: The highest temperature level reported by any cell in this High Voltage Energy Storage Pack instance.  If a single temperature sensor covers more than one cell, the value in this parameter is for the smallest group of...";
CM_ SG_ 2364661502 Hvesp6LowestCellTemperature "HVESP6 Lowest Cell Temperature: The lowest temperature level reported by any cell in this High Voltage Energy Storage Pack instance.  If a single temperature sensor covers more than one cell, the value in this parameter is for the smallest group of c...";
CM_ SG_ 2364661502 Hvesp6AverageCellTemperature "HVESP6 Average Cell Temperature: The average temperature level of all cells in this High Voltage Energy Storage Pack instance.This parameter is for one of multiple packs in an HVESS.  If there is only one pack in the system, the HVESS parameters shou...";
CM_ SG_ 2364661502 Hvsp6CllTmprtrDffrntlStts "HVESP6 Cell Temperature Differential Status: Indicates whether or not the differential between the highest and lowest cell temperatures are within acceptable limits per this High Voltage Energy Storage Pack instance.  The actual temperature different...";
CM_ BO_ 2364661758 "High Voltage Energy Storage Pack 6 Data 4";
CM_ SG_ 2364661758 Hvesp6DischargeCapacity "HVESP6 Discharge Capacity: The amount of stored electrical charge in this High Voltage Energy Storage Pack instance that is available for use by the hybrid or EV system, i.e. 'how full is the tank'.  See SPN 11670 (HVESP6 Discharge Energy Capacity) f...";
CM_ SG_ 2364661758 Hvesp6ChargeCapacity "HVESP6 Charge Capacity: The amount of unused electrical charge storage in this High Voltage Energy Storage Pack instance that is available to be filled by charging, i.e. 'how much empty space is remaining in the tank'.  See SPN 11671 (HVESP6 Charge E...";
CM_ SG_ 2364661758 Hvesp6CellBalancingCount "HVESP6 Cell Balancing Count: The number of cells that are currently being balanced in this High Voltage Energy Storage Pack instance.This parameter is for one of multiple packs in an HVESS.  If there is only one pack in the system, the HVESS paramete...";
CM_ BO_ 2364662014 "High Voltage Energy Storage Pack 6 Data 5";
CM_ SG_ 2364662014 Hvesp6LowestCellStateOfCharge "HVESP6 Lowest Cell State of Charge: Indicates the state of charge of the lowest-charged cell in this High Voltage Energy Storage Pack instance.  0% means no charge remaining, 100% means the cell is fully charged.   If a single state of charge value c...";
CM_ SG_ 2364662014 Hvesp6HighestCellStateOfCharge "HVESP6 Highest Cell State of Charge: Indicates the state of charge of the highest-charged cell in this High Voltage Energy Storage Pack instance.  0% means no charge remaining, 100% means the cell is fully charged.  If a single state of charge value ...";
CM_ SG_ 2364662014 Hvsp6MxmmInstntnsDshrgCrrntLmt "HVESP6 Maximum Instantaneous Discharge Current Limit: The maximum instantaneous current flow limit out of this High Voltage Energy Storage Pack instance. This parameter is defined from the high voltage energy storage pack's point of view and should r...";
CM_ SG_ 2364662014 Hvsp6MxmmInstntnsChrgCrrntLmt "HVESP6 Maximum Instantaneous Charge Current Limit: The maximum instantaneous current flow limit into this High Voltage Energy Storage Pack instance. This parameter is defined from the high voltage energy storage pack's point of view and should reflec...";
CM_ BO_ 2364662270 "High Voltage Energy Storage Pack 6 Data 6";
CM_ SG_ 2364662270 Hvesp6BusVoltage "HVESP6 Bus Voltage: The voltage level of the high voltage bus, as measured by this High Voltage Energy Storage Pack instance on the bus side (not the battery side) of its contactors.This parameter is for one of multiple packs in an HVESS.  If there i...";
CM_ SG_ 2364662270 Hvesp6IgnitionVoltage "HVESP6 Ignition Voltage: The voltage level at the ignition input of this High Voltage Energy Storage Pack controller.This parameter is for one of multiple packs in an HVESS.  If there is only one pack in the system, the HVESS parameters should be use...";
CM_ SG_ 2364662270 Hvesp6IntakeCoolantTemperature "HVESP6 Intake Coolant Temperature: The temperature of liquid coolant as it enters this High Voltage Energy Storage Pack instance.This parameter is for one of multiple packs in an HVESS.  If there is only one pack in the system, the HVESS parameters s...";
CM_ SG_ 2364662270 Hvesp6OutletCoolantTemperature "HVESP6 Outlet Coolant Temperature: The temperature of liquid coolant as it exits this High Voltage Energy Storage Pack instance.This parameter is for one of multiple packs in an HVESS.  If there is only one pack in the system, the HVESS parameters sh...";
CM_ SG_ 2364662270 Hvesp6ElectronicsTemperature "HVESP6 Electronics Temperature: The temperature of the electronics or control modules in this High Voltage Energy Storage Pack instance.  If there are multiple temperature sensors then this parameter would be set to the maximum sensor reading.This pa...";
CM_ SG_ 2364662270 Hvesp6Temperature "HVESP6 Temperature: The temperature of this High Voltage Energy Storage Pack instance. The value may be determined from a unique sensor specifically for this purpose, or by aggregating various temperature sensor readings within the pack.This paramete...";
CM_ BO_ 2364662526 "High Voltage Energy Storage Pack 6 Status 1";
CM_ SG_ 2364662526 Hvesp6HvilStatus "HVESP6 HVIL Status: Status of the High Voltage Interlock Loop from the viewpoint of this High Voltage Energy Storage Pack instance.This parameter is for one of multiple packs in an HVESS. If there is only one pack in the system, the HVESS parameters ...";
CM_ SG_ 2364662526 Hvesp6InertiaSwitchStatus "HVESP6 Inertia Switch Status: Switch indicating that an impact has been sensed by this High Voltage Energy Storage Pack instance. The impact indication may require action by another controller, or by this HVES instance itself.  For example, a control...";
CM_ SG_ 2364662526 Hvesp6StateOfChargeStatus "HVESP6 State of Charge Status: Status of this High Voltage Energy Storage Pack instance State of Charge (SOC).  Note:  A given HVES controller may not support all of the states.This parameter is for one of multiple packs in an HVESS.  If there is onl...";
CM_ SG_ 2364662526 Hvesp6CellBalanceStatus "HVESP6 Cell Balance Status: Indicates whether or not the cells in this High Voltage Energy Storage Pack instance are balanced.This parameter is for one of multiple packs in an HVESS.  If there is only one pack in the system, the HVESS parameters shou...";
CM_ SG_ 2364662526 Hvesp6CellBalancingActive "HVESP6 Cell Balancing Active: Indicates whether or not the cells in this High Voltage Energy Storage Pack instance are currently being balanced.This parameter is for one of multiple packs in an HVESS.  If there is only one pack in the system, the HVE...";
CM_ SG_ 2364662526 Hvesp6InternalChargerStatus "HVESP6 Internal Charger Status: Indicates that the charger in this HVES instance is on.  External chargers may use the External Energy Source Connection Status (SPN 7898) and related SPs.This parameter is for one of multiple packs in an HVESS. If the...";
CM_ SG_ 2364662526 Hvesp6OperationalStatus "HVESP6 Operational Status: Provides feedback on where this High Voltage Energy Storage Pack instance is in its operating spectrum, and includes feedback in response to the Operation Consent [i.e. SPN 11615 (HVESP6 Operation Consent)] and Power Down C...";
CM_ SG_ 2364662526 Hvesp6Status1Counter "HVESP6 Status 1 Counter: The message counter is used to detect situations where the transmitting ECU malfunction repeats the same frame all the time. The receiver of the information may use the counter parameter to detect this situation. The transmit...";
CM_ SG_ 2364662526 Hvesp6Status1Crc "HVESP6 Status 1 CRC: The CRC is defined as follows: - Length: 8 bits- Polynomial: x^8+x^5+x^3+x^2+x+1- Initial Value: FFh- Input Data Reflection: Not reflected- Result Data Reflection: Not reflected- XOR value: FFh SAE makes no claim of the functiona...";
CM_ SG_ 2364662526 Hvsp6HghVltgBsPstvCnttrStt "HVESP6 High-Voltage Bus (Positive) Contactor State: Position of this High Voltage Energy Storage Pack instance positive side bus contactor.  When this contactor is closed, the positive side of this HVES instance is connected to the positive side of t...";
CM_ SG_ 2364662526 Hvsp6HghVltgBsNgtvCnttrStt "HVESP6 High-Voltage Bus (Negative) Contactor State: Position of this High Voltage Energy Storage Pack instance negative side bus contactor.  When this contactor is closed, the negative side of this HVES instance is connected to the negative side of t...";
CM_ SG_ 2364662526 Hvsp6HghVltgBsDsnntFrwrnng "HVESP6 High-Voltage Bus Disconnect Forewarning: Indicates that this High Voltage Energy Storage Pack instance is about to disconnect from the high voltage bus due to unacceptable conditions.This parameter is for one of multiple packs in an HVESS. If ...";
CM_ SG_ 2364662526 Hvsp6HghVltgBsPrChrgRlStt "HVESP6 High-Voltage Bus Pre-Charge Relay State: Position of the high-voltage bus contactor pre-charge relay.  When this relay is closed, this High Voltage Energy Storage Pack instance is bringing the high-voltage bus up to its operating level.This pa...";
CM_ SG_ 2364662526 Hvsp6CntrOfPkCnttrStt "HVESP6 Center of Pack Contactor State: Position of the center high-voltage contactor.  When this contactor is closed, the positive half of this High Voltage Energy Storage Pack instance is connected to the negative half.  If a system controls the pos...";
CM_ SG_ 2364662526 Hvsp6HghVltgBsAtvIsltnTstStts "HVESP6 High-Voltage Bus Active Isolation Test Status: Status of the high-voltage bus electrical active isolation test as performed by this High Voltage Energy Storage Pack instance.This parameter is for one of multiple packs in an HVESS. If there is ...";
CM_ SG_ 2364662526 Hvsp6HghVltgBsPssvIsltnTstStts "HVESP6 High-Voltage Bus Passive Isolation Test Status: Status of the high-voltage bus electrical passive isolation test as performed by this High Voltage Energy Storage Pack instance.This parameter is for one of multiple packs in an HVESS. If there i...";
CM_ SG_ 2364662526 Hvsp6HghVltgBsCnntnStts "HVESP6 High-Voltage Bus Connection Status: This parameter provides high level feedback on this High Voltage Energy Storage Pack instance high voltage bus connection.  For specific contactor information, see SPN 11655 (HVESP6 High-Voltage Bus (Positiv...";
CM_ BO_ 2364662782 "High Voltage Energy Storage Pack 6 Data 7";
CM_ SG_ 2364662782 Hvesp6DischargeEnergyCapacity "HVESP6 Discharge Energy Capacity: The amount of stored electrical energy in this High Voltage Energy Storage Pack instance that is available for use by the hybrid or EV system, i.e. 'how full is the tank'.  See SPN 11642 (HVESP6 Discharge Capacity) f...";
CM_ SG_ 2364662782 Hvesp6ChargeEnergyCapacity "HVESP6 Charge Energy Capacity: The amount of unused electrical energy storage available to be filled by charging this High Voltage Energy Storage Pack instance, i.e. 'how much empty space is remaining in the tank'.  See SPN 11643 (HVESP6 Charge Capac...";
CM_ SG_ 2364662782 Hvesp6MaximumChargeVoltageLimit "HVESP6 Maximum Charge Voltage Limit: The maximum voltage level not to be exceeded while charging this High Voltage Energy Storage Pack instance.  If this parameter is not supported, the maximum charge voltage should be limited to SPN 11714 (HVESP6 Re...";
CM_ BO_ 2364663038 "High Voltage Energy Storage Pack 6 Module Status 1";
CM_ SG_ 2364663038 Hvesp6Module1OperationalStatus "HVESP6 Module 1 Operational Status: Operational Status of Module 1 in this High Voltage Energy Storage Pack Instance.  Not Operational is used when the module is initializing or not able to function (e.g. internal module level monitors have failed). ...";
CM_ SG_ 2364663038 Hvesp6Module2OperationalStatus "HVESP6 Module 2 Operational Status: Operational Status of Module 2 in this High Voltage Energy Storage Pack Instance.  Not Operational is used when the module is initializing or not able to function (e.g. internal module level monitors have failed). ...";
CM_ SG_ 2364663038 Hvesp6Module3OperationalStatus "HVESP6 Module 3 Operational Status: Operational Status of Module 3 in this High Voltage Energy Storage Pack Instance.  Not Operational is used when the module is initializing or not able to function (e.g. internal module level monitors have failed). ...";
CM_ SG_ 2364663038 Hvesp6Module4OperationalStatus "HVESP6 Module 4 Operational Status: Operational Status of Module 4 in this High Voltage Energy Storage Pack Instance.  Not Operational is used when the module is initializing or not able to function (e.g. internal module level monitors have failed). ...";
CM_ SG_ 2364663038 Hvesp6Module5OperationalStatus "HVESP6 Module 5 Operational Status: Operational Status of Module 5 in this High Voltage Energy Storage Pack Instance.  Not Operational is used when the module is initializing or not able to function (e.g. internal module level monitors have failed). ...";
CM_ SG_ 2364663038 Hvesp6Module6OperationalStatus "HVESP6 Module 6 Operational Status: Operational Status of Module 6 in this High Voltage Energy Storage Pack Instance.  Not Operational is used when the module is initializing or not able to function (e.g. internal module level monitors have failed). ...";
CM_ SG_ 2364663038 Hvesp6Module7OperationalStatus "HVESP6 Module 7 Operational Status: Operational Status of Module 7 in this High Voltage Energy Storage Pack Instance.  Not Operational is used when the module is initializing or not able to function (e.g. internal module level monitors have failed). ...";
CM_ SG_ 2364663038 Hvesp6Module8OperationalStatus "HVESP6 Module 8 Operational Status: Operational Status of Module 8 in this High Voltage Energy Storage Pack Instance.  Not Operational is used when the module is initializing or not able to function (e.g. internal module level monitors have failed). ...";
CM_ SG_ 2364663038 Hvesp6Module9OperationalStatus "HVESP6 Module 9 Operational Status: Operational Status of Module 9 in this High Voltage Energy Storage Pack Instance.  Not Operational is used when the module is initializing or not able to function (e.g. internal module level monitors have failed). ...";
CM_ SG_ 2364663038 Hvesp6Module10OperationalStatus "HVESP6 Module 10 Operational Status: Operational Status of Module 10 in this High Voltage Energy Storage Pack Instance.  Not Operational is used when the module is initializing or not able to function (e.g. internal module level monitors have failed)...";
CM_ SG_ 2364663038 Hvesp6Module11OperationalStatus "HVESP6 Module 11 Operational Status: Operational Status of Module 11 in this High Voltage Energy Storage Pack Instance.  Not Operational is used when the module is initializing or not able to function (e.g. internal module level monitors have failed)...";
CM_ SG_ 2364663038 Hvesp6Module12OperationalStatus "HVESP6 Module 12 Operational Status: Operational Status of Module 12 in this High Voltage Energy Storage Pack Instance.  Not Operational is used when the module is initializing or not able to function (e.g. internal module level monitors have failed)...";
CM_ SG_ 2364663038 Hvesp6Module13OperationalStatus "HVESP6 Module 13 Operational Status: Operational Status of Module 13 in this High Voltage Energy Storage Pack Instance.  Not Operational is used when the module is initializing or not able to function (e.g. internal module level monitors have failed)...";
CM_ SG_ 2364663038 Hvesp6Module14OperationalStatus "HVESP6 Module 14 Operational Status: Operational Status of Module 14 in this High Voltage Energy Storage Pack Instance.  Not Operational is used when the module is initializing or not able to function (e.g. internal module level monitors have failed)...";
CM_ SG_ 2364663038 Hvesp6Module15OperationalStatus "HVESP6 Module 15 Operational Status: Operational Status of Module 15 in this High Voltage Energy Storage Pack Instance.  Not Operational is used when the module is initializing or not able to function (e.g. internal module level monitors have failed)...";
CM_ SG_ 2364663038 Hvesp6Module16OperationalStatus "HVESP6 Module 16 Operational Status: Operational Status of Module 16 in this High Voltage Energy Storage Pack Instance.  Not Operational is used when the module is initializing or not able to function (e.g. internal module level monitors have failed)...";
CM_ SG_ 2364663038 Hvesp6Module17OperationalStatus "HVESP6 Module 17 Operational Status: Operational Status of Module 17 in this High Voltage Energy Storage System (or Pack 1 in systems with only one pack).  Not Operational is used when the module is initializing or not able to function (e.g. internal...";
CM_ SG_ 2364663038 Hvesp6Module18OperationalStatus "HVESP6 Module 18 Operational Status: Operational Status of Module 18 in this High Voltage Energy Storage System (or Pack 1 in systems with only one pack).  Not Operational is used when the module is initializing or not able to function (e.g. internal...";
CM_ SG_ 2364663038 Hvesp6Module19OperationalStatus "HVESP6 Module 19 Operational Status: Operational Status of Module 19 in this High Voltage Energy Storage System (or Pack 1 in systems with only one pack).  Not Operational is used when the module is initializing or not able to function (e.g. internal...";
CM_ SG_ 2364663038 Hvesp6Module20OperationalStatus "HVESP6 Module 20 Operational Status: Operational Status of Module 20 in this High Voltage Energy Storage System (or Pack 1 in systems with only one pack).  Not Operational is used when the module is initializing or not able to function (e.g. internal...";
CM_ SG_ 2364663038 Hvesp6Module21OperationalStatus "HVESP6 Module 21 Operational Status: Operational Status of Module 21 in this High Voltage Energy Storage System (or Pack 1 in systems with only one pack).  Not Operational is used when the module is initializing or not able to function (e.g. internal...";
CM_ SG_ 2364663038 Hvesp6Module22OperationalStatus "HVESP6 Module 22 Operational Status: Operational Status of Module 22 in this High Voltage Energy Storage System (or Pack 1 in systems with only one pack).  Not Operational is used when the module is initializing or not able to function (e.g. internal...";
CM_ SG_ 2364663038 Hvesp6Module23OperationalStatus "HVESP6 Module 23 Operational Status: Operational Status of Module 23 in this High Voltage Energy Storage System (or Pack 1 in systems with only one pack).  Not Operational is used when the module is initializing or not able to function (e.g. internal...";
CM_ SG_ 2364663038 Hvesp6Module24OperationalStatus "HVESP6 Module 24 Operational Status: Operational Status of Module 24 in this High Voltage Energy Storage System (or Pack 1 in systems with only one pack).  Not Operational is used when the module is initializing or not able to function (e.g. internal...";
CM_ SG_ 2364663038 Hvesp6Module25OperationalStatus "HVESP6 Module 25 Operational Status: Operational Status of Module 25 in this High Voltage Energy Storage System (or Pack 1 in systems with only one pack).  Not Operational is used when the module is initializing or not able to function (e.g. internal...";
CM_ SG_ 2364663038 Hvesp6Module26OperationalStatus "HVESP6 Module 26 Operational Status: Operational Status of Module 26 in this High Voltage Energy Storage System (or Pack 1 in systems with only one pack).  Not Operational is used when the module is initializing or not able to function (e.g. internal...";
CM_ SG_ 2364663038 Hvesp6Module27OperationalStatus "HVESP6 Module 27 Operational Status: Operational Status of Module 27 in this High Voltage Energy Storage System (or Pack 1 in systems with only one pack).  Not Operational is used when the module is initializing or not able to function (e.g. internal...";
CM_ SG_ 2364663038 Hvesp6Module28OperationalStatus "HVESP6 Module 28 Operational Status: Operational Status of Module 28 in this High Voltage Energy Storage System (or Pack 1 in systems with only one pack).  Not Operational is used when the module is initializing or not able to function (e.g. internal...";
CM_ SG_ 2364663038 Hvesp6Module29OperationalStatus "HVESP6 Module 29 Operational Status: Operational Status of Module 29 in this High Voltage Energy Storage System (or Pack 1 in systems with only one pack).  Not Operational is used when the module is initializing or not able to function (e.g. internal...";
CM_ SG_ 2364663038 Hvesp6Module30OperationalStatus "HVESP6 Module 30 Operational Status: Operational Status of Module 30 in this High Voltage Energy Storage System (or Pack 1 in systems with only one pack).  Not Operational is used when the module is initializing or not able to function (e.g. internal...";
CM_ SG_ 2364663038 Hvesp6Module31OperationalStatus "HVESP6 Module 31 Operational Status: Operational Status of Module 31 in this High Voltage Energy Storage System (or Pack 1 in systems with only one pack).  Not Operational is used when the module is initializing or not able to function (e.g. internal...";
CM_ SG_ 2364663038 Hvesp6Module32OperationalStatus "HVESP6 Module 32 Operational Status: Operational Status of Module 32 in this High Voltage Energy Storage System (or Pack 1 in systems with only one pack).  Not Operational is used when the module is initializing or not able to function (e.g. internal...";
CM_ BO_ 2364663294 "High Voltage Energy Storage Pack 6 Thermal Management System Status 1";
CM_ SG_ 2364663294 Hvsp6ThrmlMngmntSstmSlInptPwr "HVESP6 Thermal Management System SLI Input Power: This is the low-voltage power consumed by this HVES Thermal Management System (TMS).This parameter is for one of multiple packs in an HVESS.  If there is only one pack in the system, the HVESS paramet...";
CM_ SG_ 2364663294 Hvsp6TMtSstHVtIptPw "HVESP6 Thermal Management System High-Voltage Input Power: This is the high-voltage power consumed by this HVES Thermal Management System (TMS).This parameter is for one of multiple packs in an HVESS.  If there is only one pack in the system, the HVE...";
CM_ SG_ 2364663294 Hvsp6ThrmlMngmntSstmCmprssrSpd "HVESP6 Thermal Management System Compressor Speed: When this High Voltage Energy Storage Pack Thermal Management System is equipped with an active cooling system (e.g. air conditioner), this is the Compressor Speed.This parameter is for one of multip...";
CM_ SG_ 2364663294 Hvsp6ThrmlMngmntSstmRltvHmdt "HVESP6 Thermal Management System Relative Humidty: When this High Voltage Energy Storage Pack Thermal Management System is equipped with a relative humidity sensor, this is the  measured Relative Humidity.This parameter is for one of multiple packs i...";
CM_ SG_ 2364663294 Hvsp6ThrmlMngmntSstmHtrStts "HVESP6 Thermal Management System Heater Status: The state of this High Voltage Energy Storage Pack heaterThis parameter is for one of multiple packs in an HVESS.  If there is only one pack in the system, the HVESS parameters should be used. If there ...";
CM_ SG_ 2364663294 Hvsp6ThrmlMngmntSstmHvlStts "HVESP6 Thermal Management System HVIL Status: In multiple HVES configurations, this is the status of the High Voltage Interlock Loop from the viewpoint of this Thermal Management System.00b = HVIL Closed01b = HVIL Open10b = Error11b = Not AvailableTh...";
CM_ SG_ 2364663294 Hvsp6ThrmlMngmntSstmMd "HVESP6 Thermal Management System Mode: Indicates the operating mode of the Thermal Management System.  The heat transfer medium may be (e.g. liquid or air).  The cooling system may be fans, liquid coolant, or a combination of mediums.  The system may...";
CM_ SG_ 2364663294 Hvsp6ThrmlMngmntSstmClntLvl "HVESP6 Thermal Management System Coolant Level: Indicates the coolant level in this HVES Thermal Management System (TMS).This parameter is for one of multiple packs in an HVESS.  If there is only one pack in the system, the HVESS parameters should be...";
CM_ BO_ 2364663550 "High Voltage Energy Storage Pack 6 Data 8";
CM_ SG_ 2364663550 Hvesp6AverageCellVoltage "HVESP6 Average Cell Voltage: The average cell voltage in this High Voltage Energy Storage Pack instance.This parameter is for one of multiple packs in an HVESS.  If there is only one pack in the system, the HVESS parameters should be used. If there a...";
CM_ SG_ 2364663550 Hvsp6HghstCllVltgMdlNmr "HVESP6 Highest Cell Voltage Module Number: Identifies the location of the module containing SPN 11635 (HVESP6 Highest Cell Voltage).This parameter is for one of multiple packs in an HVESS.  If there is only one pack in the system, the HVESS parameter...";
CM_ SG_ 2364663550 Hvsp6HghstCllVltgCllNmr "HVESP6 Highest Cell Voltage Cell Number: Identifies the location of SPN 11635 (HVESP6 Highest Cell Voltage) within SPN 11695 (HVESP6 Highest Cell Voltage Module Number).This parameter is for one of multiple packs in an HVESS.  If there is only one pa...";
CM_ SG_ 2364663550 Hvsp6LwstCllVltgMdlNmr "HVESP6 Lowest Cell Voltage Module Number: Identifies the location of the module containing SPN 11636 (HVESP6 Lowest Cell Voltage).This parameter is for one of multiple packs in an HVESS.  If there is only one pack in the system, the HVESS parameters ...";
CM_ SG_ 2364663550 Hvsp6LwstCllVltgCllNmr "HVESP6 Lowest Cell Voltage Cell Number: Identifies the location of SPN 11636 (HVESP6 Lowest Cell Voltage) within SPN 11697 (HVESP6 Lowest Cell Voltage Module Number).This parameter is for one of multiple packs in an HVESS.  If there is only one pack ...";
CM_ BO_ 2364663806 "High Voltage Energy Storage Pack 6 Data 9";
CM_ SG_ 2364663806 Hvsp6HghstCllTmprtrMdlNmr "HVESP6 Highest Cell Temperature Module Number: Identifies the location of the module containing SPN 11638 (HVESP6 Highest Cell Temperature).This parameter is for one of multiple packs in an HVESS.  If there is only one pack in the system, the HVESS p...";
CM_ SG_ 2364663806 Hvsp6HghstCllTmprtrCllNmr "HVESP6 Highest Cell Temperature Cell Number: Identifies the location of SPN 11638 (HVESP6 Highest Cell Temperature) within SPN 11700 (HVESP6 Highest Cell Temperature Module Number).This parameter is for one of multiple packs in an HVESS.  If there is...";
CM_ SG_ 2364663806 Hvsp6LwstCllTmprtrMdlNmr "HVESP6 Lowest Cell Temperature Module Number: Identifies the location of the module containing SPN 11639 (HVESP6 Lowest Cell Temperature).This parameter is for one of multiple packs in an HVESS.  If there is only one pack in the system, the HVESS par...";
CM_ SG_ 2364663806 Hvsp6LwstCllTmprtrCllNmr "HVESP6 Lowest Cell Temperature Cell Number: Identifies the location of SPN 11639 (HVESP6 Lowest Cell Temperature) within SPN 11702 (HVESP6 Lowest Cell Temperature Module Number).This parameter is for one of multiple packs in an HVESS.  If there is on...";
CM_ SG_ 2364663806 Hvess6ThermalEventDetected "HVESS6 Thermal Event Detected: A sensor has detected the presence of a thermal event at or near High Voltage Energy Storage Pack instance.00b = No Thermal Event Detected01b = Thermal Event Detected10b = Error11b = Not availableThis parameter is for o...";
CM_ SG_ 2364663806 Hvsp6Dt9EmdddIntgrtSpprt "HVESP6 Data 9 Embedded Integrity Support: Indicates SPN 22991 (HVESP6 Data 9 CRC) and SPN 22990 (HVESP6 Data 9 Counter) are supported by the sender.00b = Embedded CRC and Counter are supported by the sender01b = Protection is provided using an extern...";
CM_ SG_ 2364663806 Hvesp6Data9Counter "HVESP6 Data 9 Counter: The message counter is used to detect situations where the transmitting ECU malfunction repeats the same frame all the time. The receiver of the information may use the counter parameter to detect this situation. The transmitti...";
CM_ SG_ 2364663806 Hvesp6Data9Crc "HVESP6 Data 9 CRC: The CRC is defined as follows: - Length: 8 bits- Polynomial: x^8+x^5+x^3+x^2+x+1- Initial Value: FFh- Input Data Reflection: Not reflected- Result Data Reflection: Not reflected- XOR value: FFh SAE makes no claim of the functional ...";
CM_ BO_ 2364664062 "High Voltage Energy Storage Pack 6 Data 10";
CM_ SG_ 2364664062 Hvsp6HghstCllSttOfChrgMdlNmr "HVESP6 Highest Cell State of Charge Module Number: Identifies the location of the module containing SPN 11648 (HVESP6 Highest Cell State of Charge).This parameter is for one of multiple packs in an HVESS.  If there is only one pack in the system, the...";
CM_ SG_ 2364664062 Hvsp6HghstCllSttOfChrgCllNmr "HVESP6 Highest Cell State of Charge Cell Number: Identifies the location of SPN 11648 (HVESP6 Highest Cell State of Charge) within SPN 11704 (HVESP6 Highest Cell State of Charge Module Number).This parameter is for one of multiple packs in an HVESS. ...";
CM_ SG_ 2364664062 Hvsp6LwstCllSttOfChrgMdlNmr "HVESP6 Lowest Cell State of Charge Module Number: Identifies the location of the module containing SPN 11647 (HVESP6 Lowest Cell State of Charge).This parameter is for one of multiple packs in an HVESS.  If there is only one pack in the system, the H...";
CM_ SG_ 2364664062 Hvsp6LwstCllSttOfChrgCllNmr "HVESP6 Lowest Cell State of Charge Cell Number: Identifies the location of SPN 11647 (HVESP6 Lowest Cell State of Charge) within SPN 11706 (HVESP6 Lowest Cell State of Charge Module Number).This parameter is for one of multiple packs in an HVESS.  If...";
CM_ SG_ 2364664062 Hvsp6HghVltgBsAtvIsltnTstRslts "HVESP6 High-Voltage Bus Active Isolation Test Results: The isolation resistance expressed in Ohms per Volt that resulted from the High-Voltage Bus Active Isolation Test.See SPN 11660 (HVESP6 High-Voltage Bus Active Isolation Test Status) for test sta...";
CM_ SG_ 2364664062 Hvsp6HghVltgBsPssvIsltnTstRslts "HVESP6 High-Voltage Bus Passive Isolation Test Results: The isolation resistance expressed in Ohms per Volt that resulted from the High-Voltage Bus Passive Isolation Test.See SPN 11661 (HVESP6 High-Voltage Bus Passive Isolation Test Status) for test ...";
CM_ BO_ 2364664318 "High Voltage Energy Storage Pack 6 Data 11";
CM_ SG_ 2364664318 Hvesp6ActualChargeRate "HVESP6 Actual Charge Rate: This signal represents the actual present charge rate of this High Voltage Energy Storage Pack instance.This parameter is for one of multiple packs in an HVESS. If there is only one pack in the system, the HVESS parameters ...";
CM_ SG_ 2364664318 Hvsp6BsVltgNgtvTChsssGrndVltg "HVESP6 Bus Voltage Negative to Chassis Ground Voltage: Voltage difference between the most negative terminal of the HVES battery and chassis measured on the hybrid or EV system bus side (not the battery side) of any HVES contained output contactor.  ...";
CM_ SG_ 2364664318 Hvsp6VltgLvlNgtvTChsssGrndVltg "HVESP6 Voltage Level Negative to Chassis Ground Voltage: Voltage difference between the most negative terminal of the HVES battery and chassis measured at the battery side of any HVES contained output contactor.  This voltage may be used for system l...";
CM_ BO_ 2364664574 "Motor/Generator 3 Inverter Mode Feedback 1";
CM_ SG_ 2364664574 MtrGnrtr3InvrtrMdFdk1Cntr "Motor/Generator 3 Inverter Mode Feedback 1 Counter: The message counter is used to detect situations where the transmitting ECU malfunction repeats the same frame all the time. The receiver of the information may use the counter parameter to detect t...";
CM_ SG_ 2364664574 MtrGnrtr3InvrtrCntrlLmtsOvrrdMd "Motor/Generator 3 Inverter Control Limits Override Mode: During normal operation this will have the same value as SPN 11810 [Control Limits Request Override Mode].  0 = Operating limits are not overridden.  If a limit was previously active, then it h...";
CM_ SG_ 2364664574 MtrGnrtr3InvrtrCntrlStpntMd "Motor/Generator 3 Inverter Control Setpoint Mode: Reports the inverter mode (See SPN 11813 [Control Setpoint Mode Request] for requested mode).Passive modes:  0 = Powered On - the inverter is commanded to be powered on and able to communicate, but th...";
CM_ SG_ 2364664574 MtrGnrtr3InvrtrMdFdk1Cr "Motor/Generator 3 Inverter Mode Feedback 1 CRC: The CRC is defined as follows: - Length: 8 bits- Polynomial: x^8+x^5+x^3+x^2+x+1- Initial Value: FFh- Input Data Reflection: Not reflected- Result Data Reflection: Not reflected- XOR value: FFh SAE make...";
CM_ SG_ 2364664574 MtrGnrtr3InvrtrHvlStts "Motor/Generator 3 Inverter HVIL Status: Reports the High Voltage Interlock Loop (HVIL) state.00b = HVIL Closed01b = HVIL Open10b = Error11b = Not Available";
CM_ BO_ 2565991422 "Motor/Generator 3 Inverter Limits Active Power";
CM_ SG_ 2565991422 MtrGnrtr3InvrtrLmtsAtvPwrCntr "Motor/Generator 3 Inverter Limits Active Power Counter: The message counter is used to detect situations where the transmitting ECU malfunction repeats the same frame all the time. The receiver of the information may use the counter parameter to dete...";
CM_ SG_ 2565991422 MtGt3IvtLtsAtvMPwMx "Motor/Generator 3 Inverter Limits Active Mechanical Power Maximum: The inverter keeps the mechanical motor power below this value.   This limit may be set in response to a Limits Request or determined by the inverter based on operating conditions.Ref...";
CM_ SG_ 2565991422 MtGt3IvtLtsAtvMPwM "Motor/Generator 3 Inverter Limits Active Mechanical Power Minimum: The inverter keeps the mechanical motor power above this value.   This limit may be set in response to a Limits Request or determined by the inverter based on operating conditions.Ref...";
CM_ SG_ 2565991422 MtrGnrtr3InvrtrLmtsAtvPwrCr "Motor/Generator 3 Inverter Limits Active Power CRC: The CRC is defined as follows: - Length: 8 bits- Polynomial: x^8+x^5+x^3+x^2+x+1- Initial Value: FFh- Input Data Reflection: Not reflected- Result Data Reflection: Not reflected- XOR value: FFh SAE ...";
CM_ SG_ 2565991422 MtGt3IvtLtsAtvDSdPwMx "Motor/Generator 3 Inverter Limits Active DC Side Power Maximum: The inverter keeps the DC Side power below this value.   This limit may be set in response to a Limits Request or determined by the inverter based on operating conditions.Refer to SPN 11...";
CM_ SG_ 2565991422 MtGt3IvtLtsAtvDSdPwM "Motor/Generator 3 Inverter Limits Active DC Side Power Minimum: The inverter keeps the DC side power above this value.   This limit may be set in response to a Limits Request or determined by the inverter based on operating conditions.Refer to SPN 11...";
CM_ BO_ 2565991678 "Motor/Generator 3 Inverter Limits Active Mechanical";
CM_ SG_ 2565991678 MtrGnrtr3InvrtrLmtsAtvMhnlCntr "Motor/Generator 3 Inverter Limits Active Mechanical Counter: The message counter is used to detect situations where the transmitting ECU malfunction repeats the same frame all the time. The receiver of the information may use the counter parameter to...";
CM_ SG_ 2565991678 MtrGnrtr3InvrtrLmtsAtvTrqMxmm "Motor/Generator 3 Inverter Limits Active Torque Maximum: The inverter keeps the motor torque below this value.  This limit may be set in response to a Limits Request or determined by the inverter based on operating conditions.Refer to SPN 11821 [Refe...";
CM_ SG_ 2565991678 MtrGnrtr3InvrtrLmtsAtvTrqMnmm "Motor/Generator 3 Inverter Limits Active Torque Minimum: The inverter keeps the motor torque above this value.  This limit may be set in response to a Limits Request or determined by the inverter based on operating conditions.Refer to SPN 11821 [Refe...";
CM_ SG_ 2565991678 MtrGnrtr3InvrtrLmtsAtvSpdMxmm "Motor/Generator 3 Inverter Limits Active Speed Maximum: The inverter keeps the motor speed below this value.  This limit may be set in response to a Limits Request or determined by the inverter based on operating conditions.Refer to SPN 11822 [Refere...";
CM_ SG_ 2565991678 MtrGnrtr3InvrtrLmtsAtvSpdMnmm "Motor/Generator 3 Inverter Limits Active Speed Minimum: The inverter keeps the motor Speed above this value.  This limit may be set in response to a Limits Request or determined by the inverter based on operating conditions.Refer to SPN 11822 [Refere...";
CM_ SG_ 2565991678 MtrGnrtr3InvrtrLmtsAtvMhnlCr "Motor/Generator 3 Inverter Limits Active Mechanical CRC: The CRC is defined as follows: - Length: 8 bits- Polynomial: x^8+x^5+x^3+x^2+x+1- Initial Value: FFh- Input Data Reflection: Not reflected- Result Data Reflection: Not reflected- XOR value: FFh...";
CM_ BO_ 2565991934 "Motor/Generator 3 Inverter Limits Active DC Side";
CM_ SG_ 2565991934 MtrGnrtr3InvrtrLmtsAtvDSdCr "Motor/Generator 3 Inverter Limits Active DC Side CRC: The CRC is defined as follows: - Length: 8 bits- Polynomial: x^8+x^5+x^3+x^2+x+1- Initial Value: FFh- Input Data Reflection: Not reflected- Result Data Reflection: Not reflected- XOR value: FFh SA...";
CM_ SG_ 2565991934 MtrGnrtr3InvrtrLmtsAtvDSdCntr "Motor/Generator 3 Inverter Limits Active DC Side Counter: The message counter is used to detect situations where the transmitting ECU malfunction repeats the same frame all the time. The receiver of the information may use the counter parameter to de...";
CM_ SG_ 2565991934 MtGt3IvtLtsAtvDSdVtMx "Motor/Generator 3 Inverter Limits Active DC Side Voltage Maximum: The inverter keeps the DC side voltage below this value.  This limit may be set in response to a Limits Request or determined by the inverter based on operating conditions.Refer to SPN...";
CM_ SG_ 2565991934 MtGt3IvtLtsAtvDSdVtM "Motor/Generator 3 Inverter Limits Active DC Side Voltage Minimum: The inverter keeps the DC side voltage above this value.  This limit may be set in response to a Limits Request or determined by the inverter based on operating conditions.Refer to SPN...";
CM_ SG_ 2565991934 MtGt3IvtLtsAtvDSdCtMx "Motor/Generator 3 Inverter Limits Active DC Side Current Maximum: The inverter keeps the DC side current below this value.  This limit may be set in response to a Limits Request or determined by the inverter based on operating conditions. Refer to SP...";
CM_ SG_ 2565991934 MtGt3IvtLtsAtvDSdCtM "Motor/Generator 3 Inverter Limits Active DC Side Current Minimum: The inverter keeps the DC side current above this value.  This limit may be set in response to a Limits Request or determined by the inverter based on operating conditions.Refer to SPN...";
CM_ BO_ 2565992190 "Motor/Generator 3 Inverter Low Voltage";
CM_ SG_ 2565992190 MtrGnrtr3InvrtrSwthdIgntnVltg "Motor/Generator 3 Inverter Switched Ignition Voltage: Switched Ignition voltage supplied to this instance of the inverter controller.";
CM_ SG_ 2565992190 MtrGnrtr3InvrtrUnswthdSlVltg "Motor/Generator 3 Inverter Unswitched SLI Voltage: Continuously supplied SLI power to this instance of the inverter controller.";
CM_ BO_ 2565992446 "Motor/Generator 3 Inverter Status 2";
CM_ SG_ 2565992446 MtrGnrtr3InvrtrStts2Cntr "Motor/Generator 3 Inverter Status 2 Counter: The message counter is used to detect situations where the transmitting ECU malfunction repeats the same frame all the time. The receiver of the information may use the counter parameter to detect this sit...";
CM_ SG_ 2565992446 MtrGnrtr3AvllMxmmTrq "Motor/Generator 3 Available Maximum Torque: This is an estimate of the maximum available motor torque including active deratings at the present motor speed.  This refers to the motor rotor output and excludes any gearbox that may be attached to the m...";
CM_ SG_ 2565992446 MtrGnrtr3AvllMnmmTrq "Motor/Generator 3 Available Minimum Torque: This is an estimate of the minimum available motor torque including active deratings at the present motor speed.  This refers to the motor rotor output and excludes any gearbox that may be attached to the m...";
CM_ SG_ 2565992446 MtrGnrtr3InvrtrStts2Cr "Motor/Generator 3 Inverter Status 2 CRC: The CRC is defined as follows: - Length: 8 bits- Polynomial: x^8+x^5+x^3+x^2+x+1- Initial Value: FFh- Input Data Reflection: Not reflected- Result Data Reflection: Not reflected- XOR value: FFh SAE makes no cl...";
CM_ BO_ 2565992702 "Motor/Generator 3 Inverter Rate Limits Active 1";
CM_ SG_ 2565992702 MtrGnrtr3InvrtrRtLmtsAtv1Cntr "Motor/Generator 3 Inverter Rate Limits Active 1 Counter: The message counter is used to detect situations where the transmitting ECU malfunction repeats the same frame all the time. The receiver of the information may use the counter parameter to det...";
CM_ SG_ 2565992702 MtGt3IvtRtLtsAtvAstSpdRtLt "Motor/Generator 3 Inverter Rate Limits Active Absolute Speed Rate Limit: The active maximum rate of change for the absolute motor speed  (i.e. |d(speed)|/dt) in all control modes of this motor/generator inverter instance. Refer to SPN 11822 [Referenc...";
CM_ SG_ 2565992702 MtGt3IvtRtLtsAtvAstTqRtLt "Motor/Generator 3 Inverter Rate Limits Active Absolute Torque Rate Limit: The active maximum rate of change for the absolute motor torque (i.e. |d(torque)|/dt) in all control modes of this motor/generator inverter instance. Refer to SPN 11821 [Refere...";
CM_ SG_ 2565992702 MtrGnrtr3InvrtrRtLmtsAtv1Cr "Motor/Generator 3 Inverter Rate Limits Active 1 CRC: The CRC is defined as follows: - Length: 8 bits- Polynomial: x^8+x^5+x^3+x^2+x+1- Initial Value: FFh- Input Data Reflection: Not reflected- Result Data Reflection: Not reflected- XOR value: FFh SAE...";
CM_ BO_ 2364666366 "Motor/Generator 4 Inverter Mode Feedback 1";
CM_ SG_ 2364666366 MtrGnrtr4InvrtrMdFdk1Cntr "Motor/Generator 4 Inverter Mode Feedback 1 Counter: The message counter is used to detect situations where the transmitting ECU malfunction repeats the same frame all the time. The receiver of the information may use the counter parameter to detect t...";
CM_ SG_ 2364666366 MtrGnrtr4InvrtrCntrlLmtsOvrrdMd "Motor/Generator 4 Inverter Control Limits Override Mode: During normal operation this will have the same value as SPN 11928 [Control Limits Request Override Mode].  0 = Operating limits are not overridden.  If a limit was previously active, then it h...";
CM_ SG_ 2364666366 MtrGnrtr4InvrtrCntrlStpntMd "Motor/Generator 4 Inverter Control Setpoint Mode: Reports the inverter mode (See SPN 11931 [Control Setpoint Mode Request] for requested mode).Passive modes:  0 = Powered On - the inverter is commanded to be powered on and able to communicate, but th...";
CM_ SG_ 2364666366 MtrGnrtr4InvrtrMdFdk1Cr "Motor/Generator 4 Inverter Mode Feedback 1 CRC: The CRC is defined as follows: - Length: 8 bits- Polynomial: x^8+x^5+x^3+x^2+x+1- Initial Value: FFh- Input Data Reflection: Not reflected- Result Data Reflection: Not reflected- XOR value: FFh SAE make...";
CM_ SG_ 2364666366 MtrGnrtr4InvrtrHvlStts "Motor/Generator 4 Inverter HVIL Status: Reports the High Voltage Interlock Loop (HVIL) state.00b = HVIL Closed01b = HVIL Open10b = Error11b = Not Available";
CM_ BO_ 2565993214 "Motor/Generator 4 Inverter Limits Active Power";
CM_ SG_ 2565993214 MtrGnrtr4InvrtrLmtsAtvPwrCntr "Motor/Generator 4 Inverter Limits Active Power Counter: The message counter is used to detect situations where the transmitting ECU malfunction repeats the same frame all the time. The receiver of the information may use the counter parameter to dete...";
CM_ SG_ 2565993214 MtGt4IvtLtsAtvMPwMx "Motor/Generator 4 Inverter Limits Active Mechanical Power Maximum: The inverter keeps the mechanical motor power below this value.   This limit may be set in response to a Limits Request or determined by the inverter based on operating conditions.Ref...";
CM_ SG_ 2565993214 MtGt4IvtLtsAtvMPwM "Motor/Generator 4 Inverter Limits Active Mechanical Power Minimum: The inverter keeps the mechanical motor power above this value.   This limit may be set in response to a Limits Request or determined by the inverter based on operating conditions.Ref...";
CM_ SG_ 2565993214 MtrGnrtr4InvrtrLmtsAtvPwrCr "Motor/Generator 4 Inverter Limits Active Power CRC: The CRC is defined as follows: - Length: 8 bits- Polynomial: x^8+x^5+x^3+x^2+x+1- Initial Value: FFh- Input Data Reflection: Not reflected- Result Data Reflection: Not reflected- XOR value: FFh SAE ...";
CM_ SG_ 2565993214 MtGt4IvtLtsAtvDSdPwMx "Motor/Generator 4 Inverter Limits Active DC Side Power Maximum: The inverter keeps the DC Side power below this value.   This limit may be set in response to a Limits Request or determined by the inverter based on operating conditions.Refer to SPN 11...";
CM_ SG_ 2565993214 MtGt4IvtLtsAtvDSdPwM "Motor/Generator 4 Inverter Limits Active DC Side Power Minimum: The inverter keeps the DC side power above this value.   This limit may be set in response to a Limits Request or determined by the inverter based on operating conditions.Refer to SPN 11...";
CM_ BO_ 2565993470 "Motor/Generator 4 Inverter Limits Active Mechanical";
CM_ SG_ 2565993470 MtrGnrtr4InvrtrLmtsAtvMhnlCntr "Motor/Generator 4 Inverter Limits Active Mechanical Counter: The message counter is used to detect situations where the transmitting ECU malfunction repeats the same frame all the time. The receiver of the information may use the counter parameter to...";
CM_ SG_ 2565993470 MtrGnrtr4InvrtrLmtsAtvTrqMxmm "Motor/Generator 4 Inverter Limits Active Torque Maximum: The inverter keeps the motor torque below this value.  This limit may be set in response to a Limits Request or determined by the inverter based on operating conditions.Refer to SPN 11939 [Refe...";
CM_ SG_ 2565993470 MtrGnrtr4InvrtrLmtsAtvTrqMnmm "Motor/Generator 4 Inverter Limits Active Torque Minimum: The inverter keeps the motor torque above this value.  This limit may be set in response to a Limits Request or determined by the inverter based on operating conditions.Refer to SPN 11939 [Refe...";
CM_ SG_ 2565993470 MtrGnrtr4InvrtrLmtsAtvSpdMxmm "Motor/Generator 4 Inverter Limits Active Speed Maximum: The inverter keeps the motor speed below this value.  This limit may be set in response to a Limits Request or determined by the inverter based on operating conditions.Refer to SPN 11940 [Refere...";
CM_ SG_ 2565993470 MtrGnrtr4InvrtrLmtsAtvSpdMnmm "Motor/Generator 4 Inverter Limits Active Speed Minimum: The inverter keeps the motor Speed above this value.  This limit may be set in response to a Limits Request or determined by the inverter based on operating conditions.Refer to SPN 11940 [Refere...";
CM_ SG_ 2565993470 MtrGnrtr4InvrtrLmtsAtvMhnlCr "Motor/Generator 4 Inverter Limits Active Mechanical CRC: The CRC is defined as follows: - Length: 8 bits- Polynomial: x^8+x^5+x^3+x^2+x+1- Initial Value: FFh- Input Data Reflection: Not reflected- Result Data Reflection: Not reflected- XOR value: FFh...";
CM_ BO_ 2565993726 "Motor/Generator 4 Inverter Limits Active DC Side";
CM_ SG_ 2565993726 MtrGnrtr4InvrtrLmtsAtvDSdCr "Motor/Generator 4 Inverter Limits Active DC Side CRC: The CRC is defined as follows: - Length: 8 bits- Polynomial: x^8+x^5+x^3+x^2+x+1- Initial Value: FFh- Input Data Reflection: Not reflected- Result Data Reflection: Not reflected- XOR value: FFh SA...";
CM_ SG_ 2565993726 MtrGnrtr4InvrtrLmtsAtvDSdCntr "Motor/Generator 4 Inverter Limits Active DC Side Counter: The message counter is used to detect situations where the transmitting ECU malfunction repeats the same frame all the time. The receiver of the information may use the counter parameter to de...";
CM_ SG_ 2565993726 MtGt4IvtLtsAtvDSdVtMx "Motor/Generator 4 Inverter Limits Active DC Side Voltage Maximum: The inverter keeps the DC side voltage below this value.  This limit may be set in response to a Limits Request or determined by the inverter based on operating conditions.Refer to SPN...";
CM_ SG_ 2565993726 MtGt4IvtLtsAtvDSdVtM "Motor/Generator 4 Inverter Limits Active DC Side Voltage Minimum: The inverter keeps the DC side voltage above this value.  This limit may be set in response to a Limits Request or determined by the inverter based on operating conditions.Refer to SPN...";
CM_ SG_ 2565993726 MtGt4IvtLtsAtvDSdCtMx "Motor/Generator 4 Inverter Limits Active DC Side Current Maximum: The inverter keeps the DC side current below this value.  This limit may be set in response to a Limits Request or determined by the inverter based on operating conditions. Refer to SP...";
CM_ SG_ 2565993726 MtGt4IvtLtsAtvDSdCtM "Motor/Generator 4 Inverter Limits Active DC Side Current Minimum: The inverter keeps the DC side current above this value.  This limit may be set in response to a Limits Request or determined by the inverter based on operating conditions.Refer to SPN...";
CM_ BO_ 2565993982 "Motor/Generator 4 Inverter Low Voltage";
CM_ SG_ 2565993982 MtrGnrtr4InvrtrSwthdIgntnVltg "Motor/Generator 4 Inverter Switched Ignition Voltage: Switched Ignition voltage supplied to this instance of the inverter controller.";
CM_ SG_ 2565993982 MtrGnrtr4InvrtrUnswthdSlVltg "Motor/Generator 4 Inverter Unswitched SLI Voltage: Continuously supplied SLI power to this instance of the inverter controller.";
CM_ BO_ 2565994238 "Motor/Generator 4 Inverter Status 2";
CM_ SG_ 2565994238 MtrGnrtr4InvrtrStts2Cntr "Motor/Generator 4 Inverter Status 2 Counter: The message counter is used to detect situations where the transmitting ECU malfunction repeats the same frame all the time. The receiver of the information may use the counter parameter to detect this sit...";
CM_ SG_ 2565994238 MtrGnrtr4AvllMxmmTrq "Motor/Generator 4 Available Maximum Torque: This is an estimate of the maximum available motor torque including active deratings at the present motor speed.  This refers to the motor rotor output and excludes any gearbox that may be attached to the m...";
CM_ SG_ 2565994238 MtrGnrtr4AvllMnmmTrq "Motor/Generator 4 Available Minimum Torque: This is an estimate of the minimum available motor torque including active deratings at the present motor speed.  This refers to the motor rotor output and excludes any gearbox that may be attached to the m...";
CM_ SG_ 2565994238 MtrGnrtr4InvrtrStts2Cr "Motor/Generator 4 Inverter Status 2 CRC: The CRC is defined as follows: - Length: 8 bits- Polynomial: x^8+x^5+x^3+x^2+x+1- Initial Value: FFh- Input Data Reflection: Not reflected- Result Data Reflection: Not reflected- XOR value: FFh SAE makes no cl...";
CM_ BO_ 2565994494 "Motor/Generator 4 Inverter Rate Limits Active 1";
CM_ SG_ 2565994494 MtrGnrtr4InvrtrRtLmtsAtv1Cntr "Motor/Generator 4 Inverter Rate Limits Active 1 Counter: The message counter is used to detect situations where the transmitting ECU malfunction repeats the same frame all the time. The receiver of the information may use the counter parameter to det...";
CM_ SG_ 2565994494 MtGt4IvtRtLtsAtvAstSpdRtLt "Motor/Generator 4 Inverter Rate Limits Active Absolute Speed Rate Limit: The active maximum rate of change for the absolute motor speed  (i.e. |d(speed)|/dt) in all control modes of this motor/generator inverter instance. Refer to SPN 11940 [Referenc...";
CM_ SG_ 2565994494 MtGt4IvtRtLtsAtvAstTqRtLt "Motor/Generator 4 Inverter Rate Limits Active Absolute Torque Rate Limit: The active maximum rate of change for the absolute motor torque (i.e. |d(torque)|/dt) in all control modes of this motor/generator inverter instance. Refer to SPN 11939 [Refere...";
CM_ SG_ 2565994494 MtrGnrtr4InvrtrRtLmtsAtv1Cr "Motor/Generator 4 Inverter Rate Limits Active 1 CRC: The CRC is defined as follows: - Length: 8 bits- Polynomial: x^8+x^5+x^3+x^2+x+1- Initial Value: FFh- Input Data Reflection: Not reflected- Result Data Reflection: Not reflected- XOR value: FFh SAE...";
CM_ BO_ 2364668158 "Motor/Generator 5 Inverter Mode Feedback 1";
CM_ SG_ 2364668158 MtrGnrtr5InvrtrMdFdk1Cntr "Motor/Generator 5 Inverter Mode Feedback 1 Counter: The message counter is used to detect situations where the transmitting ECU malfunction repeats the same frame all the time. The receiver of the information may use the counter parameter to detect t...";
CM_ SG_ 2364668158 MtrGnrtr5InvrtrCntrlLmtsOvrrdMd "Motor/Generator 5 Inverter Control Limits Override Mode: During normal operation this will have the same value as SPN 12046 [Control Limits Request Override Mode].  0 = Operating limits are not overridden.  If a limit was previously active, then it h...";
CM_ SG_ 2364668158 MtrGnrtr5InvrtrCntrlStpntMd "Motor/Generator 5 Inverter Control Setpoint Mode: Reports the inverter mode (See SPN 12049 [Control Setpoint Mode Request] for requested mode).Passive modes:  0 = Powered On - the inverter is commanded to be powered on and able to communicate, but th...";
CM_ SG_ 2364668158 MtrGnrtr5InvrtrMdFdk1Cr "Motor/Generator 5 Inverter Mode Feedback 1 CRC: The CRC is defined as follows: - Length: 8 bits- Polynomial: x^8+x^5+x^3+x^2+x+1- Initial Value: FFh- Input Data Reflection: Not reflected- Result Data Reflection: Not reflected- XOR value: FFh SAE make...";
CM_ SG_ 2364668158 MtrGnrtr5InvrtrHvlStts "Motor/Generator 5 Inverter HVIL Status: Reports the High Voltage Interlock Loop (HVIL) state.00b = HVIL Closed01b = HVIL Open10b = Error11b = Not Available";
BA_DEF_ SG_  "SPN" INT 0 524287;
BA_DEF_ BO_  "VFrameFormat" ENUM  "StandardCAN","ExtendedCAN","reserved","J1939PG";
BA_DEF_DEF_  "SPN" 0;
BA_DEF_DEF_  "VFrameFormat" "J1939PG";
BA_ "SPN" SG_ 2364652542 Hvsp3HghstCllSttOfChrgMdlNmr 11356;
BA_ "SPN" SG_ 2364652542 Hvsp3HghstCllSttOfChrgCllNmr 11357;
BA_ "SPN" SG_ 2364652542 Hvsp3LwstCllSttOfChrgMdlNmr 11358;
BA_ "SPN" SG_ 2364652542 Hvsp3LwstCllSttOfChrgCllNmr 11359;
BA_ "SPN" SG_ 2364652542 Hvsp3HghVltgBsAtvIsltnTstRslts 11360;
BA_ "SPN" SG_ 2364652542 Hvsp3HghVltgBsPssvIsltnTstRslts 11361;
BA_ "SPN" SG_ 2364652798 Hvesp3ActualChargeRate 13067;
BA_ "SPN" SG_ 2364652798 Hvsp3BsVltgNgtvTChsssGrndVltg 11362;
BA_ "SPN" SG_ 2364652798 Hvsp3VltgLvlNgtvTChsssGrndVltg 11363;
BA_ "SPN" SG_ 2364653054 Hvsp4DshrgPwrLmtDTSttOfChrg 11386;
BA_ "SPN" SG_ 2364653054 Hvsp4DshrgPwrLmtDTBttrTmprtr 11387;
BA_ "SPN" SG_ 2364653054 Hvsp4DsPwLtDTBttDstCdt 11388;
BA_ "SPN" SG_ 2364653054 Hvsp4DshrgPwrLmtDTBttrOrCllVltg 11389;
BA_ "SPN" SG_ 2364653054 Hvsp4DshrgPwrLmtDTBttrCrrnt 11390;
BA_ "SPN" SG_ 2364653054 Hvsp4DshrgPwrLmtDTAnUndfndCs 11391;
BA_ "SPN" SG_ 2364653054 Hvsp4ChrgPwrLmtDTSttOfChrg 11392;
BA_ "SPN" SG_ 2364653054 Hvsp4ChrgPwrLmtDTBttrTmprtr 11393;
BA_ "SPN" SG_ 2364653054 Hvsp4ChrgPwrLmtDTBttrDgnstCndtn 11394;
BA_ "SPN" SG_ 2364653054 Hvsp4ChrgPwrLmtDTBttrOrCllVltg 11395;
BA_ "SPN" SG_ 2364653054 Hvsp4ChrgPwrLmtDTBttrCrrnt 11396;
BA_ "SPN" SG_ 2364653054 Hvsp4ChrgPwrLmtDTAnUndfndCs 11397;
BA_ "SPN" SG_ 2364653310 Hvesp4AvailableDischargePower 11398;
BA_ "SPN" SG_ 2364653310 Hvesp4AvailableChargePower 11399;
BA_ "SPN" SG_ 2364653310 Hvesp4VoltageLevel 11400;
BA_ "SPN" SG_ 2364653310 Hvesp4Current 11401;
BA_ "SPN" SG_ 2364653566 Hvesp4FastUpdateStateOfCharge 11402;
BA_ "SPN" SG_ 2364653566 Hvesp4HighestCellVoltage 11403;
BA_ "SPN" SG_ 2364653566 Hvesp4LowestCellVoltage 11404;
BA_ "SPN" SG_ 2364653566 Hvsp4CllVltgDffrntlStts 11405;
BA_ "SPN" SG_ 2364653822 Hvesp4HighestCellTemperature 11406;
BA_ "SPN" SG_ 2364653822 Hvesp4LowestCellTemperature 11407;
BA_ "SPN" SG_ 2364653822 Hvesp4AverageCellTemperature 11408;
BA_ "SPN" SG_ 2364653822 Hvsp4CllTmprtrDffrntlStts 11409;
BA_ "SPN" SG_ 2364654078 Hvesp4DischargeCapacity 11410;
BA_ "SPN" SG_ 2364654078 Hvesp4ChargeCapacity 11411;
BA_ "SPN" SG_ 2364654078 Hvesp4CellBalancingCount 11412;
BA_ "SPN" SG_ 2364654334 Hvesp4LowestCellStateOfCharge 11415;
BA_ "SPN" SG_ 2364654334 Hvesp4HighestCellStateOfCharge 11416;
BA_ "SPN" SG_ 2364654334 Hvsp4MxmmInstntnsDshrgCrrntLmt 11413;
BA_ "SPN" SG_ 2364654334 Hvsp4MxmmInstntnsChrgCrrntLmt 11414;
BA_ "SPN" SG_ 2364654590 Hvesp4BusVoltage 11417;
BA_ "SPN" SG_ 2364654590 Hvesp4IgnitionVoltage 11418;
BA_ "SPN" SG_ 2364654590 Hvesp4IntakeCoolantTemperature 11419;
BA_ "SPN" SG_ 2364654590 Hvesp4OutletCoolantTemperature 11420;
BA_ "SPN" SG_ 2364654590 Hvesp4ElectronicsTemperature 11421;
BA_ "SPN" SG_ 2364654590 Hvesp4Temperature 11422;
BA_ "SPN" SG_ 2364654846 Hvesp4HvilStatus 11430;
BA_ "SPN" SG_ 2364654846 Hvesp4InertiaSwitchStatus 11431;
BA_ "SPN" SG_ 2364654846 Hvesp4StateOfChargeStatus 11432;
BA_ "SPN" SG_ 2364654846 Hvesp4CellBalanceStatus 11433;
BA_ "SPN" SG_ 2364654846 Hvesp4CellBalancingActive 11434;
BA_ "SPN" SG_ 2364654846 Hvesp4InternalChargerStatus 11435;
BA_ "SPN" SG_ 2364654846 Hvesp4OperationalStatus 11437;
BA_ "SPN" SG_ 2364654846 Hvesp4Status1Counter 13021;
BA_ "SPN" SG_ 2364654846 Hvesp4Status1Crc 13022;
BA_ "SPN" SG_ 2364654846 Hvsp4HghVltgBsPstvCnttrStt 11423;
BA_ "SPN" SG_ 2364654846 Hvsp4HghVltgBsNgtvCnttrStt 11424;
BA_ "SPN" SG_ 2364654846 Hvsp4HghVltgBsDsnntFrwrnng 11425;
BA_ "SPN" SG_ 2364654846 Hvsp4HghVltgBsPrChrgRlStt 11426;
BA_ "SPN" SG_ 2364654846 Hvsp4CntrOfPkCnttrStt 11427;
BA_ "SPN" SG_ 2364654846 Hvsp4HghVltgBsAtvIsltnTstStts 11428;
BA_ "SPN" SG_ 2364654846 Hvsp4HghVltgBsPssvIsltnTstStts 11429;
BA_ "SPN" SG_ 2364654846 Hvsp4HghVltgBsCnntnStts 11436;
BA_ "SPN" SG_ 2364655102 Hvesp4DischargeEnergyCapacity 11438;
BA_ "SPN" SG_ 2364655102 Hvesp4ChargeEnergyCapacity 11439;
BA_ "SPN" SG_ 2364655102 Hvesp4MaximumChargeVoltageLimit 11440;
BA_ "SPN" SG_ 2364655358 Hvesp4Module1OperationalStatus 11441;
BA_ "SPN" SG_ 2364655358 Hvesp4Module2OperationalStatus 11442;
BA_ "SPN" SG_ 2364655358 Hvesp4Module3OperationalStatus 11443;
BA_ "SPN" SG_ 2364655358 Hvesp4Module4OperationalStatus 11444;
BA_ "SPN" SG_ 2364655358 Hvesp4Module5OperationalStatus 11445;
BA_ "SPN" SG_ 2364655358 Hvesp4Module6OperationalStatus 11446;
BA_ "SPN" SG_ 2364655358 Hvesp4Module7OperationalStatus 11447;
BA_ "SPN" SG_ 2364655358 Hvesp4Module8OperationalStatus 11448;
BA_ "SPN" SG_ 2364655358 Hvesp4Module9OperationalStatus 11449;
BA_ "SPN" SG_ 2364655358 Hvesp4Module10OperationalStatus 11450;
BA_ "SPN" SG_ 2364655358 Hvesp4Module11OperationalStatus 11451;
BA_ "SPN" SG_ 2364655358 Hvesp4Module12OperationalStatus 11452;
BA_ "SPN" SG_ 2364655358 Hvesp4Module13OperationalStatus 11453;
BA_ "SPN" SG_ 2364655358 Hvesp4Module14OperationalStatus 11454;
BA_ "SPN" SG_ 2364655358 Hvesp4Module15OperationalStatus 11455;
BA_ "SPN" SG_ 2364655358 Hvesp4Module16OperationalStatus 11456;
BA_ "SPN" SG_ 2364655358 Hvesp4Module17OperationalStatus 14673;
BA_ "SPN" SG_ 2364655358 Hvesp4Module18OperationalStatus 14674;
BA_ "SPN" SG_ 2364655358 Hvesp4Module19OperationalStatus 14675;
BA_ "SPN" SG_ 2364655358 Hvesp4Module20OperationalStatus 14676;
BA_ "SPN" SG_ 2364655358 Hvesp4Module21OperationalStatus 14677;
BA_ "SPN" SG_ 2364655358 Hvesp4Module22OperationalStatus 14678;
BA_ "SPN" SG_ 2364655358 Hvesp4Module23OperationalStatus 14679;
BA_ "SPN" SG_ 2364655358 Hvesp4Module24OperationalStatus 14680;
BA_ "SPN" SG_ 2364655358 Hvesp4Module25OperationalStatus 14681;
BA_ "SPN" SG_ 2364655358 Hvesp4Module26OperationalStatus 14682;
BA_ "SPN" SG_ 2364655358 Hvesp4Module27OperationalStatus 14683;
BA_ "SPN" SG_ 2364655358 Hvesp4Module28OperationalStatus 14684;
BA_ "SPN" SG_ 2364655358 Hvesp4Module29OperationalStatus 14685;
BA_ "SPN" SG_ 2364655358 Hvesp4Module30OperationalStatus 14686;
BA_ "SPN" SG_ 2364655358 Hvesp4Module31OperationalStatus 14687;
BA_ "SPN" SG_ 2364655358 Hvesp4Module32OperationalStatus 14688;
BA_ "SPN" SG_ 2364655614 Hvsp4ThrmlMngmntSstmSlInptPwr 11457;
BA_ "SPN" SG_ 2364655614 Hvsp4TMtSstHVtIptPw 11458;
BA_ "SPN" SG_ 2364655614 Hvsp4ThrmlMngmntSstmCmprssrSpd 11459;
BA_ "SPN" SG_ 2364655614 Hvsp4ThrmlMngmntSstmRltvHmdt 11460;
BA_ "SPN" SG_ 2364655614 Hvsp4ThrmlMngmntSstmHtrStts 11461;
BA_ "SPN" SG_ 2364655614 Hvsp4ThrmlMngmntSstmHvlStts 12816;
BA_ "SPN" SG_ 2364655614 Hvsp4ThrmlMngmntSstmMd 11462;
BA_ "SPN" SG_ 2364655614 Hvsp4ThrmlMngmntSstmClntLvl 12901;
BA_ "SPN" SG_ 2364655870 Hvesp4AverageCellVoltage 11467;
BA_ "SPN" SG_ 2364655870 Hvsp4HghstCllVltgMdlNmr 11463;
BA_ "SPN" SG_ 2364655870 Hvsp4HghstCllVltgCllNmr 11464;
BA_ "SPN" SG_ 2364655870 Hvsp4LwstCllVltgMdlNmr 11465;
BA_ "SPN" SG_ 2364655870 Hvsp4LwstCllVltgCllNmr 11466;
BA_ "SPN" SG_ 2364656126 Hvsp4HghstCllTmprtrMdlNmr 11468;
BA_ "SPN" SG_ 2364656126 Hvsp4HghstCllTmprtrCllNmr 11469;
BA_ "SPN" SG_ 2364656126 Hvsp4LwstCllTmprtrMdlNmr 11470;
BA_ "SPN" SG_ 2364656126 Hvsp4LwstCllTmprtrCllNmr 11471;
BA_ "SPN" SG_ 2364656126 Hvess4ThermalEventDetected 21291;
BA_ "SPN" SG_ 2364656126 Hvsp4Dt9EmdddIntgrtSpprt 22983;
BA_ "SPN" SG_ 2364656126 Hvesp4Data9Counter 22984;
BA_ "SPN" SG_ 2364656126 Hvesp4Data9Crc 22985;
BA_ "SPN" SG_ 2364656382 Hvsp4HghstCllSttOfChrgMdlNmr 11472;
BA_ "SPN" SG_ 2364656382 Hvsp4HghstCllSttOfChrgCllNmr 11473;
BA_ "SPN" SG_ 2364656382 Hvsp4LwstCllSttOfChrgMdlNmr 11474;
BA_ "SPN" SG_ 2364656382 Hvsp4LwstCllSttOfChrgCllNmr 11475;
BA_ "SPN" SG_ 2364656382 Hvsp4HghVltgBsAtvIsltnTstRslts 11476;
BA_ "SPN" SG_ 2364656382 Hvsp4HghVltgBsPssvIsltnTstRslts 11477;
BA_ "SPN" SG_ 2364656638 Hvesp4ActualChargeRate 13068;
BA_ "SPN" SG_ 2364656638 Hvsp4BsVltgNgtvTChsssGrndVltg 11478;
BA_ "SPN" SG_ 2364656638 Hvsp4VltgLvlNgtvTChsssGrndVltg 11479;
BA_ "SPN" SG_ 2364656894 Hvsp5DshrgPwrLmtDTSttOfChrg 11502;
BA_ "SPN" SG_ 2364656894 Hvsp5DshrgPwrLmtDTBttrTmprtr 11503;
BA_ "SPN" SG_ 2364656894 Hvsp5DsPwLtDTBttDstCdt 11504;
BA_ "SPN" SG_ 2364656894 Hvsp5DshrgPwrLmtDTBttrOrCllVltg 11505;
BA_ "SPN" SG_ 2364656894 Hvsp5DshrgPwrLmtDTBttrCrrnt 11506;
BA_ "SPN" SG_ 2364656894 Hvsp5DshrgPwrLmtDTAnUndfndCs 11507;
BA_ "SPN" SG_ 2364656894 Hvsp5ChrgPwrLmtDTSttOfChrg 11508;
BA_ "SPN" SG_ 2364656894 Hvsp5ChrgPwrLmtDTBttrTmprtr 11509;
BA_ "SPN" SG_ 2364656894 Hvsp5ChrgPwrLmtDTBttrDgnstCndtn 11510;
BA_ "SPN" SG_ 2364656894 Hvsp5ChrgPwrLmtDTBttrOrCllVltg 11511;
BA_ "SPN" SG_ 2364656894 Hvsp5ChrgPwrLmtDTBttrCrrnt 11512;
BA_ "SPN" SG_ 2364656894 Hvsp5ChrgPwrLmtDTAnUndfndCs 11513;
BA_ "SPN" SG_ 2364657150 Hvesp5AvailableDischargePower 11514;
BA_ "SPN" SG_ 2364657150 Hvesp5AvailableChargePower 11515;
BA_ "SPN" SG_ 2364657150 Hvesp5VoltageLevel 11516;
BA_ "SPN" SG_ 2364657150 Hvesp5Current 11517;
BA_ "SPN" SG_ 2364657406 Hvesp5FastUpdateStateOfCharge 11518;
BA_ "SPN" SG_ 2364657406 Hvesp5HighestCellVoltage 11519;
BA_ "SPN" SG_ 2364657406 Hvesp5LowestCellVoltage 11520;
BA_ "SPN" SG_ 2364657406 Hvsp5CllVltgDffrntlStts 11521;
BA_ "SPN" SG_ 2364657662 Hvesp5HighestCellTemperature 11522;
BA_ "SPN" SG_ 2364657662 Hvesp5LowestCellTemperature 11523;
BA_ "SPN" SG_ 2364657662 Hvesp5AverageCellTemperature 11524;
BA_ "SPN" SG_ 2364657662 Hvsp5CllTmprtrDffrntlStts 11525;
BA_ "SPN" SG_ 2364657918 Hvesp5DischargeCapacity 11526;
BA_ "SPN" SG_ 2364657918 Hvesp5ChargeCapacity 11527;
BA_ "SPN" SG_ 2364657918 Hvesp5CellBalancingCount 11528;
BA_ "SPN" SG_ 2364658174 Hvesp5LowestCellStateOfCharge 11531;
BA_ "SPN" SG_ 2364658174 Hvesp5HighestCellStateOfCharge 11532;
BA_ "SPN" SG_ 2364658174 Hvsp5MxmmInstntnsDshrgCrrntLmt 11529;
BA_ "SPN" SG_ 2364658174 Hvsp5MxmmInstntnsChrgCrrntLmt 11530;
BA_ "SPN" SG_ 2364658430 Hvesp5BusVoltage 11533;
BA_ "SPN" SG_ 2364658430 Hvesp5IgnitionVoltage 11534;
BA_ "SPN" SG_ 2364658430 Hvesp5IntakeCoolantTemperature 11535;
BA_ "SPN" SG_ 2364658430 Hvesp5OutletCoolantTemperature 11536;
BA_ "SPN" SG_ 2364658430 Hvesp5ElectronicsTemperature 11537;
BA_ "SPN" SG_ 2364658430 Hvesp5Temperature 11538;
BA_ "SPN" SG_ 2364658686 Hvesp5HvilStatus 11546;
BA_ "SPN" SG_ 2364658686 Hvesp5InertiaSwitchStatus 11547;
BA_ "SPN" SG_ 2364658686 Hvesp5StateOfChargeStatus 11548;
BA_ "SPN" SG_ 2364658686 Hvesp5CellBalanceStatus 11549;
BA_ "SPN" SG_ 2364658686 Hvesp5CellBalancingActive 11550;
BA_ "SPN" SG_ 2364658686 Hvesp5InternalChargerStatus 11551;
BA_ "SPN" SG_ 2364658686 Hvesp5OperationalStatus 11553;
BA_ "SPN" SG_ 2364658686 Hvesp5Status1Counter 13023;
BA_ "SPN" SG_ 2364658686 Hvesp5Status1Crc 13024;
BA_ "SPN" SG_ 2364658686 Hvsp5HghVltgBsPstvCnttrStt 11539;
BA_ "SPN" SG_ 2364658686 Hvsp5HghVltgBsNgtvCnttrStt 11540;
BA_ "SPN" SG_ 2364658686 Hvsp5HghVltgBsDsnntFrwrnng 11541;
BA_ "SPN" SG_ 2364658686 Hvsp5HghVltgBsPrChrgRlStt 11542;
BA_ "SPN" SG_ 2364658686 Hvsp5CntrOfPkCnttrStt 11543;
BA_ "SPN" SG_ 2364658686 Hvsp5HghVltgBsAtvIsltnTstStts 11544;
BA_ "SPN" SG_ 2364658686 Hvsp5HghVltgBsPssvIsltnTstStts 11545;
BA_ "SPN" SG_ 2364658686 Hvsp5HghVltgBsCnntnStts 11552;
BA_ "SPN" SG_ 2364658942 Hvesp5DischargeEnergyCapacity 11554;
BA_ "SPN" SG_ 2364658942 Hvesp5ChargeEnergyCapacity 11555;
BA_ "SPN" SG_ 2364658942 Hvesp5MaximumChargeVoltageLimit 11556;
BA_ "SPN" SG_ 2364659198 Hvesp5Module1OperationalStatus 11557;
BA_ "SPN" SG_ 2364659198 Hvesp5Module2OperationalStatus 11558;
BA_ "SPN" SG_ 2364659198 Hvesp5Module3OperationalStatus 11559;
BA_ "SPN" SG_ 2364659198 Hvesp5Module4OperationalStatus 11560;
BA_ "SPN" SG_ 2364659198 Hvesp5Module5OperationalStatus 11561;
BA_ "SPN" SG_ 2364659198 Hvesp5Module6OperationalStatus 11562;
BA_ "SPN" SG_ 2364659198 Hvesp5Module7OperationalStatus 11563;
BA_ "SPN" SG_ 2364659198 Hvesp5Module8OperationalStatus 11564;
BA_ "SPN" SG_ 2364659198 Hvesp5Module9OperationalStatus 11565;
BA_ "SPN" SG_ 2364659198 Hvesp5Module10OperationalStatus 11566;
BA_ "SPN" SG_ 2364659198 Hvesp5Module11OperationalStatus 11567;
BA_ "SPN" SG_ 2364659198 Hvesp5Module12OperationalStatus 11568;
BA_ "SPN" SG_ 2364659198 Hvesp5Module13OperationalStatus 11569;
BA_ "SPN" SG_ 2364659198 Hvesp5Module14OperationalStatus 11570;
BA_ "SPN" SG_ 2364659198 Hvesp5Module15OperationalStatus 11571;
BA_ "SPN" SG_ 2364659198 Hvesp5Module16OperationalStatus 11572;
BA_ "SPN" SG_ 2364659198 Hvesp5Module17OperationalStatus 14689;
BA_ "SPN" SG_ 2364659198 Hvesp5Module18OperationalStatus 14690;
BA_ "SPN" SG_ 2364659198 Hvesp5Module19OperationalStatus 14691;
BA_ "SPN" SG_ 2364659198 Hvesp5Module20OperationalStatus 14692;
BA_ "SPN" SG_ 2364659198 Hvesp5Module21OperationalStatus 14693;
BA_ "SPN" SG_ 2364659198 Hvesp5Module22OperationalStatus 14694;
BA_ "SPN" SG_ 2364659198 Hvesp5Module23OperationalStatus 14695;
BA_ "SPN" SG_ 2364659198 Hvesp5Module24OperationalStatus 14696;
BA_ "SPN" SG_ 2364659198 Hvesp5Module25OperationalStatus 14697;
BA_ "SPN" SG_ 2364659198 Hvesp5Module26OperationalStatus 14698;
BA_ "SPN" SG_ 2364659198 Hvesp5Module27OperationalStatus 14699;
BA_ "SPN" SG_ 2364659198 Hvesp5Module28OperationalStatus 14700;
BA_ "SPN" SG_ 2364659198 Hvesp5Module29OperationalStatus 14701;
BA_ "SPN" SG_ 2364659198 Hvesp5Module30OperationalStatus 14702;
BA_ "SPN" SG_ 2364659198 Hvesp5Module31OperationalStatus 14703;
BA_ "SPN" SG_ 2364659198 Hvesp5Module32OperationalStatus 14704;
BA_ "SPN" SG_ 2364659454 Hvsp5ThrmlMngmntSstmSlInptPwr 11573;
BA_ "SPN" SG_ 2364659454 Hvsp5TMtSstHVtIptPw 11574;
BA_ "SPN" SG_ 2364659454 Hvsp5ThrmlMngmntSstmCmprssrSpd 11575;
BA_ "SPN" SG_ 2364659454 Hvsp5ThrmlMngmntSstmRltvHmdt 11576;
BA_ "SPN" SG_ 2364659454 Hvsp5ThrmlMngmntSstmHtrStts 11577;
BA_ "SPN" SG_ 2364659454 Hvsp5ThrmlMngmntSstmHvlStts 12815;
BA_ "SPN" SG_ 2364659454 Hvsp5ThrmlMngmntSstmMd 11578;
BA_ "SPN" SG_ 2364659454 Hvsp5ThrmlMngmntSstmClntLvl 12902;
BA_ "SPN" SG_ 2364659710 Hvesp5AverageCellVoltage 11583;
BA_ "SPN" SG_ 2364659710 Hvsp5HghstCllVltgMdlNmr 11579;
BA_ "SPN" SG_ 2364659710 Hvsp5HghstCllVltgCllNmr 11580;
BA_ "SPN" SG_ 2364659710 Hvsp5LwstCllVltgMdlNmr 11581;
BA_ "SPN" SG_ 2364659710 Hvsp5LwstCllVltgCllNmr 11582;
BA_ "SPN" SG_ 2364659966 Hvsp5HghstCllTmprtrMdlNmr 11584;
BA_ "SPN" SG_ 2364659966 Hvsp5HghstCllTmprtrCllNmr 11585;
BA_ "SPN" SG_ 2364659966 Hvsp5LwstCllTmprtrMdlNmr 11586;
BA_ "SPN" SG_ 2364659966 Hvsp5LwstCllTmprtrCllNmr 11587;
BA_ "SPN" SG_ 2364659966 Hvess5ThermalEventDetected 21292;
BA_ "SPN" SG_ 2364659966 Hvsp5Dt9EmdddIntgrtSpprt 22986;
BA_ "SPN" SG_ 2364659966 Hvesp5Data9Counter 22987;
BA_ "SPN" SG_ 2364659966 Hvesp5Data9Crc 22988;
BA_ "SPN" SG_ 2364660222 Hvsp5HghstCllSttOfChrgMdlNmr 11588;
BA_ "SPN" SG_ 2364660222 Hvsp5HghstCllSttOfChrgCllNmr 11589;
BA_ "SPN" SG_ 2364660222 Hvsp5LwstCllSttOfChrgMdlNmr 11590;
BA_ "SPN" SG_ 2364660222 Hvsp5LwstCllSttOfChrgCllNmr 11591;
BA_ "SPN" SG_ 2364660222 Hvsp5HghVltgBsAtvIsltnTstRslts 11592;
BA_ "SPN" SG_ 2364660222 Hvsp5HghVltgBsPssvIsltnTstRslts 11593;
BA_ "SPN" SG_ 2364660478 Hvesp5ActualChargeRate 13069;
BA_ "SPN" SG_ 2364660478 Hvsp5BsVltgNgtvTChsssGrndVltg 11594;
BA_ "SPN" SG_ 2364660478 Hvsp5VltgLvlNgtvTChsssGrndVltg 11595;
BA_ "SPN" SG_ 2364660734 Hvsp6DshrgPwrLmtDTSttOfChrg 11618;
BA_ "SPN" SG_ 2364660734 Hvsp6DshrgPwrLmtDTBttrTmprtr 11619;
BA_ "SPN" SG_ 2364660734 Hvsp6DsPwLtDTBttDstCdt 11620;
BA_ "SPN" SG_ 2364660734 Hvsp6DshrgPwrLmtDTBttrOrCllVltg 11621;
BA_ "SPN" SG_ 2364660734 Hvsp6DshrgPwrLmtDTBttrCrrnt 11622;
BA_ "SPN" SG_ 2364660734 Hvsp6DshrgPwrLmtDTAnUndfndCs 11623;
BA_ "SPN" SG_ 2364660734 Hvsp6ChrgPwrLmtDTSttOfChrg 11624;
BA_ "SPN" SG_ 2364660734 Hvsp6ChrgPwrLmtDTBttrTmprtr 11625;
BA_ "SPN" SG_ 2364660734 Hvsp6ChrgPwrLmtDTBttrDgnstCndtn 11626;
BA_ "SPN" SG_ 2364660734 Hvsp6ChrgPwrLmtDTBttrOrCllVltg 11627;
BA_ "SPN" SG_ 2364660734 Hvsp6ChrgPwrLmtDTBttrCrrnt 11628;
BA_ "SPN" SG_ 2364660734 Hvsp6ChrgPwrLmtDTAnUndfndCs 11629;
BA_ "SPN" SG_ 2364660990 Hvesp6AvailableDischargePower 11630;
BA_ "SPN" SG_ 2364660990 Hvesp6AvailableChargePower 11631;
BA_ "SPN" SG_ 2364660990 Hvesp6VoltageLevel 11632;
BA_ "SPN" SG_ 2364660990 Hvesp6Current 11633;
BA_ "SPN" SG_ 2364661246 Hvesp6FastUpdateStateOfCharge 11634;
BA_ "SPN" SG_ 2364661246 Hvesp6HighestCellVoltage 11635;
BA_ "SPN" SG_ 2364661246 Hvesp6LowestCellVoltage 11636;
BA_ "SPN" SG_ 2364661246 Hvsp6CllVltgDffrntlStts 11637;
BA_ "SPN" SG_ 2364661502 Hvesp6HighestCellTemperature 11638;
BA_ "SPN" SG_ 2364661502 Hvesp6LowestCellTemperature 11639;
BA_ "SPN" SG_ 2364661502 Hvesp6AverageCellTemperature 11640;
BA_ "SPN" SG_ 2364661502 Hvsp6CllTmprtrDffrntlStts 11641;
BA_ "SPN" SG_ 2364661758 Hvesp6DischargeCapacity 11642;
BA_ "SPN" SG_ 2364661758 Hvesp6ChargeCapacity 11643;
BA_ "SPN" SG_ 2364661758 Hvesp6CellBalancingCount 11644;
BA_ "SPN" SG_ 2364662014 Hvesp6LowestCellStateOfCharge 11647;
BA_ "SPN" SG_ 2364662014 Hvesp6HighestCellStateOfCharge 11648;
BA_ "SPN" SG_ 2364662014 Hvsp6MxmmInstntnsDshrgCrrntLmt 11645;
BA_ "SPN" SG_ 2364662014 Hvsp6MxmmInstntnsChrgCrrntLmt 11646;
BA_ "SPN" SG_ 2364662270 Hvesp6BusVoltage 11649;
BA_ "SPN" SG_ 2364662270 Hvesp6IgnitionVoltage 11650;
BA_ "SPN" SG_ 2364662270 Hvesp6IntakeCoolantTemperature 11651;
BA_ "SPN" SG_ 2364662270 Hvesp6OutletCoolantTemperature 11652;
BA_ "SPN" SG_ 2364662270 Hvesp6ElectronicsTemperature 11653;
BA_ "SPN" SG_ 2364662270 Hvesp6Temperature 11654;
BA_ "SPN" SG_ 2364662526 Hvesp6HvilStatus 11662;
BA_ "SPN" SG_ 2364662526 Hvesp6InertiaSwitchStatus 11663;
BA_ "SPN" SG_ 2364662526 Hvesp6StateOfChargeStatus 11664;
BA_ "SPN" SG_ 2364662526 Hvesp6CellBalanceStatus 11665;
BA_ "SPN" SG_ 2364662526 Hvesp6CellBalancingActive 11666;
BA_ "SPN" SG_ 2364662526 Hvesp6InternalChargerStatus 11667;
BA_ "SPN" SG_ 2364662526 Hvesp6OperationalStatus 11669;
BA_ "SPN" SG_ 2364662526 Hvesp6Status1Counter 13025;
BA_ "SPN" SG_ 2364662526 Hvesp6Status1Crc 13026;
BA_ "SPN" SG_ 2364662526 Hvsp6HghVltgBsPstvCnttrStt 11655;
BA_ "SPN" SG_ 2364662526 Hvsp6HghVltgBsNgtvCnttrStt 11656;
BA_ "SPN" SG_ 2364662526 Hvsp6HghVltgBsDsnntFrwrnng 11657;
BA_ "SPN" SG_ 2364662526 Hvsp6HghVltgBsPrChrgRlStt 11658;
BA_ "SPN" SG_ 2364662526 Hvsp6CntrOfPkCnttrStt 11659;
BA_ "SPN" SG_ 2364662526 Hvsp6HghVltgBsAtvIsltnTstStts 11660;
BA_ "SPN" SG_ 2364662526 Hvsp6HghVltgBsPssvIsltnTstStts 11661;
BA_ "SPN" SG_ 2364662526 Hvsp6HghVltgBsCnntnStts 11668;
BA_ "SPN" SG_ 2364662782 Hvesp6DischargeEnergyCapacity 11670;
BA_ "SPN" SG_ 2364662782 Hvesp6ChargeEnergyCapacity 11671;
BA_ "SPN" SG_ 2364662782 Hvesp6MaximumChargeVoltageLimit 11672;
BA_ "SPN" SG_ 2364663038 Hvesp6Module1OperationalStatus 11673;
BA_ "SPN" SG_ 2364663038 Hvesp6Module2OperationalStatus 11674;
BA_ "SPN" SG_ 2364663038 Hvesp6Module3OperationalStatus 11675;
BA_ "SPN" SG_ 2364663038 Hvesp6Module4OperationalStatus 11676;
BA_ "SPN" SG_ 2364663038 Hvesp6Module5OperationalStatus 11677;
BA_ "SPN" SG_ 2364663038 Hvesp6Module6OperationalStatus 11678;
BA_ "SPN" SG_ 2364663038 Hvesp6Module7OperationalStatus 11679;
BA_ "SPN" SG_ 2364663038 Hvesp6Module8OperationalStatus 11680;
BA_ "SPN" SG_ 2364663038 Hvesp6Module9OperationalStatus 11681;
BA_ "SPN" SG_ 2364663038 Hvesp6Module10OperationalStatus 11682;
BA_ "SPN" SG_ 2364663038 Hvesp6Module11OperationalStatus 11683;
BA_ "SPN" SG_ 2364663038 Hvesp6Module12OperationalStatus 11684;
BA_ "SPN" SG_ 2364663038 Hvesp6Module13OperationalStatus 11685;
BA_ "SPN" SG_ 2364663038 Hvesp6Module14OperationalStatus 11686;
BA_ "SPN" SG_ 2364663038 Hvesp6Module15OperationalStatus 11687;
BA_ "SPN" SG_ 2364663038 Hvesp6Module16OperationalStatus 11688;
BA_ "SPN" SG_ 2364663038 Hvesp6Module17OperationalStatus 14705;
BA_ "SPN" SG_ 2364663038 Hvesp6Module18OperationalStatus 14706;
BA_ "SPN" SG_ 2364663038 Hvesp6Module19OperationalStatus 14707;
BA_ "SPN" SG_ 2364663038 Hvesp6Module20OperationalStatus 14708;
BA_ "SPN" SG_ 2364663038 Hvesp6Module21OperationalStatus 14709;
BA_ "SPN" SG_ 2364663038 Hvesp6Module22OperationalStatus 14710;
BA_ "SPN" SG_ 2364663038 Hvesp6Module23OperationalStatus 14711;
BA_ "SPN" SG_ 2364663038 Hvesp6Module24OperationalStatus 14712;
BA_ "SPN" SG_ 2364663038 Hvesp6Module25OperationalStatus 14713;
BA_ "SPN" SG_ 2364663038 Hvesp6Module26OperationalStatus 14714;
BA_ "SPN" SG_ 2364663038 Hvesp6Module27OperationalStatus 14715;
BA_ "SPN" SG_ 2364663038 Hvesp6Module28OperationalStatus 14716;
BA_ "SPN" SG_ 2364663038 Hvesp6Module29OperationalStatus 14717;
BA_ "SPN" SG_ 2364663038 Hvesp6Module30OperationalStatus 14718;
BA_ "SPN" SG_ 2364663038 Hvesp6Module31OperationalStatus 14719;
BA_ "SPN" SG_ 2364663038 Hvesp6Module32OperationalStatus 14720;
BA_ "SPN" SG_ 2364663294 Hvsp6ThrmlMngmntSstmSlInptPwr 11689;
BA_ "SPN" SG_ 2364663294 Hvsp6TMtSstHVtIptPw 11690;
BA_ "SPN" SG_ 2364663294 Hvsp6ThrmlMngmntSstmCmprssrSpd 11691;
BA_ "SPN" SG_ 2364663294 Hvsp6ThrmlMngmntSstmRltvHmdt 11692;
BA_ "SPN" SG_ 2364663294 Hvsp6ThrmlMngmntSstmHtrStts 11693;
BA_ "SPN" SG_ 2364663294 Hvsp6ThrmlMngmntSstmHvlStts 12814;
BA_ "SPN" SG_ 2364663294 Hvsp6ThrmlMngmntSstmMd 11694;
BA_ "SPN" SG_ 2364663294 Hvsp6ThrmlMngmntSstmClntLvl 12903;
BA_ "SPN" SG_ 2364663550 Hvesp6AverageCellVoltage 11699;
BA_ "SPN" SG_ 2364663550 Hvsp6HghstCllVltgMdlNmr 11695;
BA_ "SPN" SG_ 2364663550 Hvsp6HghstCllVltgCllNmr 11696;
BA_ "SPN" SG_ 2364663550 Hvsp6LwstCllVltgMdlNmr 11697;
BA_ "SPN" SG_ 2364663550 Hvsp6LwstCllVltgCllNmr 11698;
BA_ "SPN" SG_ 2364663806 Hvsp6HghstCllTmprtrMdlNmr 11700;
BA_ "SPN" SG_ 2364663806 Hvsp6HghstCllTmprtrCllNmr 11701;
BA_ "SPN" SG_ 2364663806 Hvsp6LwstCllTmprtrMdlNmr 11702;
BA_ "SPN" SG_ 2364663806 Hvsp6LwstCllTmprtrCllNmr 11703;
BA_ "SPN" SG_ 2364663806 Hvess6ThermalEventDetected 21293;
BA_ "SPN" SG_ 2364663806 Hvsp6Dt9EmdddIntgrtSpprt 22989;
BA_ "SPN" SG_ 2364663806 Hvesp6Data9Counter 22990;
BA_ "SPN" SG_ 2364663806 Hvesp6Data9Crc 22991;
BA_ "SPN" SG_ 2364664062 Hvsp6HghstCllSttOfChrgMdlNmr 11704;
BA_ "SPN" SG_ 2364664062 Hvsp6HghstCllSttOfChrgCllNmr 11705;
BA_ "SPN" SG_ 2364664062 Hvsp6LwstCllSttOfChrgMdlNmr 11706;
BA_ "SPN" SG_ 2364664062 Hvsp6LwstCllSttOfChrgCllNmr 11707;
BA_ "SPN" SG_ 2364664062 Hvsp6HghVltgBsAtvIsltnTstRslts 11708;
BA_ "SPN" SG_ 2364664062 Hvsp6HghVltgBsPssvIsltnTstRslts 11709;
BA_ "SPN" SG_ 2364664318 Hvesp6ActualChargeRate 13070;
BA_ "SPN" SG_ 2364664318 Hvsp6BsVltgNgtvTChsssGrndVltg 11710;
BA_ "SPN" SG_ 2364664318 Hvsp6VltgLvlNgtvTChsssGrndVltg 11711;
BA_ "SPN" SG_ 2364664574 MtrGnrtr3InvrtrMdFdk1Cntr 11816;
BA_ "SPN" SG_ 2364664574 MtrGnrtr3InvrtrCntrlLmtsOvrrdMd 11817;
BA_ "SPN" SG_ 2364664574 MtrGnrtr3InvrtrCntrlStpntMd 11818;
BA_ "SPN" SG_ 2364664574 MtrGnrtr3InvrtrMdFdk1Cr 11815;
BA_ "SPN" SG_ 2364664574 MtrGnrtr3InvrtrHvlStts 11805;
BA_ "SPN" SG_ 2565991422 MtrGnrtr3InvrtrLmtsAtvPwrCntr 11834;
BA_ "SPN" SG_ 2565991422 MtGt3IvtLtsAtvMPwMx 11835;
BA_ "SPN" SG_ 2565991422 MtGt3IvtLtsAtvMPwM 11836;
BA_ "SPN" SG_ 2565991422 MtrGnrtr3InvrtrLmtsAtvPwrCr 11833;
BA_ "SPN" SG_ 2565991422 MtGt3IvtLtsAtvDSdPwMx 11837;
BA_ "SPN" SG_ 2565991422 MtGt3IvtLtsAtvDSdPwM 11838;
BA_ "SPN" SG_ 2565991678 MtrGnrtr3InvrtrLmtsAtvMhnlCntr 11846;
BA_ "SPN" SG_ 2565991678 MtrGnrtr3InvrtrLmtsAtvTrqMxmm 11847;
BA_ "SPN" SG_ 2565991678 MtrGnrtr3InvrtrLmtsAtvTrqMnmm 11848;
BA_ "SPN" SG_ 2565991678 MtrGnrtr3InvrtrLmtsAtvSpdMxmm 11849;
BA_ "SPN" SG_ 2565991678 MtrGnrtr3InvrtrLmtsAtvSpdMnmm 11850;
BA_ "SPN" SG_ 2565991678 MtrGnrtr3InvrtrLmtsAtvMhnlCr 11845;
BA_ "SPN" SG_ 2565991934 MtrGnrtr3InvrtrLmtsAtvDSdCr 11861;
BA_ "SPN" SG_ 2565991934 MtrGnrtr3InvrtrLmtsAtvDSdCntr 11862;
BA_ "SPN" SG_ 2565991934 MtGt3IvtLtsAtvDSdVtMx 11863;
BA_ "SPN" SG_ 2565991934 MtGt3IvtLtsAtvDSdVtM 11864;
BA_ "SPN" SG_ 2565991934 MtGt3IvtLtsAtvDSdCtMx 11865;
BA_ "SPN" SG_ 2565991934 MtGt3IvtLtsAtvDSdCtM 11866;
BA_ "SPN" SG_ 2565992190 MtrGnrtr3InvrtrSwthdIgntnVltg 11806;
BA_ "SPN" SG_ 2565992190 MtrGnrtr3InvrtrUnswthdSlVltg 11807;
BA_ "SPN" SG_ 2565992446 MtrGnrtr3InvrtrStts2Cntr 11875;
BA_ "SPN" SG_ 2565992446 MtrGnrtr3AvllMxmmTrq 11876;
BA_ "SPN" SG_ 2565992446 MtrGnrtr3AvllMnmmTrq 11877;
BA_ "SPN" SG_ 2565992446 MtrGnrtr3InvrtrStts2Cr 11874;
BA_ "SPN" SG_ 2565992702 MtrGnrtr3InvrtrRtLmtsAtv1Cntr 11909;
BA_ "SPN" SG_ 2565992702 MtGt3IvtRtLtsAtvAstSpdRtLt 11910;
BA_ "SPN" SG_ 2565992702 MtGt3IvtRtLtsAtvAstTqRtLt 11911;
BA_ "SPN" SG_ 2565992702 MtrGnrtr3InvrtrRtLmtsAtv1Cr 11908;
BA_ "SPN" SG_ 2364666366 MtrGnrtr4InvrtrMdFdk1Cntr 11934;
BA_ "SPN" SG_ 2364666366 MtrGnrtr4InvrtrCntrlLmtsOvrrdMd 11935;
BA_ "SPN" SG_ 2364666366 MtrGnrtr4InvrtrCntrlStpntMd 11936;
BA_ "SPN" SG_ 2364666366 MtrGnrtr4InvrtrMdFdk1Cr 11933;
BA_ "SPN" SG_ 2364666366 MtrGnrtr4InvrtrHvlStts 11923;
BA_ "SPN" SG_ 2565993214 MtrGnrtr4InvrtrLmtsAtvPwrCntr 11952;
BA_ "SPN" SG_ 2565993214 MtGt4IvtLtsAtvMPwMx 11953;
BA_ "SPN" SG_ 2565993214 MtGt4IvtLtsAtvMPwM 11954;
BA_ "SPN" SG_ 2565993214 MtrGnrtr4InvrtrLmtsAtvPwrCr 11951;
BA_ "SPN" SG_ 2565993214 MtGt4IvtLtsAtvDSdPwMx 11955;
BA_ "SPN" SG_ 2565993214 MtGt4IvtLtsAtvDSdPwM 11956;
BA_ "SPN" SG_ 2565993470 MtrGnrtr4InvrtrLmtsAtvMhnlCntr 11964;
BA_ "SPN" SG_ 2565993470 MtrGnrtr4InvrtrLmtsAtvTrqMxmm 11965;
BA_ "SPN" SG_ 2565993470 MtrGnrtr4InvrtrLmtsAtvTrqMnmm 11966;
BA_ "SPN" SG_ 2565993470 MtrGnrtr4InvrtrLmtsAtvSpdMxmm 11967;
BA_ "SPN" SG_ 2565993470 MtrGnrtr4InvrtrLmtsAtvSpdMnmm 11968;
BA_ "SPN" SG_ 2565993470 MtrGnrtr4InvrtrLmtsAtvMhnlCr 11963;
BA_ "SPN" SG_ 2565993726 MtrGnrtr4InvrtrLmtsAtvDSdCr 11979;
BA_ "SPN" SG_ 2565993726 MtrGnrtr4InvrtrLmtsAtvDSdCntr 11980;
BA_ "SPN" SG_ 2565993726 MtGt4IvtLtsAtvDSdVtMx 11981;
BA_ "SPN" SG_ 2565993726 MtGt4IvtLtsAtvDSdVtM 11982;
BA_ "SPN" SG_ 2565993726 MtGt4IvtLtsAtvDSdCtMx 11983;
BA_ "SPN" SG_ 2565993726 MtGt4IvtLtsAtvDSdCtM 11984;
BA_ "SPN" SG_ 2565993982 MtrGnrtr4InvrtrSwthdIgntnVltg 11924;
BA_ "SPN" SG_ 2565993982 MtrGnrtr4InvrtrUnswthdSlVltg 11925;
BA_ "SPN" SG_ 2565994238 MtrGnrtr4InvrtrStts2Cntr 11993;
BA_ "SPN" SG_ 2565994238 MtrGnrtr4AvllMxmmTrq 11994;
BA_ "SPN" SG_ 2565994238 MtrGnrtr4AvllMnmmTrq 11995;
BA_ "SPN" SG_ 2565994238 MtrGnrtr4InvrtrStts2Cr 11992;
BA_ "SPN" SG_ 2565994494 MtrGnrtr4InvrtrRtLmtsAtv1Cntr 12027;
BA_ "SPN" SG_ 2565994494 MtGt4IvtRtLtsAtvAstSpdRtLt 12028;
BA_ "SPN" SG_ 2565994494 MtGt4IvtRtLtsAtvAstTqRtLt 12029;
BA_ "SPN" SG_ 2565994494 MtrGnrtr4InvrtrRtLmtsAtv1Cr 12026;
BA_ "SPN" SG_ 2364668158 MtrGnrtr5InvrtrMdFdk1Cntr 12052;
BA_ "SPN" SG_ 2364668158 MtrGnrtr5InvrtrCntrlLmtsOvrrdMd 12053;
BA_ "SPN" SG_ 2364668158 MtrGnrtr5InvrtrCntrlStpntMd 12054;
BA_ "SPN" SG_ 2364668158 MtrGnrtr5InvrtrMdFdk1Cr 12051;
BA_ "SPN" SG_ 2364668158 MtrGnrtr5InvrtrHvlStts 12041;
